VERSION "5.0.7"

NS_ :

BS_:

BU_: BMS EAC EVCC FMCU CVC_P PDU PTC CCU DUMMY_ECU

BO_ 128 ACU_ChimeTelltaleReq: 8 CVC_P
 SG_ ACU_CheckSum : 7|8@0+ (1,0) [0|255] ""  FMCU,PDU,PTC,EAC,CCU,BMS
 SG_ ACU_AliveCounter : 11|4@0+ (1,0) [0|15] ""  FMCU,PDU,PTC,EAC,CCU,BMS
 SG_ ACU_In_Disposal_Mode : 13|2@0+ (1,0) [0|3] ""  FMCU,PDU,PTC,EAC,CCU
 SG_ ACU_Malfunction : 15|2@0+ (1,0) [0|3] ""  FMCU,PDU,PTC,EAC,CCU
 SG_ ACU_DAirbagStatus : 17|2@0+ (1,0) [0|3] ""  FMCU,PDU,PTC,EAC,CCU
 SG_ ACU_CoDAirbagStatus : 19|2@0+ (1,0) [0|3] ""  FMCU,PDU,PTC,EAC,CCU
 SG_ ACU_LCABsts : 21|2@0+ (1,0) [0|3] ""  FMCU,PDU,PTC,EAC,CCU
 SG_ ACU_RCABsts : 23|2@0+ (1,0) [0|3] ""  FMCU,PDU,PTC,EAC,CCU
 SG_ ACU_LSABsts : 25|2@0+ (1,0) [0|3] ""  FMCU,PDU,PTC,EAC,CCU
 SG_ ACU_RSABsts : 27|2@0+ (1,0) [0|3] ""  FMCU,PDU,PTC,EAC,CCU
 SG_ ACU_CrashSts : 29|2@0+ (1,0) [0|3] ""  FMCU,PDU,PTC,EAC,CCU,BMS
 SG_ ACU_Development_Calibration : 31|2@0+ (1,0) [0|3] ""  FMCU,PDU,PTC,EAC,CCU
 SG_ ACU_AirbagWarningStatus : 33|2@0+ (1,0) [0|3] ""  FMCU,PDU,PTC,EAC,CCU
 SG_ ACU_pyro_fuse_Stat : 35|2@0+ (1,0) [0|3] ""  FMCU,PDU,PTC,EAC,CCU
 SG_ ACU_Airbag_Disabled : 37|2@0+ (1,0) [0|3] ""  FMCU,PDU,PTC,EAC,CCU
 SG_ ACU_In_Plant_Mode : 39|2@0+ (1,0) [0|3] ""  FMCU,PDU,PTC,EAC,CCU
 SG_ ACU_PBA_InhibitSts : 41|2@0+ (1,0) [0|3] ""  FMCU,PDU,PTC,EAC,CCU
 SG_ ACU_Pre_Drive_Check : 43|2@0+ (1,0) [0|3] ""  FMCU,PDU,PTC,EAC,CCU
 SG_ ACU_CrashRearOutputSts : 49|2@0+ (1,0) [0|3] ""  FMCU,PDU,PTC,EAC,CCU
 SG_ ACU_CrashRightOutputSts : 51|2@0+ (1,0) [0|3] ""  FMCU,PDU,PTC,EAC,CCU
 SG_ ACU_CrashLeftOutputSts : 53|2@0+ (1,0) [0|3] ""  FMCU,PDU,PTC,EAC,CCU
 SG_ ACU_CrashFrontOutputSts : 55|2@0+ (1,0) [0|3] ""  FMCU,PDU,PTC,EAC,CCU

BO_ 170 CVC_Sts1: 8 CVC_P
 SG_ CHSKM_CVC_Sts1 : 7|8@0+ (1,0) [0|255] ""  BMS
 SG_ ALV_CVC_Sts1 : 11|4@0+ (1,0) [0|15] ""  BMS
 SG_ CVC_BMS_HVOnOff_REQ : 19|2@0+ (1,0) [0|1] ""  BMS

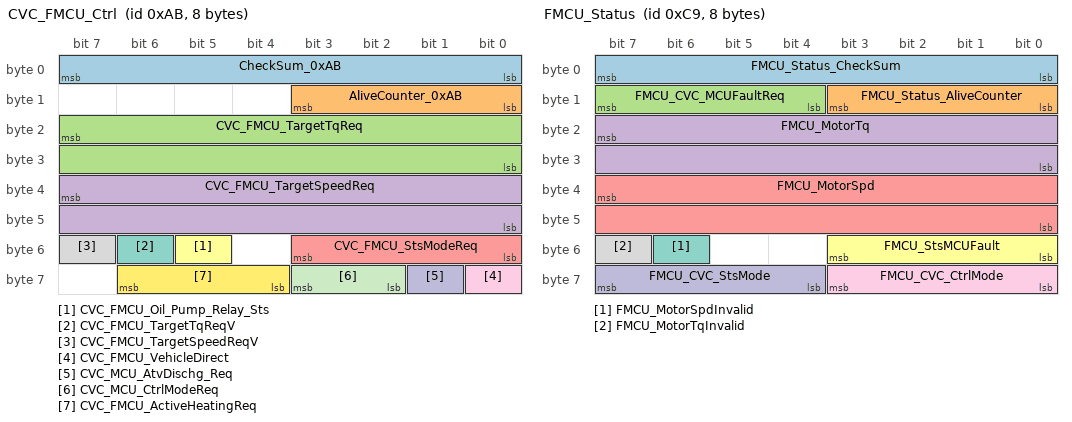
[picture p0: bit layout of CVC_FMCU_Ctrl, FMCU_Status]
BO_ 171 CVC_FMCU_Ctrl: 8 CVC_P
 SG_ CheckSum_0xAB : 7|8@0+ (1,0) [0|255] ""  FMCU
 SG_ AliveCounter_0xAB : 11|4@0+ (1,0) [0|15] ""  FMCU
 SG_ CVC_FMCU_TargetTqReq : 23|16@0+ (0.1,-400) [-400|400] "Nm"  FMCU
 SG_ CVC_FMCU_TargetSpeedReq : 39|16@0+ (1,-20000) [-20000|45535] "rpm"  FMCU
 SG_ CVC_FMCU_StsModeReq : 51|4@0+ (1,0) [0|15] ""  FMCU
 SG_ CVC_FMCU_Oil_Pump_Relay_Sts : 53|1@0+ (1,0) [0|1] ""  FMCU
 SG_ CVC_FMCU_TargetTqReqV : 54|1@0+ (1,0) [0|1] ""  FMCU
 SG_ CVC_FMCU_TargetSpeedReqV : 55|1@0+ (1,0) [0|1] ""  FMCU
 SG_ CVC_FMCU_VehicleDirect : 56|1@0+ (1,0) [0|1] ""  FMCU
 SG_ CVC_MCU_AtvDischg_Req : 57|1@0+ (1,0) [0|1] ""  FMCU
 SG_ CVC_MCU_CtrlModeReq : 59|2@0+ (1,0) [0|3] ""  FMCU
 SG_ CVC_FMCU_ActiveHeatingReq : 62|3@0+ (1,0) [0|8] "kW"  FMCU

BO_ 201 FMCU_Status: 8 FMCU
 SG_ FMCU_Status_CheckSum : 7|8@0+ (1,0) [0|255] ""  CVC_P,PDU,PTC,EAC
 SG_ FMCU_Status_AliveCounter : 11|4@0+ (1,0) [0|15] ""  CVC_P,PDU,PTC,EAC
 SG_ FMCU_CVC_MCUFaultReq : 15|4@0+ (1,0) [0|15] ""  CVC_P,PDU,PTC,EAC
 SG_ FMCU_MotorTq : 23|16@0+ (0.1,-400) [-400|400] "Nm"  CVC_P,PDU,PTC,EAC
 SG_ FMCU_MotorSpd : 39|16@0+ (1,-20000) [-20000|45531] "rpm"  CVC_P,PDU,PTC,EAC,EVCC,BMS,CCU
 SG_ FMCU_StsMCUFault : 51|4@0+ (1,0) [0|15] ""  CVC_P,PDU,PTC,EAC
 SG_ FMCU_MotorSpdInvalid : 54|1@0+ (1,0) [0|1] ""  CVC_P,PDU,PTC,EAC
 SG_ FMCU_MotorTqInvalid : 55|1@0+ (1,0) [0|1] ""  CVC_P,PDU,PTC,EAC
 SG_ FMCU_CVC_CtrlMode : 59|4@0+ (1,0) [0|15] ""  CVC_P,PDU,PTC,EAC
 SG_ FMCU_CVC_StsMode : 63|4@0+ (1,0) [0|15] ""  CVC_P,PDU,PTC,EAC

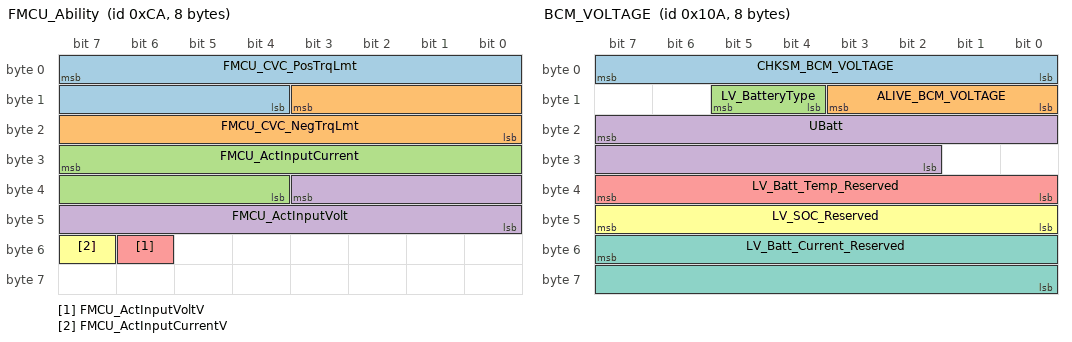
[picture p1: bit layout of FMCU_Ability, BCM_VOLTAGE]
BO_ 202 FMCU_Ability: 8 FMCU
 SG_ FMCU_CVC_PosTrqLmt : 7|12@0+ (0.1,0) [0|400] "Nm"  CVC_P,BMS
 SG_ FMCU_CVC_NegTrqLmt : 11|12@0+ (0.1,-400) [-400|0] "Nm"  CVC_P,BMS
 SG_ FMCU_ActInputCurrent : 31|12@0+ (0.5,-1000) [-1000|1000] "A"  CVC_P,BMS
 SG_ FMCU_ActInputVolt : 35|12@0+ (0.5,0) [0|1000] "V"  CVC_P,BMS
 SG_ FMCU_ActInputVoltV : 54|1@0+ (1,0) [0|1] ""  CVC_P,BMS
 SG_ FMCU_ActInputCurrentV : 55|1@0+ (1,0) [0|1] ""  CVC_P,BMS

BO_ 266 BCM_VOLTAGE: 8 CVC_P
 SG_ CHKSM_BCM_VOLTAGE : 7|8@0+ (1,0) [0|255] ""  EVCC,BMS,FMCU,PDU,CCU,PTC,EAC
 SG_ ALIVE_BCM_VOLTAGE : 11|4@0+ (1,0) [0|15] ""  EVCC,BMS,FMCU,PDU,CCU,PTC,EAC
 SG_ LV_BatteryType : 13|2@0+ (1,0) [0|3] "Number"  BMS,FMCU,PDU,CCU,PTC,EAC
 SG_ UBatt : 23|14@0+ (0.0009777,3) [3|18] "V"  EVCC,BMS,FMCU,PDU,CCU,PTC,EAC
 SG_ LV_Batt_Temp_Reserved : 39|8@0+ (1,-40) [-40|105] "Degree C"  BMS,FMCU,PDU,CCU,PTC,EAC
 SG_ LV_SOC_Reserved : 47|8@0+ (1,0) [0|100] "%"  BMS,FMCU,PDU,CCU,PTC,EAC
 SG_ LV_Batt_Current_Reserved : 55|16@0+ (0.03125,-1536) [-1536|511.90625] "A"  BMS,FMCU,PDU,CCU,PTC,EAC

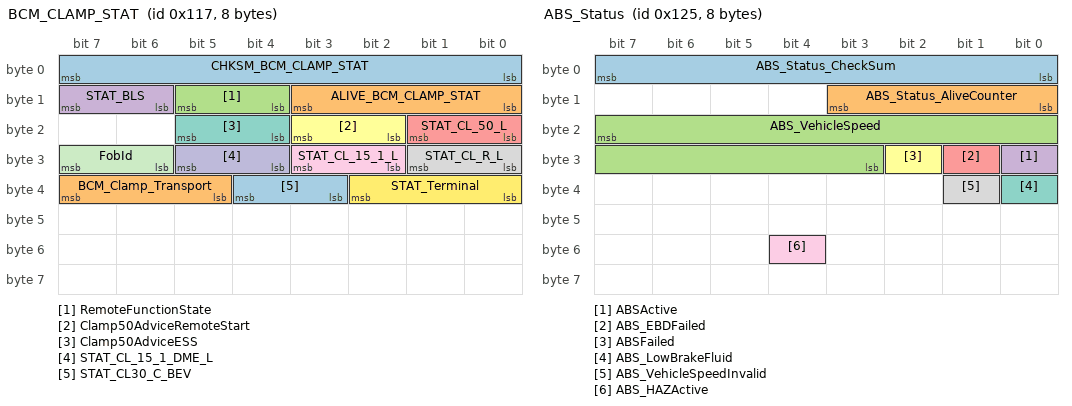
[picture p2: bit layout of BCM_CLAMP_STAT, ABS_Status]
BO_ 279 BCM_CLAMP_STAT: 8 CVC_P
 SG_ CHKSM_BCM_CLAMP_STAT : 7|8@0+ (1,0) [0|255] ""  EVCC,BMS
 SG_ ALIVE_BCM_CLAMP_STAT : 11|4@0+ (1,0) [0|15] ""  EVCC,BMS
 SG_ RemoteFunctionState : 13|2@0+ (1,0) [0|3] ""  EVCC,BMS
 SG_ STAT_BLS : 15|2@0+ (1,0) [0|3] "-"  EVCC,BMS
 SG_ STAT_CL_50_L : 17|2@0+ (1,0) [0|3] ""  EVCC,BMS
 SG_ Clamp50AdviceRemoteStart : 19|2@0+ (1,0) [0|3] "-"  EVCC,BMS
 SG_ Clamp50AdviceESS : 21|2@0+ (1,0) [0|3] "-"  EVCC,BMS
 SG_ STAT_CL_R_L : 25|2@0+ (1,0) [0|3] ""  EVCC,BMS
 SG_ STAT_CL_15_1_L : 27|2@0+ (1,0) [0|3] "-"  EVCC,BMS
 SG_ STAT_CL_15_1_DME_L : 29|2@0+ (1,0) [0|3] ""  EVCC,BMS
 SG_ FobId : 31|2@0+ (1,0) [0|3] "Bit"  EVCC,BMS
 SG_ STAT_Terminal : 34|3@0+ (1,0) [0|7] "Bit"  EVCC,BMS
 SG_ STAT_CL30_C_BEV : 36|2@0+ (1,0) [0|3] "Bit"  EVCC,BMS
 SG_ BCM_Clamp_Transport : 39|3@0+ (1,0) [0|7] ""  EVCC,BMS

BO_ 280 CVC_vehicle_118: 8 CVC_P
 SG_ CVC_VehicleSpeed : 7|13@0+ (0.05625,0) [0|270] "km/h"  PTC,BMS
 SG_ CVC_VehicleSpeedValid : 8|1@0+ (1,0) [0|1] ""  PTC,BMS
 SG_ CVC_HV_State : 10|2@0+ (1,0) [0|3] ""  PTC,BMS

BO_ 293 ABS_Status: 8 CVC_P
 SG_ ABS_Status_CheckSum : 7|8@0+ (1,0) [0|255] ""  FMCU,PDU,PTC,EAC,CCU,EVCC,BMS
 SG_ ABS_Status_AliveCounter : 11|4@0+ (1,0) [0|15] ""  FMCU,PDU,PTC,EAC,CCU,EVCC,BMS
 SG_ ABS_VehicleSpeed : 23|13@0+ (0.05625,0) [0|460.63125] "Km/h"  FMCU,PDU,PTC,EAC,CCU,EVCC,BMS
 SG_ ABSActive : 24|1@0+ (1,0) [0|1] ""  FMCU,PDU,PTC,EAC,CCU,EVCC,BMS
 SG_ ABS_EBDFailed : 25|1@0+ (1,0) [0|1] ""  FMCU,PDU,PTC,EAC,CCU,EVCC,BMS
 SG_ ABSFailed : 26|1@0+ (1,0) [0|1] ""  FMCU,PDU,PTC,EAC,CCU,EVCC,BMS
 SG_ ABS_LowBrakeFluid : 32|1@0+ (1,0) [0|1] ""  FMCU,PDU,PTC,EAC,CCU,EVCC,BMS
 SG_ ABS_VehicleSpeedInvalid : 33|1@0+ (1,0) [0|1] ""  FMCU,PDU,PTC,EAC,CCU,EVCC,BMS
 SG_ ABS_HAZActive : 52|1@0+ (1,0) [0|1] ""  FMCU,PDU,PTC,EAC,CCU,EVCC,BMS

BO_ 294 BMS_AllowChargeCurr: 8 BMS
 SG_ Checksum_0x126 : 7|8@0+ (1,0) [0|255] ""  CVC_P,EVCC
 SG_ Rolling_Counter_0x126 : 11|4@0+ (1,0) [0|15] ""  CVC_P,EVCC
 SG_ BMS_AllowChgCurr : 23|16@0+ (0.1,0) [0|1500] "A"  CVC_P,EVCC
 SG_ BMS_AllowChgCurrPeak : 39|16@0+ (0.1,0) [0|1500] "A"  CVC_P,EVCC

BO_ 296 BMS_AllowDischargeCurr: 8 BMS
 SG_ Checksum_0x128 : 7|8@0+ (1,0) [0|255] ""  CVC_P
 SG_ Rolling_Counter_0x128 : 11|4@0+ (1,0) [0|15] ""  CVC_P
 SG_ BMS_AllowDischgCurr : 23|16@0+ (0.1,0) [0|1500] "A"  CVC_P
 SG_ BMS_AllowDischgCurrPeak : 39|16@0+ (0.1,0) [0|1500] "A"  CVC_P

BO_ 306 ESC_Status_0x132: 8 CVC_P
 SG_ Checksum_0x132 : 7|8@0+ (1,0) [0|255] ""  FMCU
 SG_ RollingCounter_0x132 : 11|4@0+ (1,0) [0|15] ""  FMCU
 SG_ ESC_SlopeGradeAngle : 23|8@0+ (0.35433,-45) [-45|45] "%"  FMCU
 SG_ ESC_MasterCylinderPressure : 27|12@0+ (0.1,-100) [-100|309.4] "bar"  FMCU
 SG_ ESC_MasterCylinderPressureV : 28|1@0+ (1,0) [0|1] ""  FMCU
 SG_ ESC_HSA_Control_Status : 40|1@0+ (1,0) [0|1] ""  FMCU
 SG_ ESC_HSA_Status_Fault : 41|1@0+ (1,0) [0|1] ""  FMCU
 SG_ ESC_TcsDisableSts : 42|1@0+ (1,0) [0|1] ""  FMCU
 SG_ ESC_EscCtrlActv : 43|1@0+ (1,0) [0|1] ""  FMCU
 SG_ ESC_TcsCtrlActv : 44|1@0+ (1,0) [0|1] ""  FMCU
 SG_ ESC_EscFlgFlt : 45|1@0+ (1,0) [0|1] ""  FMCU
 SG_ ESC_TcsFlgFlt : 46|1@0+ (1,0) [0|1] ""  FMCU
 SG_ ESC_EscDisableSts : 47|1@0+ (1,0) [0|1] ""  FMCU
 SG_ ESC_HBAFlgFlt : 48|1@0+ (1,0) [0|1] ""  FMCU
 SG_ ESC_HbaCtrlActv : 49|1@0+ (1,0) [0|1] ""  FMCU
 SG_ BAS_FlgFlt : 50|1@0+ (1,0) [0|1] ""  FMCU
 SG_ BAS_CtrlActv : 51|1@0+ (1,0) [0|1] ""  FMCU
 SG_ IBS_ESCOFF_StsFB : 52|1@0+ (1,0) [0|1] ""  FMCU
 SG_ ESC_DTC_Active : 55|1@0+ (1,0) [0|1] ""  FMCU
 SG_ ESC_VehicleStandstill : 54|2@0+ (1,0) [0|3] ""  DUMMY_ECU

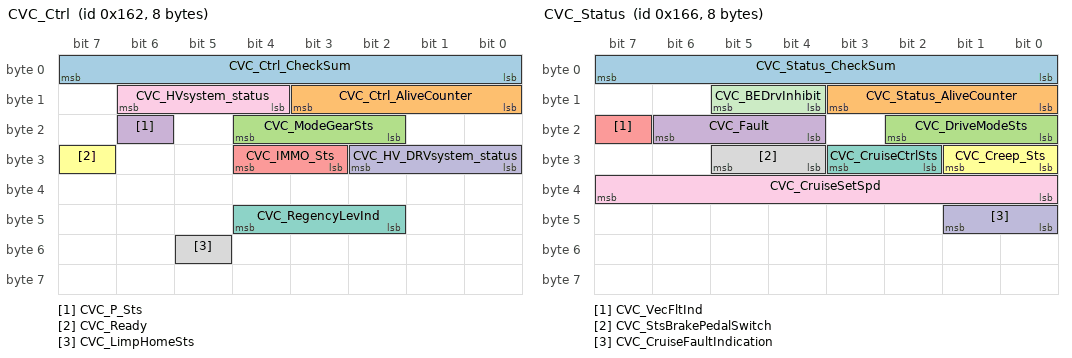
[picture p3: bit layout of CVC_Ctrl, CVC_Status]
BO_ 354 CVC_Ctrl: 8 CVC_P
 SG_ CVC_Ctrl_CheckSum : 7|8@0+ (1,0) [0|255] ""  FMCU,PDU,PTC,EAC,CCU,EVCC
 SG_ CVC_Ctrl_AliveCounter : 11|4@0+ (1,0) [0|15] ""  FMCU,PDU,PTC,EAC,CCU,EVCC
 SG_ CVC_ModeGearSts : 20|3@0+ (1,0) [0|7] ""  FMCU,PDU,PTC,EAC,CCU,EVCC
 SG_ CVC_P_Sts : 22|1@0+ (1,0) [0|1] ""  FMCU,PDU,PTC,EAC,CCU,EVCC
 SG_ CVC_IMMO_Sts : 28|2@0+ (1,0) [0|3] ""  FMCU,PDU,PTC,EAC,CCU,EVCC
 SG_ CVC_Ready : 31|1@0+ (1,0) [0|1] ""  FMCU,PDU,PTC,EAC,CCU,EVCC
 SG_ CVC_RegencyLevInd : 44|3@0+ (1,0) [0|7] ""  FMCU,PDU,PTC,EAC,CCU,EVCC
 SG_ CVC_LimpHomeSts : 53|1@0+ (1,0) [0|1] ""  FMCU,PDU,PTC,EAC,CCU,EVCC
 SG_ CVC_HVsystem_status : 14|3@0+ (1,0) [0|7] ""  FMCU,PDU,PTC,EAC,CCU,EVCC
 SG_ CVC_HV_DRVsystem_status : 26|3@0+ (1,0) [0|7] ""  FMCU,PDU,PTC,EAC,CCU,EVCC

BO_ 358 CVC_Status: 8 CVC_P
 SG_ CVC_Status_CheckSum : 7|8@0+ (1,0) [0|255] ""  FMCU
 SG_ CVC_Status_AliveCounter : 11|4@0+ (1,0) [0|15] ""  FMCU
 SG_ CVC_DriveModeSts : 18|3@0+ (1,0) [0|7] ""  FMCU
 SG_ CVC_Fault : 22|3@0+ (1,0) [0|7] ""  FMCU
 SG_ CVC_VecFltInd : 23|1@0+ (1,0) [0|1] ""  FMCU
 SG_ CVC_Creep_Sts : 25|2@0+ (1,0) [0|3] ""  FMCU
 SG_ CVC_CruiseCtrlSts : 27|2@0+ (1,0) [0|3] ""  FMCU
 SG_ CVC_StsBrakePedalSwitch : 29|2@0+ (1,0) [0|3] ""  FMCU
 SG_ CVC_CruiseSetSpd : 39|8@0+ (1,0) [30|120] ""  FMCU
 SG_ CVC_CruiseFaultIndication : 41|2@0+ (1,0) [0|3] ""  FMCU
 SG_ CVC_BEDrvInhibit : 13|2@0+ (1,0) [0|3] "" DUMMY_ECU

BO_ 1235 CVC_Debug: 8 CVC_P
 SG_ CHSKM_CVC_Debug : 7|8@0+ (1,0) [0|255] ""  DUMMY_ECU
 SG_ ALV_CVC_Debug : 11|4@0+ (1,0) [0|15] ""  DUMMY_ECU
 SG_ CVC_GearPOnlyAtStationaryAlert : 12|1@0+ (1,0) [0|1] ""  DUMMY_ECU
 SG_ CVC_GearP_NotPossibleAlert : 13|1@0+ (1,0) [0|1] ""  DUMMY_ECU
 SG_ CVC_PressBrakeToEngageGear : 14|1@0+ (1,0) [0|1] ""  DUMMY_ECU
 SG_ CVC_CantChangeGear : 15|1@0+ (1,0) [0|1] ""  DUMMY_ECU
 SG_ CVC_GearMalfunction : 16|1@0+ (1,0) [0|1] ""  DUMMY_ECU
 SG_ CVC_RangeAlert : 17|1@0+ (1,0) [0|1] ""  DUMMY_ECU
 SG_ CVC_HVSystemReduced : 18|1@0+ (1,0) [0|1] ""  DUMMY_ECU
 SG_ CVC_FrontEDSReduced : 19|1@0+ (1,0) [0|1] ""  DUMMY_ECU
 SG_ CVC_FrontEDS_Malfunc : 20|1@0+ (1,0) [0|1] ""  DUMMY_ECU
 SG_ CVC_RearEDSReduced : 21|1@0+ (1,0) [0|1] ""  DUMMY_ECU
 SG_ CVC_RearEDS_Malfunc : 22|1@0+ (1,0) [0|1] ""  DUMMY_ECU
 SG_ CVC_CoolingSystem_Malfunc : 45|3@0+ (1,0) [0|7] ""  DUMMY_ECU
 SG_ CVC_NeutralRequest : 24|1@0+ (1,0) [0|1] ""  DUMMY_ECU
 SG_ CVC_SoftShutdown : 25|1@0+ (1,0) [0|1] ""  DUMMY_ECU
 SG_ CVC_EmergencyShutdown : 26|1@0+ (1,0) [0|1] ""  DUMMY_ECU
 SG_ CVC_ChgPortDoorSys_Malfunc : 27|1@0+ (1,0) [0|1] ""  DUMMY_ECU
 SG_ CVC_Gearchange_NotPossible : 28|1@0+ (1,0) [0|1] ""  DUMMY_ECU
 SG_ CVC_12v_Warning : 29|1@0+ (1,0) [0|1] ""  DUMMY_ECU
 SG_ CVC_WflagRes19 : 30|1@0+ (1,0) [0|1] ""  DUMMY_ECU
 SG_ CVC_WflagRes20 : 31|1@0+ (1,0) [0|1] ""  DUMMY_ECU
 SG_ CVC_WflagRes21 : 32|1@0+ (1,0) [0|1] ""  DUMMY_ECU
 SG_ CVC_WflagRes22 : 33|1@0+ (1,0) [0|1] ""  DUMMY_ECU
 SG_ CVC_WflagRes23 : 34|1@0+ (1,0) [0|1] ""  DUMMY_ECU
 SG_ CVC_WflagRes24 : 35|1@0+ (1,0) [0|1] ""  DUMMY_ECU
 SG_ CVC_WflagRes25 : 36|1@0+ (1,0) [0|1] ""  DUMMY_ECU
 SG_ CVC_WflagRes26 : 37|1@0+ (1,0) [0|1] ""  DUMMY_ECU
 SG_ CVC_WflagRes27 : 38|1@0+ (1,0) [0|1] ""  DUMMY_ECU
 SG_ CVC_SuperFastCharge_longer : 39|1@0+ (1,0) [0|1] ""  DUMMY_ECU
 SG_ CVC_InvalidLimitSpeed : 46|1@0+ (1,0) [0|1] ""  DUMMY_ECU
 SG_ CVC_InvalidCruiseSpeed : 47|1@0+ (1,0) [0|1] ""  DUMMY_ECU
 SG_ CVC_Reserved_signal2 : 55|8@0+ (1,0) [0|255] ""  DUMMY_ECU
 SG_ CVC_Reserved_signal3 : 63|8@0+ (1,0) [0|255] ""  DUMMY_ECU

BO_ 1237 CVC_Debug_1: 8 CVC_P
 SG_ CVC_DebugAsw1 : 7|8@0+ (1,0) [0|255] ""  DUMMY_ECU
 SG_ CVC_DebugAsw2 : 10|3@0+ (1,0) [0|4] ""  DUMMY_ECU
 SG_ CVC_DebugAsw3 : 13|3@0+ (1,0) [0|4] ""  DUMMY_ECU
 SG_ CVC_DebugAsw4 : 18|3@0+ (1,0) [0|4] ""  DUMMY_ECU
 SG_ CVC_DebugAsw5 : 21|3@0+ (1,0) [0|4] ""  DUMMY_ECU
 SG_ CVC_DebugAsw6 : 28|3@0+ (1,0) [0|4] ""  DUMMY_ECU
 SG_ CVC_DebugAsw7 : 31|3@0+ (1,0) [0|4] ""  DUMMY_ECU
 SG_ CVC_DebugAsw8 : 55|3@0+ (1,0) [0|4] ""  DUMMY_ECU
 SG_ CVC_DebugAsw9 : 52|4@0+ (1,0) [0|15] ""  DUMMY_ECU
 SG_ CVC_DebugAsw10 : 63|4@0+ (1,0) [0|15] ""  DUMMY_ECU
 SG_ CVC_DebugAsw11 : 59|4@0+ (1,0) [0|15] ""  DUMMY_ECU
 SG_ CVC_DebugAsw12 : 39|8@0+ (1,0) [0|255] ""  DUMMY_ECU
 SG_ CVC_DebugAsw13 : 23|1@0+ (1,0) [0|1] ""  DUMMY_ECU
 SG_ CVC_DebugAsw14 : 22|1@0+ (1,0) [0|1] ""  DUMMY_ECU
 SG_ CVC_DebugAsw15 : 25|1@0+ (1,0) [0|1] ""  DUMMY_ECU
 SG_ CVC_DebugAsw16 : 24|1@0+ (1,0) [0|1] ""  DUMMY_ECU
 SG_ CVC_DebugAsw17 : 15|1@0+ (1,0) [0|1] ""  DUMMY_ECU
 SG_ CVC_DebugAsw18 : 14|1@0+ (1,0) [0|1] ""  DUMMY_ECU
 SG_ CVC_DebugAsw19 : 48|1@0+ (1,0) [0|1] ""  DUMMY_ECU

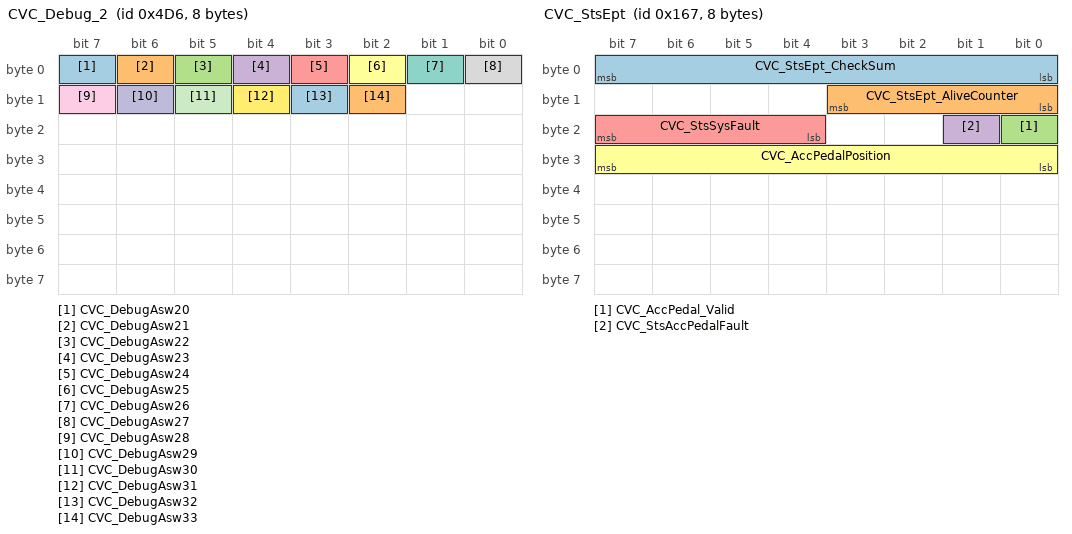
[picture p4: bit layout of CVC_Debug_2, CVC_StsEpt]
BO_ 1238 CVC_Debug_2: 8 CVC_P
 SG_ CVC_DebugAsw20 : 7|1@0+ (1,0) [0|1] ""  DUMMY_ECU
 SG_ CVC_DebugAsw21 : 6|1@0+ (1,0) [0|1] ""  DUMMY_ECU
 SG_ CVC_DebugAsw22 : 5|1@0+ (1,0) [0|1] ""  DUMMY_ECU
 SG_ CVC_DebugAsw23 : 4|1@0+ (1,0) [0|1] ""  DUMMY_ECU
 SG_ CVC_DebugAsw24 : 3|1@0+ (1,0) [0|1] ""  DUMMY_ECU
 SG_ CVC_DebugAsw25 : 2|1@0+ (1,0) [0|1] ""  DUMMY_ECU
 SG_ CVC_DebugAsw26 : 1|1@0+ (1,0) [0|1] ""  DUMMY_ECU
 SG_ CVC_DebugAsw27 : 0|1@0+ (1,0) [0|1] ""  DUMMY_ECU
 SG_ CVC_DebugAsw28 : 15|1@0+ (1,0) [0|1] ""  DUMMY_ECU
 SG_ CVC_DebugAsw29 : 14|1@0+ (1,0) [0|1] ""  DUMMY_ECU
 SG_ CVC_DebugAsw30 : 13|1@0+ (1,0) [0|1] ""  DUMMY_ECU
 SG_ CVC_DebugAsw31 : 12|1@0+ (1,0) [0|1] ""  DUMMY_ECU
 SG_ CVC_DebugAsw32 : 11|1@0+ (1,0) [0|1] ""  DUMMY_ECU
 SG_ CVC_DebugAsw33 : 10|1@0+ (1,0) [0|1] ""  DUMMY_ECU

BO_ 1873 CVC_DebugDiag: 8 CVC_P
 SG_ CVC_DebugDiag2 : 4|3@0+ (1,0) [0|4] ""  DUMMY_ECU
 SG_ CVC_DebugDiag1 : 7|3@0+ (1,0) [0|4] ""  DUMMY_ECU
 SG_ CVC_DebugDiag5 : 9|3@0+ (1,0) [0|4] ""  DUMMY_ECU
 SG_ CVC_DebugDiag4 : 12|3@0+ (1,0) [0|4] ""  DUMMY_ECU
 SG_ CVC_DebugDiag3 : 15|3@0+ (1,0) [0|4] ""  DUMMY_ECU
 SG_ CVC_DebugDiag8 : 16|3@0+ (1,0) [0|4] ""  DUMMY_ECU
 SG_ CVC_DebugDiag7 : 19|3@0+ (1,0) [0|4] ""  DUMMY_ECU
 SG_ CVC_DebugDiag6 : 22|3@0+ (1,0) [0|4] ""  DUMMY_ECU
 SG_ CVC_DebugDiag10 : 26|3@0+ (1,0) [0|4] ""  DUMMY_ECU
 SG_ CVC_DebugDiag9 : 29|3@0+ (1,0) [0|4] ""  DUMMY_ECU
 SG_ CVC_DebugDiag13 : 33|3@0+ (1,0) [0|4] ""  DUMMY_ECU
 SG_ CVC_DebugDiag12 : 36|3@0+ (1,0) [0|4] ""  DUMMY_ECU
 SG_ CVC_DebugDiag11 : 39|3@0+ (1,0) [0|4] ""  DUMMY_ECU
 SG_ CVC_DebugDiag16 : 40|3@0+ (1,0) [0|4] ""  DUMMY_ECU
 SG_ CVC_DebugDiag15 : 43|3@0+ (1,0) [0|4] ""  DUMMY_ECU
 SG_ CVC_DebugDiag14 : 46|3@0+ (1,0) [0|4] ""  DUMMY_ECU
 SG_ CVC_DebugDiag18 : 50|3@0+ (1,0) [0|4] ""  DUMMY_ECU
 SG_ CVC_DebugDiag17 : 53|3@0+ (1,0) [0|4] ""  DUMMY_ECU
 SG_ CVC_DebugDiag20 : 60|3@0+ (1,0) [0|4] ""  DUMMY_ECU
 SG_ CVC_DebugDiag19 : 63|3@0+ (1,0) [0|4] ""  DUMMY_ECU

BO_ 359 CVC_StsEpt: 8 CVC_P
 SG_ CVC_StsEpt_CheckSum : 7|8@0+ (1,0) [0|255] ""  FMCU
 SG_ CVC_StsEpt_AliveCounter : 11|4@0+ (1,0) [0|15] ""  FMCU
 SG_ CVC_AccPedal_Valid : 16|1@0+ (1,0) [0|1] ""  FMCU
 SG_ CVC_StsAccPedalFault : 17|1@0+ (1,0) [0|1] ""  FMCU
 SG_ CVC_StsSysFault : 23|4@0+ (1,0) [0|15] ""  FMCU
 SG_ CVC_AccPedalPosition : 31|8@0+ (0.4,0) [0|100] "%"  FMCU

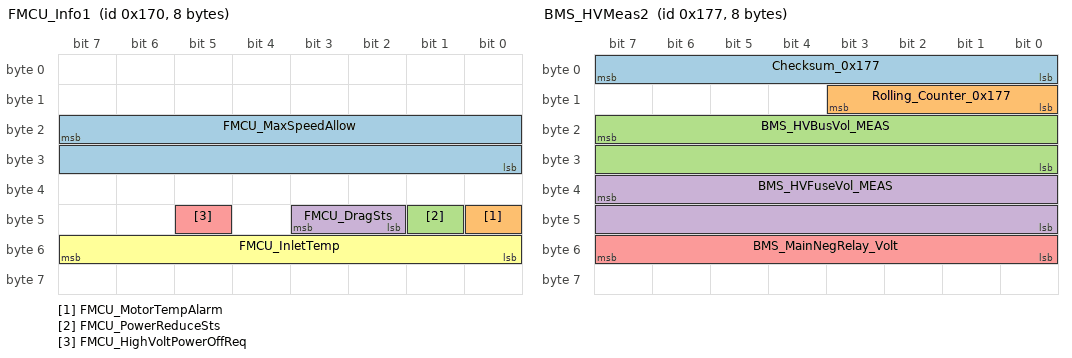
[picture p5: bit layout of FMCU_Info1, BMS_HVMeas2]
BO_ 368 FMCU_Info1: 8 FMCU
 SG_ FMCU_MaxSpeedAllow : 23|16@0+ (1,-17000) [-17000|17000] "rpm"  CVC_P
 SG_ FMCU_MotorTempAlarm : 40|1@0+ (1,0) [0|1] ""  CVC_P
 SG_ FMCU_PowerReduceSts : 41|1@0+ (1,0) [0|1] ""  CVC_P
 SG_ FMCU_DragSts : 43|2@0+ (1,0) [0|3] ""  CVC_P
 SG_ FMCU_HighVoltPowerOffReq : 45|1@0+ (1,0) [0|1] ""  CVC_P
 SG_ FMCU_InletTemp : 55|8@0+ (1,-50) [-50|200] "Degree C"  CVC_P

BO_ 372 BMS_CurMeas: 8 BMS
 SG_ CHSKM_BMS_CurMeas : 7|8@0+ (1,0) [0|255] ""  PDU,CVC_P,EVCC
 SG_ ALV_BMS_CurMeas : 11|4@0+ (1,0) [0|15] ""  PDU,CVC_P,EVCC
 SG_ BMS_StartOfMeasument_STS : 15|1@0+ (1,0) [0|1] ""  PDU,CVC_P
 SG_ BMS_PackCur_MEAS : 23|16@0+ (0.1,-3276.8) [-3276.8|3276.7] "A"  PDU,CVC_P,EVCC,FMCU

BO_ 374 BMS_HVMeas1: 8 BMS
 SG_ Checksum_0x176 : 7|8@0+ (1,0) [0|255] ""  FMCU,CVC_P,EVCC
 SG_ Rolling_Counter_0x176 : 11|4@0+ (1,0) [0|15] ""  FMCU,CVC_P,EVCC
 SG_ BMS_HVPackVol_MEAS : 23|16@0+ (0.1,0) [0|800] "V"  FMCU,CVC_P,EVCC
 SG_ BMS_HVLinkVol_MEAS : 39|16@0+ (0.1,0) [0|800] "V"  FMCU,CVC_P

BO_ 375 BMS_HVMeas2: 8 BMS
 SG_ Checksum_0x177 : 7|8@0+ (1,0) [0|255] ""  CVC_P,EVCC
 SG_ Rolling_Counter_0x177 : 11|4@0+ (1,0) [0|15] ""  CVC_P,EVCC
 SG_ BMS_HVBusVol_MEAS : 23|16@0+ (0.1,0) [0|800] "V"  CVC_P,EVCC
 SG_ BMS_HVFuseVol_MEAS : 39|16@0+ (0.1,0) [0|800] "V"  CVC_P,EVCC
 SG_ BMS_MainNegRelay_Volt : 55|8@0+ (0.1,0) [0|5] ""  CVC_P,EVCC

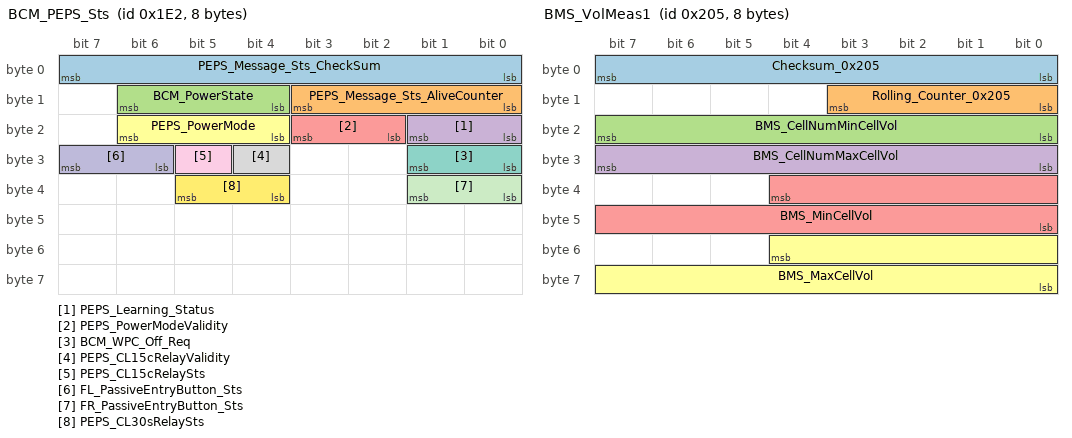
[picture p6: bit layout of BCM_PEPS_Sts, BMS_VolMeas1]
BO_ 482 BCM_PEPS_Sts: 8 CVC_P
 SG_ PEPS_Message_Sts_CheckSum : 7|8@0+ (1,0) [0|255] ""  PTC,BMS,FMCU,CCU
 SG_ PEPS_Message_Sts_AliveCounter : 11|4@0+ (1,0) [0|15] ""  PTC,BMS,FMCU,CCU
 SG_ BCM_PowerState : 14|3@0+ (1,0) [0|7] ""  PTC
 SG_ PEPS_Learning_Status : 17|2@0+ (1,0) [0|3] ""  PTC,BMS,FMCU,CCU
 SG_ PEPS_PowerModeValidity : 19|2@0+ (1,0) [0|3] ""  PTC,BMS,FMCU,CCU
 SG_ PEPS_PowerMode : 22|3@0+ (1,0) [0|7] ""  PTC,BMS,FMCU,CCU
 SG_ BCM_WPC_Off_Req : 25|2@0+ (1,0) [0|3] ""  PTC,BMS,FMCU,CCU
 SG_ PEPS_CL15cRelayValidity : 28|1@0+ (1,0) [0|1] ""  PTC,BMS,FMCU,CCU
 SG_ PEPS_CL15cRelaySts : 29|1@0+ (1,0) [0|1] ""  PTC,BMS,FMCU,CCU
 SG_ FL_PassiveEntryButton_Sts : 31|2@0+ (1,0) [0|3] "" DUMMY_ECU
 SG_ FR_PassiveEntryButton_Sts : 33|2@0+ (1,0) [0|3] "" DUMMY_ECU
 SG_ PEPS_CL30sRelaySts : 37|2@0+ (1,0) [0|3] "" DUMMY_ECU

BO_ 517 BMS_VolMeas1: 8 BMS
 SG_ Checksum_0x205 : 7|8@0+ (1,0) [0|255] ""  CVC_P
 SG_ Rolling_Counter_0x205 : 11|4@0+ (1,0) [0|15] ""  CVC_P
 SG_ BMS_CellNumMinCellVol : 23|8@0+ (1,0) [0|255] ""  CVC_P
 SG_ BMS_CellNumMaxCellVol : 31|8@0+ (1,0) [0|255] ""  CVC_P
 SG_ BMS_MinCellVol : 36|13@0+ (0.001,0) [0|6] "V"  CVC_P
 SG_ BMS_MaxCellVol : 52|13@0+ (0.001,0) [0|6] "V"  CVC_P

BO_ 518 BMS_VolMeas2: 8 BMS
 SG_ Checksum_0x206 : 7|8@0+ (1,0) [0|255] ""  CVC_P
 SG_ Rolling_Counter_0x206 : 11|4@0+ (1,0) [0|15] ""  CVC_P
 SG_ BMS_MaxMinDiffCellVol : 20|13@0+ (0.001,0) [0|2] "V"  CVC_P

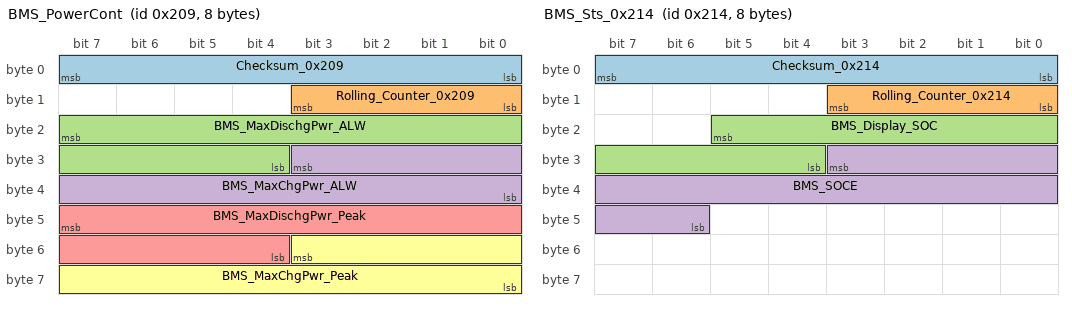
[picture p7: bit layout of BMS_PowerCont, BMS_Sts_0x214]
BO_ 521 BMS_PowerCont: 8 BMS
 SG_ Checksum_0x209 : 7|8@0+ (1,0) [0|255] ""  CVC_P,FMCU
 SG_ Rolling_Counter_0x209 : 11|4@0+ (1,0) [0|15] ""  CVC_P,FMCU
 SG_ BMS_MaxDischgPwr_ALW : 23|12@0+ (0.1,0) [0|400] "kW"  CVC_P,FMCU
 SG_ BMS_MaxChgPwr_ALW : 27|12@0+ (0.1,0) [0|400] "kW"  CVC_P,FMCU
 SG_ BMS_MaxDischgPwr_Peak : 47|12@0+ (0.2,0) [0|800] "kW"  CVC_P,FMCU
 SG_ BMS_MaxChgPwr_Peak : 51|12@0+ (0.2,0) [0|800] "kW"  CVC_P,FMCU

BO_ 532 BMS_Sts_0x214: 8 BMS
 SG_ Checksum_0x214 : 7|8@0+ (1,0) [0|255] ""  CVC_P,EVCC
 SG_ Rolling_Counter_0x214 : 11|4@0+ (1,0) [0|15] ""  CVC_P,EVCC
 SG_ BMS_Display_SOC : 21|10@0+ (0.1,0) [0|100] "%"  CVC_P,EVCC,FMCU
 SG_ BMS_SOCE : 27|14@0+ (0.01,0) [0|100] "%"  CVC_P

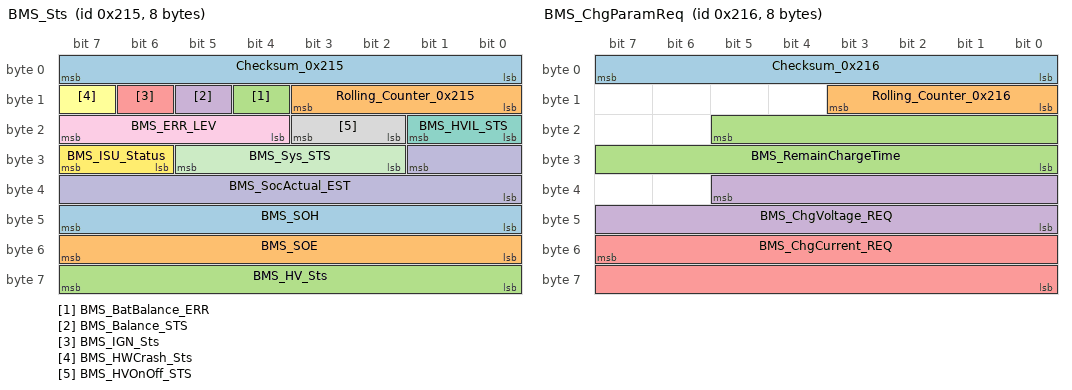
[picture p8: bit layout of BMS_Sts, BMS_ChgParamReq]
BO_ 533 BMS_Sts: 8 BMS
 SG_ Checksum_0x215 : 7|8@0+ (1,0) [0|255] ""  FMCU,PDU,CVC_P,EVCC,CCU
 SG_ Rolling_Counter_0x215 : 11|4@0+ (1,0) [0|15] ""  FMCU,PDU,CVC_P,EVCC,CCU
 SG_ BMS_BatBalance_ERR : 12|1@0+ (1,0) [0|1] ""  PDU,CVC_P,EVCC,CCU
 SG_ BMS_Balance_STS : 13|1@0+ (1,0) [0|1] ""  PDU,CVC_P,EVCC,FMCU,CCU
 SG_ BMS_IGN_Sts : 14|1@0+ (1,0) [0|1] ""  PDU,CVC_P,EVCC,CCU
 SG_ BMS_HWCrash_Sts : 15|1@0+ (1,0) [0|1] ""  PDU,CVC_P,EVCC,FMCU,CCU
 SG_ BMS_HVIL_STS : 17|2@0+ (1,0) [0|3] ""  PDU,CVC_P,EVCC,FMCU,CCU
 SG_ BMS_HVOnOff_STS : 19|2@0+ (1,0) [0|3] ""  PDU,CVC_P,EVCC,FMCU,CCU
 SG_ BMS_ERR_LEV : 23|4@0+ (1,0) [0|7] "-"  PDU,CVC_P,EVCC,FMCU,CCU
 SG_ BMS_SocActual_EST : 25|10@0+ (0.1,0) [0|100] "%"  PDU,CVC_P,EVCC,FMCU,CCU
 SG_ BMS_Sys_STS : 29|4@0+ (1,0) [0|15] ""  FMCU,PDU,CVC_P,EVCC,CCU
 SG_ BMS_ISU_Status : 31|2@0+ (1,0) [0|3] ""  PDU,CVC_P,EVCC,FMCU,CCU
 SG_ BMS_SOH : 47|8@0+ (0.5,0) [0|100] "%"  PDU,CVC_P,EVCC,FMCU,CCU
 SG_ BMS_SOE : 55|8@0+ (0.5,0) [0|100] "%"  PDU,CVC_P,EVCC,FMCU,CCU
 SG_ BMS_HV_Sts : 63|8@0+ (1,0) [0|255] ""  PDU,EVCC,CCU

BO_ 534 BMS_ChgParamReq: 8 BMS
 SG_ Checksum_0x216 : 7|8@0+ (1,0) [0|255] ""  CVC_P,EVCC
 SG_ Rolling_Counter_0x216 : 11|4@0+ (1,0) [0|15] ""  CVC_P,EVCC
 SG_ BMS_RemainChargeTime : 21|14@0+ (1,0) [0|16383] "min"  CVC_P,EVCC
 SG_ BMS_ChgVoltage_REQ : 37|14@0+ (0.1,0) [0|800] "V"  CVC_P,EVCC
 SG_ BMS_ChgCurrent_REQ : 55|16@0+ (0.1,0) [0|1500] "A"  CVC_P,EVCC

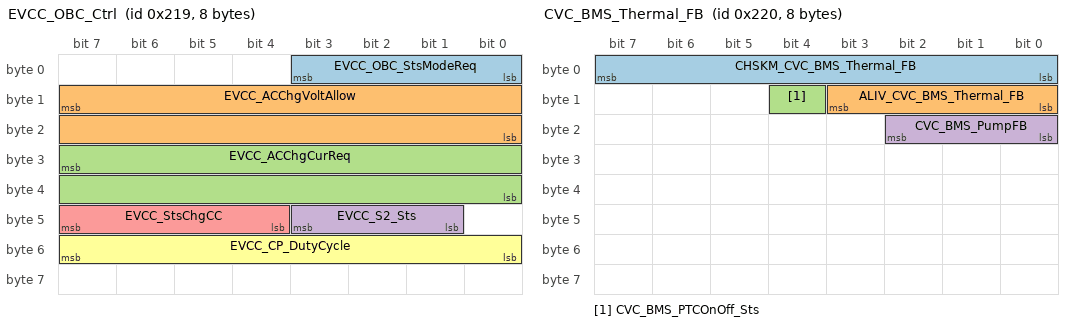
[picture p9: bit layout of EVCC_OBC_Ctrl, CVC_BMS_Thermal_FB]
BO_ 537 EVCC_OBC_Ctrl: 8 EVCC
 SG_ EVCC_OBC_StsModeReq : 3|4@0+ (1,0) [0|15] "-"  CVC_P,PDU
 SG_ EVCC_ACChgVoltAllow : 15|16@0+ (0.1,0) [0|1000] "V"  CVC_P,PDU
 SG_ EVCC_ACChgCurReq : 31|16@0+ (0.1,-1000) [-1000|1000] "A"  CVC_P,PDU
 SG_ EVCC_S2_Sts : 43|3@0+ (1,0) [0|7] "-"  CVC_P,PDU
 SG_ EVCC_StsChgCC : 47|4@0+ (1,0) [0|15] "-"  CVC_P,PDU
 SG_ EVCC_CP_DutyCycle : 55|8@0+ (0.4,0) [0|100] "%"  CVC_P,PDU

BO_ 544 CVC_BMS_Thermal_FB: 8 CVC_P
 SG_ CHSKM_CVC_BMS_Thermal_FB : 7|8@0+ (1,0) [0|255] ""  BMS
 SG_ ALIV_CVC_BMS_Thermal_FB : 11|4@0+ (1,0) [0|15] ""  BMS
 SG_ CVC_BMS_PTCOnOff_Sts : 12|1@0+ (1,0) [0|1] ""  BMS
 SG_ CVC_BMS_PumpFB : 18|3@0+ (1,0) [0|3] ""  BMS

BO_ 549 BMS_FaultMgr_0x225: 8 BMS
 SG_ Checksum_0x225 : 7|8@0+ (1,0) [0|255] ""  CVC_P
 SG_ Rolling_Counter_0x225 : 11|4@0+ (1,0) [0|15] ""  CVC_P
 SG_ CDM_bAcvCanComStblMon : 12|1@0+ (1,0) [0|1] ""  CVC_P
 SG_ FRMo_bErrHvbatStReqExtMon : 13|1@0+ (1,0) [0|1] ""  CVC_P
 SG_ FRMo_bErrChrgnAllwdExtMon : 14|1@0+ (1,0) [0|1] ""  CVC_P
 SG_ FRMo_bErrVehCrashStExtMon : 15|1@0+ (1,0) [0|1] ""  CVC_P
 SG_ CDM_bErrComctnLossCanMon : 16|1@0+ (1,0) [0|1] ""  CVC_P
 SG_ CTCMon_bErrCtctrSopcMon : 17|1@0+ (1,0) [0|1] ""  CVC_P
 SG_ CTCMon_bInvldCtctrHisdIFbMon : 18|1@0+ (1,0) [0|1] ""  CVC_P
 SG_ CTCMon_bInvldCtctrLosdUFbMon : 19|1@0+ (1,0) [0|1] ""  CVC_P
 SG_ CTM_bErrCellTDifMaxMon : 20|1@0+ (1,0) [0|1] ""  CVC_P
 SG_ CTM_bErrCellTMaxMon : 21|1@0+ (1,0) [0|1] ""  CVC_P
 SG_ CTM_bErrCellTMinMon : 22|1@0+ (1,0) [0|1] ""  CVC_P
 SG_ CTM_bErrThrwyPredMon : 23|1@0+ (1,0) [0|1] ""  CVC_P
 SG_ CUM_bErrCellUDifMaxMon : 24|1@0+ (1,0) [0|1] ""  CVC_P
 SG_ CUM_bErrCellUMaxMon : 25|1@0+ (1,0) [0|1] ""  CVC_P
 SG_ CUM_bErrCellUMinMon : 26|1@0+ (1,0) [0|1] ""  CVC_P
 SG_ CUM_bErrCellUProtnMaxNvMon : 27|1@0+ (1,0) [0|1] ""  CVC_P
 SG_ CUM_bErrCellUProtnMinNvMon : 28|1@0+ (1,0) [0|1] ""  CVC_P
 SG_ CUM_bErrPackUImplyMon : 29|1@0+ (1,0) [0|1] ""  CVC_P
 SG_ EHPMon_bRdyHvilMon : 30|1@0+ (1,0) [0|1] ""  CVC_P
 SG_ EHPMon_bErrWlddNegNvMon : 31|1@0+ (1,0) [0|1] ""  CVC_P
 SG_ EHPMon_bErrWlddPosNvMon : 32|1@0+ (1,0) [0|1] ""  CVC_P
 SG_ EHPMon_bErrWlddPrechNvMon : 33|1@0+ (1,0) [0|1] ""  CVC_P
 SG_ EHPMon_bErrHvilMon : 34|1@0+ (1,0) [0|1] ""  CVC_P
 SG_ EHPMon_bErrHvilShoMon : 35|1@0+ (1,0) [0|1] ""  CVC_P
 SG_ EHPMon_bErrPackIslnRNvMon : 36|1@0+ (1,0) [0|1] ""  CVC_P
 SG_ EHPMon_bErrVehCrashNvMon : 37|1@0+ (1,0) [0|1] ""  CVC_P
 SG_ EHPMon_bErrVehIslnRNvMon : 38|1@0+ (1,0) [0|1] ""  CVC_P
 SG_ FRMo_bErrMemStorgNvMon : 39|1@0+ (1,0) [0|1] ""  CVC_P
 SG_ L1IM_bErrClmp30MaxMonInp : 40|1@0+ (1,0) [0|1] ""  CVC_P
 SG_ L1IM_bErrClmp30MinMonInp : 41|1@0+ (1,0) [0|1] ""  CVC_P
 SG_ L1IM_bErrCtctrDtrtMonInp : 42|1@0+ (1,0) [0|1] ""  CVC_P
 SG_ L1IM_bErrUActImplyMonInp : 43|1@0+ (1,0) [0|1] ""  CVC_P
 SG_ MCCM_bAcvMdulCtlrStsMon : 44|1@0+ (1,0) [0|1] ""  CVC_P
 SG_ MCCM_bErrLntecSngFltMon : 45|1@0+ (1,0) [0|1] ""  CVC_P
 SG_ MCCM_bErrLntecLtntFltMon : 46|1@0+ (1,0) [0|1] ""  CVC_P
 SG_ MCCM_bErrMdulCellSnsrCfgMon : 47|1@0+ (1,0) [0|1] ""  CVC_P
 SG_ MCCM_bErrMdulCtlrComMon : 48|1@0+ (1,0) [0|1] ""  CVC_P
 SG_ MCCM_bErrSnsrTEltlMon : 49|1@0+ (1,0) [0|1] ""  CVC_P
 SG_ MCCM_bWarnSnsrTEltlMon : 50|1@0+ (1,0) [0|1] ""  CVC_P
 SG_ PCM_bRdySnsrIMon : 51|1@0+ (1,0) [0|1] ""  CVC_P
 SG_ PCM_bErrPackEFlowMaxLimMon : 52|1@0+ (1,0) [0|1] ""  CVC_P
 SG_ PCM_bErrPackIChDchaMaxLimMon : 53|1@0+ (1,0) [0|1] ""  CVC_P
 SG_ PCM_bErrSnsrIImplyMon : 54|1@0+ (1,0) [0|1] ""  CVC_P
 SG_ FRMo_bErrSnsrI1ExtMon : 55|1@0+ (1,0) [0|1] ""  CVC_P
 SG_ PCM_bInvldSnsrI1Mon : 56|1@0+ (1,0) [0|1] ""  CVC_P
 SG_ PCM_bInvldSnsrI2Mon : 57|1@0+ (1,0) [0|1] ""  CVC_P
 SG_ FRMo_bErrSopcLvl3Mon : 58|1@0+ (1,0) [0|1] ""  CVC_P
 SG_ BMS_FRMo_Reserved_1 : 59|1@0+ (1,0) [0|1] ""  CVC_P
 SG_ BMS_FRMo_Reserved_2 : 60|1@0+ (1,0) [0|1] ""  CVC_P
 SG_ BMS_FRMo_Reserved_3 : 61|1@0+ (1,0) [0|1] ""  CVC_P
 SG_ BMS_FRMo_Reserved_4 : 62|1@0+ (1,0) [0|1] ""  CVC_P
 SG_ BMS_FRMo_Reserved_5 : 63|1@0+ (1,0) [0|1] ""  CVC_P

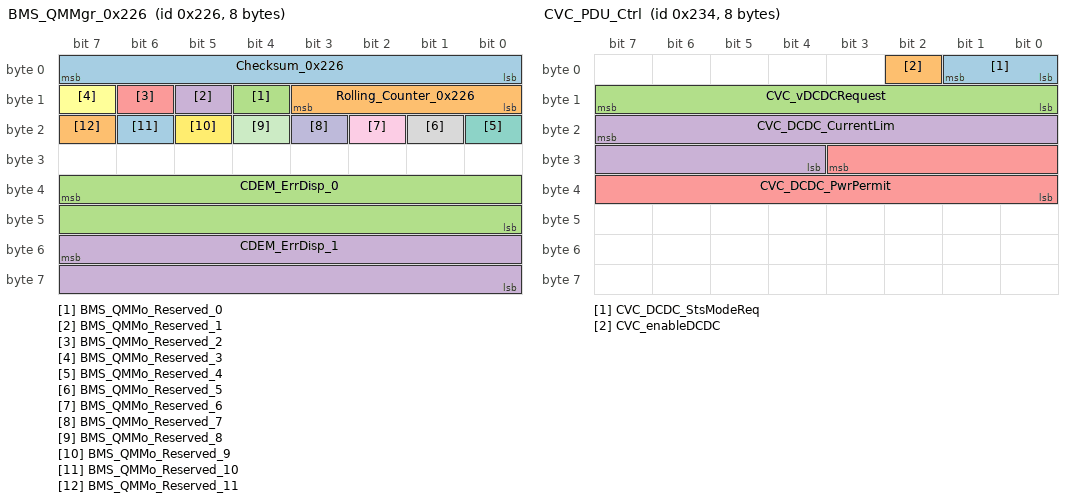
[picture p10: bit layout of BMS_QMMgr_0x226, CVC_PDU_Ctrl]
BO_ 550 BMS_QMMgr_0x226: 8 BMS
 SG_ Checksum_0x226 : 7|8@0+ (1,0) [0|255] "" Vector__XXX
 SG_ Rolling_Counter_0x226 : 11|4@0+ (1,0) [0|15] "" Vector__XXX
 SG_ BMS_QMMo_Reserved_0 : 12|1@0+ (1,0) [0|1] "" Vector__XXX
 SG_ BMS_QMMo_Reserved_1 : 13|1@0+ (1,0) [0|1] "" Vector__XXX
 SG_ BMS_QMMo_Reserved_2 : 14|1@0+ (1,0) [0|1] "" Vector__XXX
 SG_ BMS_QMMo_Reserved_3 : 15|1@0+ (1,0) [0|1] "" Vector__XXX
 SG_ BMS_QMMo_Reserved_4 : 16|1@0+ (1,0) [0|1] "" Vector__XXX
 SG_ BMS_QMMo_Reserved_5 : 17|1@0+ (1,0) [0|1] "" Vector__XXX
 SG_ BMS_QMMo_Reserved_6 : 18|1@0+ (1,0) [0|1] "" Vector__XXX
 SG_ BMS_QMMo_Reserved_7 : 19|1@0+ (1,0) [0|1] "" Vector__XXX
 SG_ BMS_QMMo_Reserved_8 : 20|1@0+ (1,0) [0|1] "" Vector__XXX
 SG_ BMS_QMMo_Reserved_9 : 21|1@0+ (1,0) [0|1] "" Vector__XXX
 SG_ BMS_QMMo_Reserved_10 : 22|1@0+ (1,0) [0|1] "" Vector__XXX
 SG_ BMS_QMMo_Reserved_11 : 23|1@0+ (1,0) [0|1] "" Vector__XXX
 SG_ CDEM_ErrDisp_0 : 39|16@0+ (1,0) [0|65535] "" Vector__XXX
 SG_ CDEM_ErrDisp_1 : 55|16@0+ (1,0) [0|65535] "" Vector__XXX

BO_ 563 CVC_FMCU_Limit: 8 CVC_P
 SG_ CVC_FMCU_Limit_CheckSum : 7|8@0+ (1,0) [0|255] ""  FMCU
 SG_ CVC_FMCU_Limit_AliveCounter : 11|4@0+ (1,0) [0|15] ""  FMCU
 SG_ CVC_FMCU_DischgPwrLim : 23|8@0+ (1,0) [0|250] "kw"  FMCU
 SG_ CVC_FMCU_RegenPwrLim : 31|8@0+ (1,0) [0|250] "kw"  FMCU

BO_ 564 CVC_PDU_Ctrl: 8 CVC_P
 SG_ CVC_DCDC_StsModeReq : 1|2@0+ (1,0) [0|3] ""  PDU
 SG_ CVC_enableDCDC : 2|1@0+ (1,0) [0|1] ""  PDU
 SG_ CVC_vDCDCRequest : 15|8@0+ (0.0625,0) [9|15.9375] "V"  PDU
 SG_ CVC_DCDC_CurrentLim : 23|12@0+ (0.1,0) [0|250] "A"  PDU
 SG_ CVC_DCDC_PwrPermit : 27|12@0+ (1,0) [0|3000] "W"  PDU

BO_ 568 FMCU_curSts: 8 FMCU
 SG_ FMCU_DampingState : 37|1@0+ (1,0) [0|1] ""  CVC_P
 SG_ FMCU_IGBTState : 39|2@0+ (1,0) [0|3] ""  CVC_P
 SG_ FMCU_ActualActiveHeatingPwr : 36|3@0+ (1,0) [0|8] "kW"  CVC_P

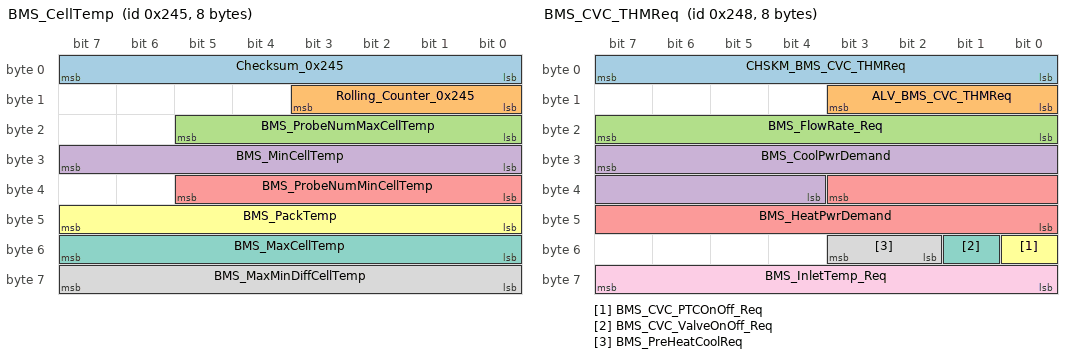
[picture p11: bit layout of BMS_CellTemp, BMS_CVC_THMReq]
BO_ 581 BMS_CellTemp: 8 BMS
 SG_ Checksum_0x245 : 7|8@0+ (1,0) [0|255] ""  PDU,CVC_P,EVCC
 SG_ Rolling_Counter_0x245 : 11|4@0+ (1,0) [0|15] ""  PDU,CVC_P,EVCC
 SG_ BMS_ProbeNumMaxCellTemp : 21|6@0+ (1,0) [0|63] ""  PDU,CVC_P
 SG_ BMS_MinCellTemp : 31|8@0+ (1,-40) [-40|215] "°C"  PDU,CVC_P
 SG_ BMS_ProbeNumMinCellTemp : 37|6@0+ (1,0) [0|63] ""  PDU,CVC_P
 SG_ BMS_PackTemp : 47|8@0+ (1,-40) [-40|215] "°C"  PDU,CVC_P,EVCC
 SG_ BMS_MaxCellTemp : 55|8@0+ (1,-40) [-40|215] "°C"  PDU,CVC_P
 SG_ BMS_MaxMinDiffCellTemp : 63|8@0+ (1,-40) [-40|215] "°C"  PDU,CVC_P

BO_ 584 BMS_CVC_THMReq: 8 BMS
 SG_ CHSKM_BMS_CVC_THMReq : 7|8@0+ (1,0) [0|255] ""  CVC_P
 SG_ ALV_BMS_CVC_THMReq : 11|4@0+ (1,0) [0|15] ""  CVC_P
 SG_ BMS_FlowRate_Req : 23|8@0+ (1,0) [0|50] "l/min"  CVC_P
 SG_ BMS_CoolPwrDemand : 31|12@0+ (0.1,0) [0|10] "kW"  CVC_P
 SG_ BMS_HeatPwrDemand : 35|12@0+ (0.1,0) [0|10] "kW"  CVC_P
 SG_ BMS_CVC_PTCOnOff_Req : 48|1@0+ (1,0) [0|1] ""  CVC_P
 SG_ BMS_CVC_ValveOnOff_Req : 49|1@0+ (1,0) [0|1] ""  CVC_P
 SG_ BMS_PreHeatCoolReq : 51|2@0+ (1,0) [0|3] ""  CVC_P
 SG_ BMS_InletTemp_Req : 63|8@0+ (0.5,0) [0|50] "℃"  CVC_P

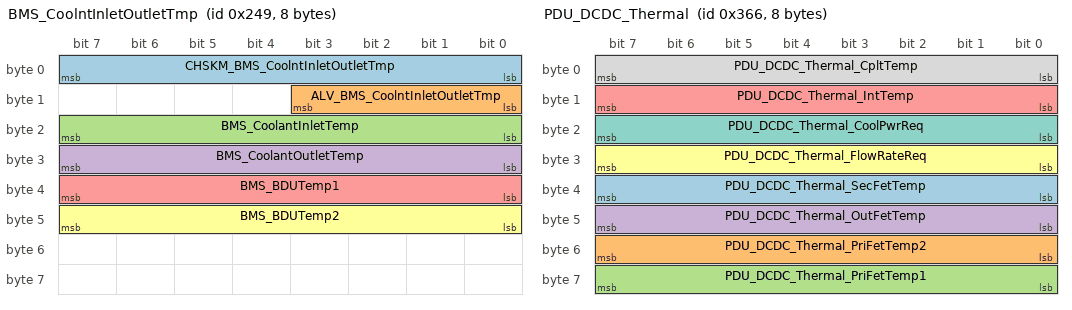
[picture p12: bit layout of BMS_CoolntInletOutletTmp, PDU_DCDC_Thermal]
BO_ 585 BMS_CoolntInletOutletTmp: 8 BMS
 SG_ CHSKM_BMS_CoolntInletOutletTmp : 7|8@0+ (1,0) [0|255] ""  PDU,CVC_P
 SG_ ALV_BMS_CoolntInletOutletTmp : 11|4@0+ (1,0) [0|15] ""  PDU,CVC_P
 SG_ BMS_CoolantInletTemp : 23|8@0+ (1,-40) [-40|215] "°C"  PDU,CVC_P
 SG_ BMS_CoolantOutletTemp : 31|8@0+ (1,-40) [-40|215] "°C"  PDU,CVC_P
 SG_ BMS_BDUTemp1 : 39|8@0+ (1,-40) [-40|215] "Degree C"  PDU,CVC_P
 SG_ BMS_BDUTemp2 : 47|8@0+ (1,-40) [-40|215] "°C"  PDU,CVC_P

BO_ 870 PDU_DCDC_Thermal: 8 PDU
 SG_ PDU_DCDC_Thermal_SecFetTemp : 39|8@0+ (1,-40) [-40|215] "oC" Vector__XXX
 SG_ PDU_DCDC_Thermal_PriFetTemp2 : 55|8@0+ (1,-40) [-40|215] "oC" Vector__XXX
 SG_ PDU_DCDC_Thermal_PriFetTemp1 : 63|8@0+ (1,-40) [-40|215] "oC" Vector__XXX
 SG_ PDU_DCDC_Thermal_OutFetTemp : 47|8@0+ (1,-40) [-40|215] "oC" Vector__XXX
 SG_ PDU_DCDC_Thermal_IntTemp : 15|8@0+ (1,-40) [-40|215] "oC" Vector__XXX
 SG_ PDU_DCDC_Thermal_FlowRateReq : 31|8@0+ (1,0) [0|50] "l/min" Vector__XXX
 SG_ PDU_DCDC_Thermal_CoolPwrReq : 23|8@0+ (0.1,0) [0|10] "KW" Vector__XXX
 SG_ PDU_DCDC_Thermal_CpltTemp : 7|8@0+ (1,-40) [-40|215] "oC" Vector__XXX

BO_ 526 BMS_FaultInfo: 8 BMS
 SG_ BMS_faultnumber : 7|64@0+ (1,0) [0|1.84467E+019] ""  CVC_P

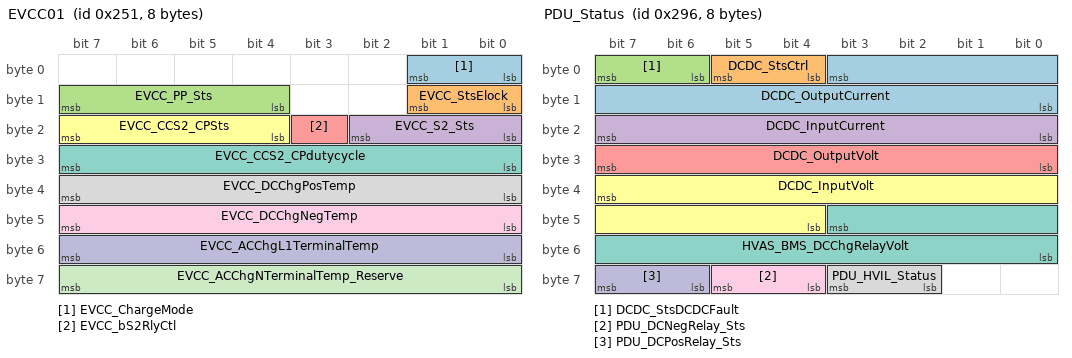
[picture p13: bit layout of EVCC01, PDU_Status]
BO_ 593 EVCC01: 8 EVCC
 SG_ EVCC_ChargeMode : 1|2@0+ (1,0) [0|3] "-"  CVC_P,BMS,PDU
 SG_ EVCC_StsElock : 9|2@0+ (1,0) [0|3] "-"  CVC_P,BMS,PDU
 SG_ EVCC_PP_Sts : 15|4@0+ (1,0) [0|15] ""  CVC_P,BMS,PDU
 SG_ EVCC_S2_Sts : 18|3@0+ (1,0) [0|7] "-"  CVC_P,BMS,PDU
 SG_ EVCC_bS2RlyCtl : 19|1@0+ (1,0) [0|1] "-"  CVC_P,BMS,PDU
 SG_ EVCC_CCS2_CPSts : 23|4@0+ (1,0) [0|15] ""  CVC_P,BMS,PDU
 SG_ EVCC_CCS2_CPdutycycle : 31|8@0+ (0.4,0) [0|100] "%"  CVC_P,BMS,PDU
 SG_ EVCC_DCChgPosTemp : 39|8@0+ (1,-40) [-40|210] "Degree C"  CVC_P,BMS,PDU
 SG_ EVCC_DCChgNegTemp : 47|8@0+ (1,-40) [-40|210] "Degree C"  CVC_P,BMS,PDU
 SG_ EVCC_ACChgL1TerminalTemp : 55|8@0+ (1,-40) [-40|210] "Degree C"  CVC_P,BMS,PDU
 SG_ EVCC_ACChgNTerminalTemp_Reserve : 63|8@0+ (1,-40) [-40|210] "Degree C"  CVC_P,BMS,PDU

BO_ 594 EVCC02: 8 EVCC
 SG_ EVCC_stPLCReqDc : 15|4@0+ (1,0) [0|15] ""  CVC_P,BMS,PDU
 SG_ EVCC_stPLCReqAc : 19|4@0+ (1,0) [0|15] ""  CVC_P,BMS,PDU

BO_ 662 PDU_Status: 8 PDU
 SG_ DCDC_OutputCurrent : 3|12@0+ (0.1,0) [0|250] "A"  CVC_P,EVCC
 SG_ DCDC_StsCtrl : 5|2@0+ (1,0) [0|3] "-"  CVC_P,EVCC
 SG_ DCDC_StsDCDCFault : 7|2@0+ (1,0) [0|3] "-"  CVC_P,EVCC
 SG_ DCDC_InputCurrent : 23|8@0+ (0.1,0) [0|25] "A"  CVC_P,EVCC
 SG_ DCDC_OutputVolt : 31|8@0+ (0.1,0) [0|25] "V"  CVC_P,EVCC
 SG_ DCDC_InputVolt : 39|12@0+ (0.5,0) [0|1000] "V"  CVC_P,EVCC
 SG_ HVAS_BMS_DCChgRelayVolt : 43|12@0+ (0.5,0) [0|1000] "V"  CVC_P,EVCC
 SG_ PDU_HVIL_Status : 59|2@0+ (1,0) [0|3] ""  CVC_P,EVCC
 SG_ PDU_DCNegRelay_Sts : 61|2@0+ (1,0) [0|3] ""  CVC_P,EVCC
 SG_ PDU_DCPosRelay_Sts : 63|2@0+ (1,0) [0|3] ""  CVC_P,EVCC

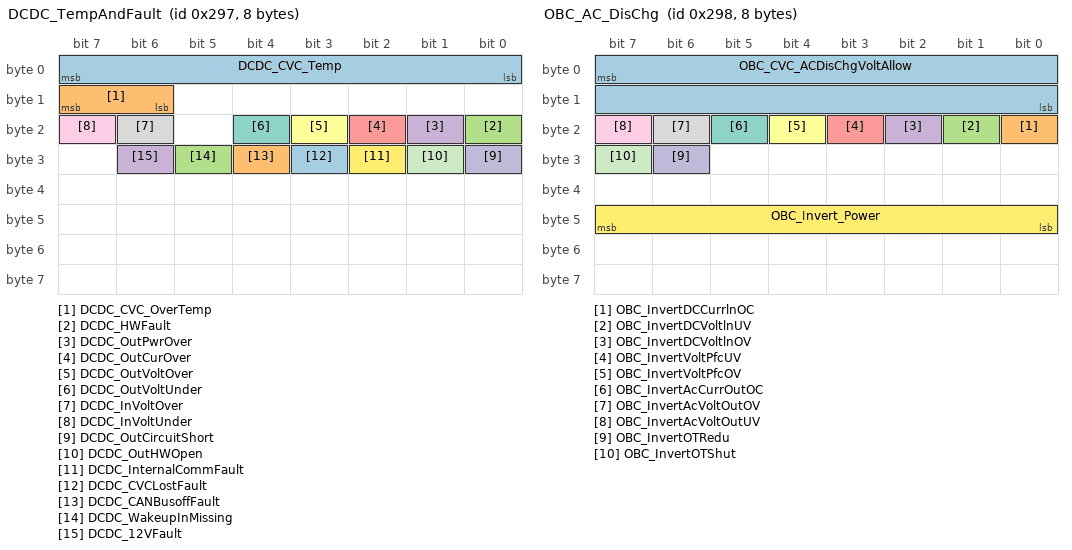
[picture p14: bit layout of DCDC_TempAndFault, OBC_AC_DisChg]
BO_ 663 DCDC_TempAndFault: 8 PDU
 SG_ DCDC_CVC_Temp : 7|8@0+ (1,-40) [-40|210] "Degree C"  CVC_P
 SG_ DCDC_CVC_OverTemp : 15|2@0+ (1,0) [0|3] ""  CVC_P
 SG_ DCDC_HWFault : 16|1@0+ (1,0) [0|1] ""  CVC_P
 SG_ DCDC_OutPwrOver : 17|1@0+ (1,0) [0|1] ""  CVC_P
 SG_ DCDC_OutCurOver : 18|1@0+ (1,0) [0|1] ""  CVC_P
 SG_ DCDC_OutVoltOver : 19|1@0+ (1,0) [0|1] ""  CVC_P
 SG_ DCDC_OutVoltUnder : 20|1@0+ (1,0) [0|1] ""  CVC_P
 SG_ DCDC_InVoltOver : 22|1@0+ (1,0) [0|1] ""  CVC_P
 SG_ DCDC_InVoltUnder : 23|1@0+ (1,0) [0|1] ""  CVC_P
 SG_ DCDC_OutCircuitShort : 24|1@0+ (1,0) [0|1] ""  CVC_P
 SG_ DCDC_OutHWOpen : 25|1@0+ (1,0) [0|1] ""  CVC_P
 SG_ DCDC_InternalCommFault : 26|1@0+ (1,0) [0|1] ""  CVC_P
 SG_ DCDC_CVCLostFault : 27|1@0+ (1,0) [0|1] ""  CVC_P
 SG_ DCDC_CANBusoffFault : 28|1@0+ (1,0) [0|1] ""  CVC_P
 SG_ DCDC_WakeupInMissing : 29|1@0+ (1,0) [0|1] ""  CVC_P
 SG_ DCDC_12VFault : 30|1@0+ (1,0) [0|1] ""  CVC_P

BO_ 664 OBC_AC_DisChg: 8 PDU
 SG_ OBC_CVC_ACDisChgVoltAllow : 7|16@0+ (0.1,0) [0|1000] "V"  CVC_P
 SG_ OBC_InvertDCCurrlnOC : 16|1@0+ (1,0) [0|1] ""  CVC_P
 SG_ OBC_InvertDCVoltlnUV : 17|1@0+ (1,0) [0|1] ""  CVC_P
 SG_ OBC_InvertDCVoltlnOV : 18|1@0+ (1,0) [0|1] ""  CVC_P
 SG_ OBC_InvertVoltPfcUV : 19|1@0+ (1,0) [0|1] ""  CVC_P
 SG_ OBC_InvertVoltPfcOV : 20|1@0+ (1,0) [0|1] ""  CVC_P
 SG_ OBC_InvertAcCurrOutOC : 21|1@0+ (1,0) [0|1] ""  CVC_P
 SG_ OBC_InvertAcVoltOutOV : 22|1@0+ (1,0) [0|1] ""  CVC_P
 SG_ OBC_InvertAcVoltOutUV : 23|1@0+ (1,0) [0|1] ""  CVC_P
 SG_ OBC_InvertOTRedu : 30|1@0+ (1,0) [0|1] ""  CVC_P
 SG_ OBC_InvertOTShut : 31|1@0+ (1,0) [0|1] ""  CVC_P
 SG_ OBC_Invert_Power : 47|8@0+ (0.1,0) [0|25] "Kw"  CVC_P

BO_ 666 PDU_DCDC_EventMatrix: 8 PDU
 SG_ PDU_DCDC_evt_reserved5 : 61|1@0+ (1,0) [0|1] "" Vector__XXX
 SG_ PDU_DCDC_evt_reserved6 : 62|1@0+ (1,0) [0|1] "" Vector__XXX
 SG_ PDU_DCDC_evt_reserved7 : 63|1@0+ (1,0) [0|1] "" Vector__XXX
 SG_ PDU_DCDC_evt_HVBat_UnderVolt_CMP : 41|1@0+ (1,0) [0|1] "" Vector__XXX
 SG_ PDU_DCDC_evt_LVOut_OverCurr_HW : 42|1@0+ (1,0) [0|1] "" Vector__XXX
 SG_ PDU_DCDC_evt_LVOut_OverVolt_HW : 43|1@0+ (1,0) [0|1] "" Vector__XXX
 SG_ PDU_DCDC_evt_LVOut_UnderVolt_SW : 44|1@0+ (1,0) [0|1] "" Vector__XXX
 SG_ PDU_DCDC_evt_LVOut_OverVolt_SW : 45|1@0+ (1,0) [0|1] "" Vector__XXX
 SG_ PDU_DCDC_evt_AuxPwrFlt_HW : 46|1@0+ (1,0) [0|1] "" Vector__XXX
 SG_ PDU_DCDC_evt_LVOut_UnderVolt_HW : 47|1@0+ (1,0) [0|1] "" Vector__XXX
 SG_ PDU_DCDC_evt_PFMFlt : 31|1@0+ (1,0) [0|1] "" Vector__XXX
 SG_ PDU_DCDC_evt_WdgFlt : 32|1@0+ (1,0) [0|1] "" Vector__XXX
 SG_ PDU_DCDC_evt_I2CComFlt : 33|1@0+ (1,0) [0|1] "" Vector__XXX
 SG_ PDU_DCDC_evt_SelfTestFlt : 35|1@0+ (1,0) [0|1] "" Vector__XXX
 SG_ PDU_DCDC_evt_LVOut_RevrsCurr_CMP : 36|1@0+ (1,0) [0|1] "" Vector__XXX
 SG_ PDU_DCDC_evt_LVBat_OverVolt_CMP : 37|1@0+ (1,0) [0|1] "" Vector__XXX
 SG_ PDU_DCDC_evt_LVBat_UnderVolt_CMP : 38|1@0+ (1,0) [0|1] "" Vector__XXX
 SG_ PDU_DCDC_evt_HVBat_OverVolt_CMP : 39|1@0+ (1,0) [0|1] "" Vector__XXX
 SG_ PDU_DCFC_evt_I2CDataWrong : 34|1@0+ (1,0) [0|1] "" Vector__XXX
 SG_ PDU_DCDC_evt_LVOut_RevrsCurr_SW : 16|1@0+ (1,0) [0|1] "" Vector__XXX
 SG_ PDU_DCDC_evt_TCANFlt : 30|1@0+ (1,0) [0|1] "" Vector__XXX
 SG_ PDU_DCDC_evt_LVOut_OverCurr_CMP : 29|1@0+ (1,0) [0|1] "" Vector__XXX
 SG_ PDU_DCDC_evt_Unchargeable : 28|1@0+ (1,0) [0|1] "" Vector__XXX
 SG_ PDU_DCDC_evt_ColdPlate_HighTemp : 27|1@0+ (1,0) [0|1] "" Vector__XXX
 SG_ PDU_DCDC_evt_Mosfet_HighTemp : 26|1@0+ (1,0) [0|1] "" Vector__XXX
 SG_ PDU_DCDC_evt_McuPwrFail : 25|1@0+ (1,0) [0|1] "" Vector__XXX
 SG_ PDU_DCDC_evt_LV_ShortOutputFlt : 24|1@0+ (1,0) [0|1] "" Vector__XXX
 SG_ PDU_DCDC_evt_Heater_SensorFlt : 17|1@0+ (1,0) [0|1] "" Vector__XXX
 SG_ PDU_DCDC_evt_Mosfet_TSensFail : 18|1@0+ (1,0) [0|1] "" Vector__XXX
 SG_ PDU_DCDC_evt_Mosfet_OverTemp : 19|1@0+ (1,0) [0|1] "" Vector__XXX
 SG_ PDU_DCDC_evt_Coldplate_TSensFail : 20|1@0+ (1,0) [0|1] "" Vector__XXX
 SG_ PDU_DCDC_evt_ColdPlate_OverTemp : 21|1@0+ (1,0) [0|1] "" Vector__XXX
 SG_ PDU_DCDC_evt_HeaterOverTemp : 22|1@0+ (1,0) [0|1] "" Vector__XXX
 SG_ PDU_DCDC_evt_HeaterShortIGBTFlt : 23|1@0+ (1,0) [0|1] "" Vector__XXX
 SG_ PDU_DCDC_evt_HVBat_UnderVolt_SW : 8|1@0+ (1,0) [0|1] "" Vector__XXX
 SG_ PDU_DCDC_evt_LVOut_VSensFail : 9|1@0+ (1,0) [0|1] "" Vector__XXX
 SG_ PDU_DCDC_evt_LVBat_OverVolt_SW : 10|1@0+ (1,0) [0|1] "" Vector__XXX
 SG_ PDU_DCDC_evt_LVBat_UnderVolt_SW : 11|1@0+ (1,0) [0|1] "" Vector__XXX
 SG_ PDU_DCDC_evt_LVBat_VSensFail : 12|1@0+ (1,0) [0|1] "" Vector__XXX
 SG_ PDU_DCDC_evt_LV_RedundancyFlt : 13|1@0+ (1,0) [0|1] "" Vector__XXX
 SG_ PDU_DCDC_evt_LVOut_ISensFail : 14|1@0+ (1,0) [0|1] "" Vector__XXX
 SG_ PDU_DCDC_evt_LVOut_OverCurr_SW : 15|1@0+ (1,0) [0|1] "" Vector__XXX
 SG_ PDU_DCDC_evt_BUS_OFF : 0|1@0+ (1,0) [0|1] "" Vector__XXX
 SG_ PDU_DCDC_evt_MIA : 1|1@0+ (1,0) [0|1] "" Vector__XXX
 SG_ PDU_DCDC_evt_E2E : 2|1@0+ (1,0) [0|1] "" Vector__XXX
 SG_ PDU_DCDC_evt_CalibFlt : 3|1@0+ (1,0) [0|1] "" Vector__XXX
 SG_ PDU_DCDC_evt_ExtMemFlt : 4|1@0+ (1,0) [0|1] "" Vector__XXX
 SG_ PDU_DCDC_evt_FaultLatchCircuit : 5|1@0+ (1,0) [0|1] "" Vector__XXX
 SG_ PDU_DCDC_evt_HVBat_VSensFail : 6|1@0+ (1,0) [0|1] "" Vector__XXX
 SG_ PDU_DCDC_evt_HVBat_OverVolt_SW : 7|1@0+ (1,0) [0|1] "" Vector__XXX
 SG_ PDU_DCDC_evt_reserved4 : 60|1@0+ (1,0) [0|255] "" Vector__XXX
 SG_ PDU_DCDC_evt_reserved3 : 59|1@0+ (1,0) [0|255] "" Vector__XXX
 SG_ PDU_DCDC_evt_reserved2 : 58|1@0+ (1,0) [0|255] "" Vector__XXX
 SG_ PDU_DCDC_evt_reserved1 : 57|1@0+ (1,0) [0|255] "" Vector__XXX
 SG_ PDU_DCDC_evt_reserved0 : 56|1@0+ (1,0) [0|255] "" Vector__XXX

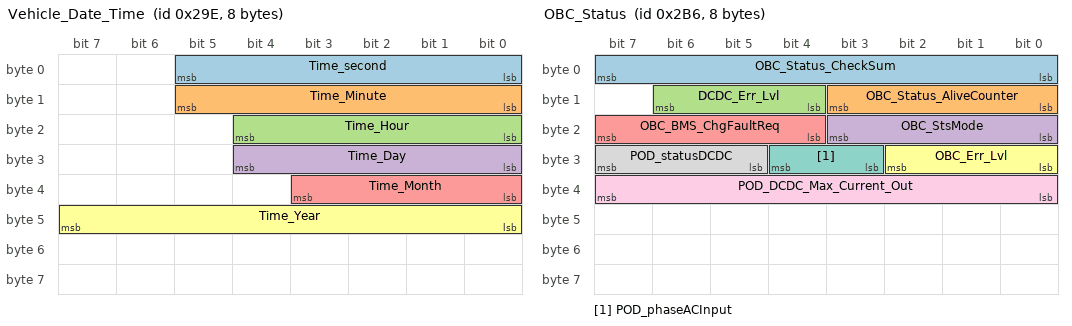
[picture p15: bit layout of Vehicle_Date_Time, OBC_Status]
BO_ 670 Vehicle_Date_Time: 8 CVC_P
 SG_ Time_second : 5|6@0+ (1,0) [0|59] "second"  BMS,FMCU,PDU,PTC,EAC,CCU,EVCC
 SG_ Time_Minute : 13|6@0+ (1,0) [0|59] "min"  BMS,FMCU,PDU,PTC,EAC,CCU,EVCC
 SG_ Time_Hour : 20|5@0+ (1,0) [0|23] "hour"  BMS,FMCU,PDU,PTC,EAC,CCU,EVCC
 SG_ Time_Day : 28|5@0+ (1,0) [1|31] "day"  BMS,FMCU,PDU,PTC,EAC,CCU,EVCC
 SG_ Time_Month : 35|4@0+ (1,0) [1|12] "month"  BMS,FMCU,PDU,PTC,EAC,CCU,EVCC
 SG_ Time_Year : 47|8@0+ (1,2000) [2000|2200] "year"  BMS,FMCU,PDU,PTC,EAC,CCU,EVCC

BO_ 694 OBC_Status: 8 PDU
 SG_ OBC_Status_CheckSum : 7|8@0+ (1,0) [0|255] "-"  CVC_P
 SG_ OBC_Status_AliveCounter : 11|4@0+ (1,0) [0|15] "-"  CVC_P
 SG_ DCDC_Err_Lvl : 14|3@0+ (1,0) [0|7] "-"  CVC_P
 SG_ OBC_StsMode : 19|4@0+ (1,0) [0|15] "-"  CVC_P,EVCC
 SG_ OBC_BMS_ChgFaultReq : 23|4@0+ (1,0) [0|15] "-"  CVC_P
 SG_ OBC_Err_Lvl : 26|3@0+ (1,0) [0|7] "-"  CVC_P,EVCC
 SG_ POD_phaseACInput : 28|2@0+ (1,0) [0|3] "-"  CVC_P,EVCC
 SG_ POD_statusDCDC : 31|3@0+ (1,0) [0|7] "-"  CVC_P
 SG_ POD_DCDC_Max_Current_Out : 39|8@0+ (1,0) [0|250] "A"  CVC_P

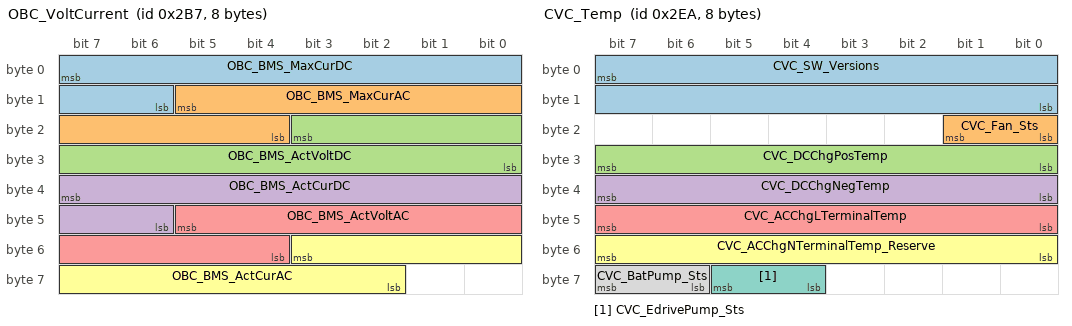
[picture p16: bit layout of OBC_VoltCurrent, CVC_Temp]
BO_ 695 OBC_VoltCurrent: 8 PDU
 SG_ OBC_BMS_MaxCurDC : 7|10@0+ (0.1,0) [0|100] "A"  CVC_P,EVCC
 SG_ OBC_BMS_MaxCurAC : 13|10@0+ (0.1,0) [0|100] "A"  CVC_P,EVCC
 SG_ OBC_BMS_ActVoltDC : 19|12@0+ (0.5,0) [0|1000] "V"  CVC_P,EVCC
 SG_ OBC_BMS_ActCurDC : 39|10@0+ (0.1,0) [0|100] "A"  CVC_P,EVCC
 SG_ OBC_BMS_ActVoltAC : 45|10@0+ (0.5,0) [0|500] "V"  CVC_P,EVCC
 SG_ OBC_BMS_ActCurAC : 51|10@0+ (0.1,0) [0|100] "A"  CVC_P,EVCC

BO_ 746 CVC_Temp: 8 CVC_P
 SG_ CVC_SW_Versions : 7|16@0+ (1,0) [0|255] "" Vector__XXX
 SG_ CVC_Fan_Sts : 17|2@0+ (1,0) [0|3] "" Vector__XXX
 SG_ CVC_DCChgPosTemp : 31|8@0+ (1,-40) [-40|210] "Degree C" Vector__XXX
 SG_ CVC_DCChgNegTemp : 39|8@0+ (1,-40) [-40|210] "Degree C" Vector__XXX
 SG_ CVC_ACChgLTerminalTemp : 47|8@0+ (1,-40) [-40|210] "Degree C" Vector__XXX
 SG_ CVC_ACChgNTerminalTemp_Reserve : 55|8@0+ (1,-40) [-40|210] "Degree C" Vector__XXX
 SG_ CVC_EdrivePump_Sts : 61|2@0+ (1,0) [0|3] "" Vector__XXX
 SG_ CVC_BatPump_Sts : 63|2@0+ (1,0) [0|3] "" Vector__XXX

BO_ 773 BMS_Insulation: 8 BMS
 SG_ CHSKM_BMS_Insulation : 7|8@0+ (1,0) [0|255] ""  CVC_P,EVCC
 SG_ ALV_BMS_Insulation : 11|4@0+ (1,0) [0|15] ""  CVC_P,EVCC
 SG_ BMS_CVC_Insulation_Mon_Sts : 15|1@0+ (1,0) [0|1] ""  CVC_P,EVCC
 SG_ BMS_PackInsuRes : 23|16@0+ (1,0) [0|60000] "kOhm"  CVC_P,EVCC

BO_ 775 BMS_Sensor_Start_Stop_0x307: 8 BMS
 SG_ Checksum_0x307 : 7|8@0+ (1,0) [0|255] ""  CVC_P
 SG_ Rolling_Counter_0x307 : 11|4@0+ (1,0) [0|15] ""  CVC_P
 SG_ BMS_Start_Stop_DM13 : 17|2@0+ (1,0) [0|3] ""  CVC_P

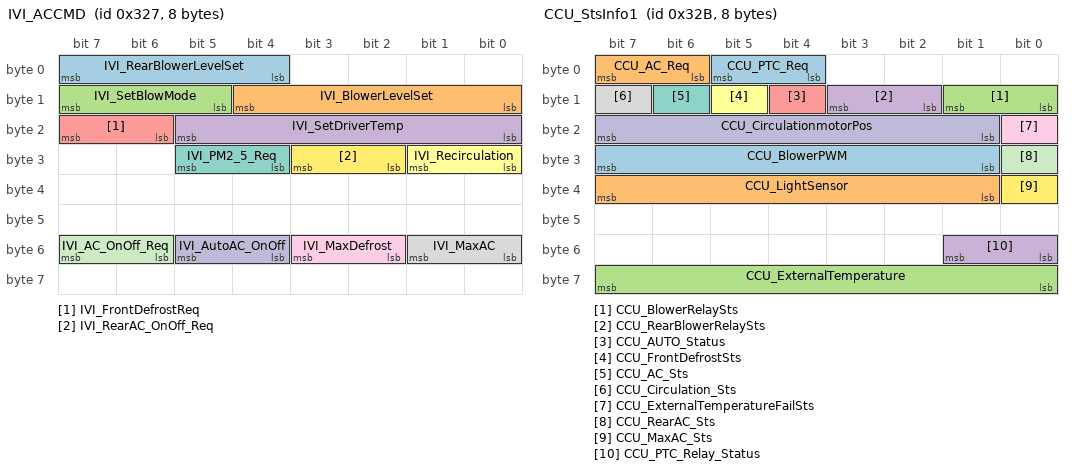
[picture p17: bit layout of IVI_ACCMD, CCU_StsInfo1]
BO_ 807 IVI_ACCMD: 8 CVC_P
 SG_ IVI_RearBlowerLevelSet : 7|4@0+ (1,0) [0|7] ""  CCU
 SG_ IVI_BlowerLevelSet : 12|5@0+ (1,0) [0|9] ""  CCU
 SG_ IVI_SetBlowMode : 15|3@0+ (1,0) [0|7] ""  CCU
 SG_ IVI_SetDriverTemp : 21|6@0+ (0.5,10) [16|32] ""  CCU
 SG_ IVI_FrontDefrostReq : 23|2@0+ (1,0) [0|3] ""  CCU
 SG_ IVI_Recirculation : 25|2@0+ (1,0) [0|3] ""  CCU
 SG_ IVI_PM2_5_Req : 29|2@0+ (1,0) [0|3] ""  CCU
 SG_ IVI_MaxAC : 49|2@0+ (1,0) [0|3] ""  CCU
 SG_ IVI_MaxDefrost : 51|2@0+ (1,0) [0|3] ""  CCU
 SG_ IVI_AutoAC_OnOff : 53|2@0+ (1,0) [0|3] ""  CCU
 SG_ IVI_AC_OnOff_Req : 55|2@0+ (1,0) [0|3] ""  CCU
 SG_ IVI_RearAC_OnOff_Req : 27|2@0+ (1,0) [0|3] ""  CCU

BO_ 811 CCU_StsInfo1: 8 CCU
 SG_ CCU_PTC_Req : 5|2@0+ (1,0) [0|3] ""  CVC_P,FMCU,BMS,PDU,EVCC
 SG_ CCU_AC_Req : 7|2@0+ (1,0) [0|3] ""  CVC_P,FMCU,BMS,PDU,EVCC
 SG_ CCU_BlowerRelaySts : 9|2@0+ (1,0) [0|3] ""  CVC_P,FMCU,BMS,PDU,EVCC
 SG_ CCU_RearBlowerRelaySts : 11|2@0+ (1,0) [0|3] ""  CVC_P,FMCU,BMS,PDU,EVCC
 SG_ CCU_AUTO_Status : 12|1@0+ (1,0) [0|1] ""  CVC_P,FMCU,BMS,PDU,EVCC
 SG_ CCU_FrontDefrostSts : 13|1@0+ (1,0) [0|1] ""  CVC_P,FMCU,BMS,PDU,EVCC
 SG_ CCU_AC_Sts : 14|1@0+ (1,0) [0|1] ""  CVC_P,FMCU,BMS,PDU,EVCC
 SG_ CCU_Circulation_Sts : 15|1@0+ (1,0) [0|1] ""  CVC_P,FMCU,BMS,PDU,EVCC
 SG_ CCU_ExternalTemperatureFailSts : 16|1@0+ (1,0) [0|1] ""  CVC_P,FMCU,BMS,PDU,EVCC
 SG_ CCU_CirculationmotorPos : 23|7@0+ (0.1,0) [0|10] "V"  CVC_P,FMCU,BMS,PDU,EVCC
 SG_ CCU_RearAC_Sts : 24|1@0+ (1,0) [0|1] ""  CVC_P,FMCU,BMS,PDU,EVCC
 SG_ CCU_MaxAC_Sts : 32|1@0+ (1,0) [0|1] ""  CVC_P,FMCU,BMS,PDU,EVCC
 SG_ CCU_BlowerPWM : 31|7@0+ (1,0) [0|100] "%"  CVC_P,FMCU,BMS,PDU,EVCC
 SG_ CCU_LightSensor : 39|7@0+ (1,0) [0|100] "%"  CVC_P,FMCU,BMS,PDU,EVCC
 SG_ CCU_ExternalTemperature : 63|8@0+ (0.5,-40) [-40|87] "Degree C"  CVC_P,FMCU,PDU,PTC,EAC,EVCC,BMS
 SG_ CCU_PTC_Relay_Status : 49|2@0+ (1,0) [0|3] ""  CVC_P

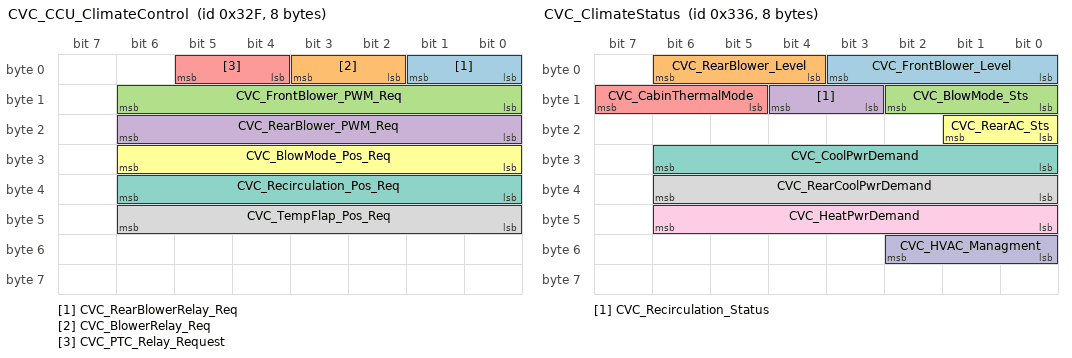
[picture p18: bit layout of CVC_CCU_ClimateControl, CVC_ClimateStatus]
BO_ 815 CVC_CCU_ClimateControl: 8 CVC_P
 SG_ CVC_RearBlowerRelay_Req : 1|2@0+ (1,0) [0|3] ""  CCU
 SG_ CVC_BlowerRelay_Req : 3|2@0+ (1,0) [0|3] ""  CCU
 SG_ CVC_FrontBlower_PWM_Req : 14|7@0+ (1,0) [0|100] "%"  CCU
 SG_ CVC_RearBlower_PWM_Req : 22|7@0+ (1,0) [0|100] "%"  CCU
 SG_ CVC_PTC_Relay_Request : 5|2@0+ (1,0) [0|3] ""  CCU
 SG_ CVC_BlowMode_Pos_Req : 30|7@0+ (1,0) [0|100] "%"  CCU
 SG_ CVC_Recirculation_Pos_Req : 38|7@0+ (1,0) [0|100] "%"  CCU
 SG_ CVC_TempFlap_Pos_Req : 46|7@0+ (1,0) [0|100] "%"  CCU

BO_ 822 CVC_ClimateStatus: 8 CVC_P
 SG_ CVC_FrontBlower_Level : 3|4@0+ (1,0) [0|8] ""  DUMMY_ECU
 SG_ CVC_RearBlower_Level : 6|3@0+ (1,0) [0|6] ""  DUMMY_ECU
 SG_ CVC_BlowMode_Sts : 10|3@0+ (1,0) [0|6] ""  CCU
 SG_ CVC_Recirculation_Status : 12|2@0+ (1,0) [0|2] ""  CCU
 SG_ CVC_CabinThermalMode : 15|3@0+ (1,0) [0|6] ""  DUMMY_ECU
 SG_ CVC_RearAC_Sts : 17|2@0+ (1,0) [0|3] ""  DUMMY_ECU
 SG_ CVC_CoolPwrDemand : 30|7@0+ (0.1,0) [0|10] "kW"  DUMMY_ECU
 SG_ CVC_RearCoolPwrDemand : 38|7@0+ (0.1,0) [0|10] "kW"  DUMMY_ECU
 SG_ CVC_HeatPwrDemand : 46|7@0+ (0.1,0) [0|10] "kW"  DUMMY_ECU
 SG_ CVC_HVAC_Managment : 50|3@0+ (1,0) [0|3] ""  DUMMY_ECU

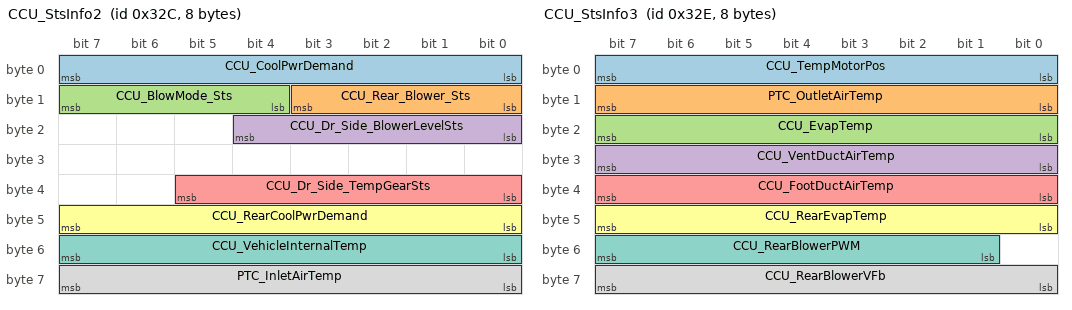
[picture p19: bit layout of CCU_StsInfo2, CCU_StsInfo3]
BO_ 812 CCU_StsInfo2: 8 CCU
 SG_ CCU_CoolPwrDemand : 7|8@0+ (0.1,0) [0|10] "kW"  CVC_P
 SG_ CCU_Rear_Blower_Sts : 11|4@0+ (1,0) [0|15] ""  CVC_P
 SG_ CCU_BlowMode_Sts : 15|4@0+ (1,0) [0|15] ""  CVC_P,FMCU,PDU,PTC,EAC
 SG_ CCU_Dr_Side_BlowerLevelSts : 20|5@0+ (1,0) [0|31] ""  CVC_P,FMCU,PDU,PTC,EAC
 SG_ CCU_Dr_Side_TempGearSts : 37|6@0+ (0.5,10) [16|32] "Degree C"  CVC_P,FMCU,PDU,PTC,EAC
 SG_ CCU_RearCoolPwrDemand : 47|8@0+ (0.1,0) [0|10] "kW"  CVC_P
 SG_ CCU_VehicleInternalTemp : 55|8@0+ (1,-40) [-40|100] "Degree C"  CVC_P,FMCU,PDU,PTC,EAC,EVCC,BMS
 SG_ PTC_InletAirTemp : 63|8@0+ (1,-48) [-48|207] "°C"  CVC_P,EVCC

BO_ 814 CCU_StsInfo3: 8 CCU
 SG_ CCU_TempMotorPos : 7|8@0+ (0.1,0) [0|10] "V"  CVC_P,EVCC
 SG_ PTC_OutletAirTemp : 15|8@0+ (1,-48) [-48|207] "°C"  CVC_P,EVCC
 SG_ CCU_EvapTemp : 23|8@0+ (1,-48) [-48|207] "°C"  CVC_P,EVCC
 SG_ CCU_VentDuctAirTemp : 31|8@0+ (1,-48) [-48|207] "°C"  CVC_P,EVCC
 SG_ CCU_FootDuctAirTemp : 39|8@0+ (1,-48) [-48|207] "°C"  CVC_P,EVCC
 SG_ CCU_RearEvapTemp : 47|8@0+ (1,-48) [-48|207] "°C"  CVC_P,EVCC
 SG_ CCU_RearBlowerPWM : 55|7@0+ (1,0) [0|100] "%"  CVC_P,EVCC
 SG_ CCU_RearBlowerVFb : 63|8@0+ (0.1,0) [0|15] "V"  CVC_P,EVCC

BO_ 816 BMS_HistData: 8 BMS
 SG_ Checksum_0x330 : 7|8@0+ (1,0) [0|255] ""  CVC_P
 SG_ Rolling_Counter_0x330 : 11|4@0+ (1,0) [0|15] ""  CVC_P
 SG_ BMS_ContactorAging : 23|8@0+ (1,0) [0|100] "%"  CVC_P

BO_ 817 CCH_RHVAC_Ctrl: 8 CVC_P
 SG_ CCH_Rear_Blower_Increase : 0|1@0+ (1,0) [0|1] ""  CCU
 SG_ CCH_Rear_Blower_Decrease : 1|1@0+ (1,0) [0|1] ""  CCU
 SG_ CCH_RearAC_OnOff_Req : 2|1@0+ (1,0) [0|1] ""  CCU

BO_ 818 BMS_PackInfo: 8 BMS
 SG_ Checksum_0x332 : 7|8@0+ (1,0) [0|255] ""  CVC_P
 SG_ Rolling_Counter_0x332 : 11|4@0+ (1,0) [0|15] ""  CVC_P
 SG_ BMS_PackCNom : 23|16@0+ (0.1,0) [0|6553.5] "kWh"  CVC_P
 SG_ BMS_PackTemp_0x332 : 39|8@0+ (1,-40) [-40|215] "Degree C"  CVC_P

BO_ 819 BMS_ECU_Info_1: 8 BMS
 SG_ BMS_SwVers_Type : 7|8@0+ (1,0) [0|255] "" Vector__XXX
 SG_ BMS_SwVersS_phase : 15|8@0+ (1,0) [0|255] "" Vector__XXX
 SG_ BMS_swVers_version : 47|8@0+ (1,0) [0|255] "" Vector__XXX

CM_ "25/03/11 14:14:27 generated by DPCA/ELE";
CM_ SG_ 128 ACU_DAirbagStatus "Signal from ACU for Driver seat on/off indicator";
CM_ SG_ 128 ACU_CoDAirbagStatus "Signal from ACU for CoDriver seat on/off indicator";
CM_ SG_ 128 ACU_LCABsts "Left curtain airbag status";
CM_ SG_ 128 ACU_RCABsts "Right curtain airbag status";
CM_ SG_ 128 ACU_LSABsts "Left side airbag status";
CM_ SG_ 128 ACU_RSABsts "Right side airbag status";
CM_ SG_ 128 ACU_CrashSts "Car Crash status";
CM_ SG_ 128 ACU_AirbagWarningStatus "Signal from ACU for Airbag Controll Unit Warning LED status";
CM_ SG_ 128 ACU_pyro_fuse_Stat "Cut off the high-voltage fuse status";
CM_ SG_ 128 ACU_PBA_InhibitSts "PAB inhibit status";
CM_ SG_ 128 ACU_CrashRearOutputSts "Rear collision status";
CM_ SG_ 128 ACU_CrashRightOutputSts "Right side collision status";
CM_ SG_ 128 ACU_CrashLeftOutputSts "Left collision status";
CM_ SG_ 128 ACU_CrashFrontOutputSts "Forward collision status";
CM_ SG_ 170 CHSKM_CVC_Sts1 "CHSKM_CVC_Sts1";
CM_ SG_ 170 CVC_BMS_HVOnOff_REQ "BMS decides whether to close or disconnect the primary and negative relays by judging this command";
CM_ SG_ 171 CheckSum_0xAB "Checksum of this message";
CM_ SG_ 171 AliveCounter_0xAB "Signal counting the times of this message";
CM_ SG_ 171 CVC_FMCU_TargetTqReq "Front Motor Target torque Request";
CM_ SG_ 171 CVC_FMCU_TargetSpeedReq "Front Motor Target speed Request";
CM_ SG_ 171 CVC_FMCU_StsModeReq "FMCU Status Request";
CM_ SG_ 171 CVC_FMCU_TargetTqReqV "Front Motor Target torque Request Validity";
CM_ SG_ 171 CVC_FMCU_TargetSpeedReqV "Front Motor Target speed Request Validity";
CM_ SG_ 171 CVC_FMCU_VehicleDirect "Vehicle direct";
CM_ SG_ 171 CVC_MCU_AtvDischg_Req "MCU Active Discharge Request";
CM_ SG_ 171 CVC_MCU_CtrlModeReq "Control Mode Request";
CM_ SG_ 201 FMCU_Status_CheckSum "Checksum of this message";
CM_ SG_ 201 FMCU_Status_AliveCounter "Signal counting the times of this message";
CM_ SG_ 201 FMCU_CVC_MCUFaultReq "FMCU  Fault Status Request";
CM_ SG_ 201 FMCU_MotorTq "Front Motor torque";
CM_ SG_ 201 FMCU_MotorSpd "Front Motor rotating speed";
CM_ SG_ 201 FMCU_StsMCUFault "FMCU Fault Status";
CM_ SG_ 201 FMCU_MotorSpdInvalid "Front Motor rotating speed Invalid";
CM_ SG_ 201 FMCU_MotorTqInvalid "Front Motor torque Invalid";
CM_ SG_ 201 FMCU_CVC_CtrlMode "FMCU control mode";
CM_ SG_ 201 FMCU_CVC_StsMode "FMCU Operating Mode";
CM_ SG_ 202 FMCU_CVC_PosTrqLmt "Maximum positive Torque available (motor) for Front Motor Torque requests";
CM_ SG_ 202 FMCU_CVC_NegTrqLmt "Maximum negative torque available (generator) for Front Motor Torque requests";
CM_ SG_ 202 FMCU_ActInputCurrent "Front Motor Actual input DC current";
CM_ SG_ 202 FMCU_ActInputVolt "Front Motor Actual input DC voltage";
CM_ SG_ 202 FMCU_ActInputVoltV "Front Motor Actual input DC voltage validity";
CM_ SG_ 202 FMCU_ActInputCurrentV "Front Motor Actual input DC current validity";
CM_ SG_ 266 CHKSM_BCM_VOLTAGE "Checksum";
CM_ SG_ 266 ALIVE_BCM_VOLTAGE "Alive counter";
CM_ SG_ 266 LV_BatteryType "LV Battery Type (Lead Acid or Lithium)";
CM_ SG_ 266 UBatt "Battery Voltage";
CM_ SG_ 266 LV_Batt_Temp_Reserved "Low voltage Battery Temperature";
CM_ SG_ 266 LV_SOC_Reserved "State Of charge for Low Voltage Battery";
CM_ SG_ 266 LV_Batt_Current_Reserved "Current of Low Voltage Battery";
CM_ SG_ 279 CHKSM_BCM_CLAMP_STAT "Checksum";
CM_ SG_ 279 ALIVE_BCM_CLAMP_STAT "Alive counter";
CM_ SG_ 279 RemoteFunctionState "0x1(remote function) will be sent after PreRemoteStart=0x1 first time in ignition OFF state, and this signal will be kept 0x1 until SESAM exit remote state.";
CM_ SG_ 279 STAT_BLS "Signal represent plausibility of both HW Inputs for brake light switch.";
CM_ SG_ 279 STAT_CL_50_L "Logical clamp status";
CM_ SG_ 279 Clamp50AdviceRemoteStart "Engine Start announcement (Clamp 50) for remote start";
CM_ SG_ 279 Clamp50AdviceESS "Engine Start announcement (Clamp 50) for ESS";
CM_ SG_ 279 STAT_CL_R_L "Logical clamp status";
CM_ SG_ 279 STAT_CL_15_1_L "Logical clamp status";
CM_ SG_ 279 STAT_CL_15_1_DME_L "Logical clamp status";
CM_ SG_ 279 FobId "Information of FOB ID.";
CM_ SG_ 279 STAT_Terminal "Represent the status of physical terminal";
CM_ SG_ 279 STAT_CL30_C_BEV "Logical clamp status";
CM_ SG_ 279 BCM_Clamp_Transport "BCM_Clamp_Transport";
CM_ SG_ 280 CVC_VehicleSpeed "Vehicle reference speed";
CM_ SG_ 280 CVC_VehicleSpeedValid "Indicate vehicle reference speed valid";
CM_ SG_ 280 CVC_HV_State "High voltage power-on status";
CM_ SG_ 293 ABS_Status_CheckSum "CRC code to check the data integrity";
CM_ SG_ 293 ABS_Status_AliveCounter "signal couting the times of this message";
CM_ SG_ 293 ABS_VehicleSpeed "Vehicle Speed";
CM_ SG_ 293 ABSActive "Signal from ABS/ABS to indicate if ABS is activate or not";
CM_ SG_ 293 ABS_EBDFailed "Signal from ABS/ABS to indicate EBD failure for driver";
CM_ SG_ 293 ABSFailed "Signal from ABS/ABS to indicate Failure/Normal state of current running";
CM_ SG_ 293 ABS_LowBrakeFluid "Detect the brake fluid level";
CM_ SG_ 293 ABS_VehicleSpeedInvalid "Signal from ABS to indicate if VehicleSpeed is valid";
CM_ SG_ 293 ABS_HAZActive "Emergency Stop Active";
CM_ SG_ 294 Checksum_0x126 "Checksum";
CM_ SG_ 294 Rolling_Counter_0x126 "Rolling Counter";
CM_ SG_ 294 BMS_AllowChgCurr "Continuous maximum allowable charge current of battery";
CM_ SG_ 294 BMS_AllowChgCurrPeak "Instantaneous maximum allowable charge current of battery for 30 seconds";
CM_ SG_ 296 Checksum_0x128 "Checksum";
CM_ SG_ 296 Rolling_Counter_0x128 "Rolling Counter";
CM_ SG_ 296 BMS_AllowDischgCurr "Instantaneous maximum allowable discharge current of battery";
CM_ SG_ 296 BMS_AllowDischgCurrPeak "Instantaneous maximum allowable discharge current of battery for 30 seconds";
CM_ SG_ 306 ESC_SlopeGradeAngle "Vehicle slope,Uphill is negative (head is higher than tail), downhill is positive (tail is higher than head)";
CM_ SG_ 306 ESC_MasterCylinderPressure "Master cylinder pressure";
CM_ SG_ 306 ESC_MasterCylinderPressureV "Master cylinder pressure Validity";
CM_ SG_ 306 ESC_HSA_Control_Status "Indicate HSA function is active or not";
CM_ SG_ 306 ESC_HSA_Status_Fault "Detect the HAS Fault status";
CM_ SG_ 306 ESC_TcsDisableSts "Indicate the TCS function can use or not";
CM_ SG_ 306 ESC_EscCtrlActv "Indicate ESC  function is active or not";
CM_ SG_ 306 ESC_TcsCtrlActv "Indicate TCS  function is active or not";
CM_ SG_ 306 ESC_EscFlgFlt "Detect the ESC function fault status";
CM_ SG_ 306 ESC_TcsFlgFlt "Detect the TCS function fault status";
CM_ SG_ 306 ESC_EscDisableSts "Indicate the ESC function can use or not";
CM_ SG_ 306 ESC_HBAFlgFlt "Detect the HBA(Hydraulic Brake Assist) function status";
CM_ SG_ 306 ESC_HbaCtrlActv "Indicate HBA(Hydraulic Brake Assist)   function is active or not";
CM_ SG_ 306 BAS_FlgFlt "Detect the BAS(Brake Assist Systems) function fault status";
CM_ SG_ 306 BAS_CtrlActv "Indicate the BAS function can use or not";
CM_ SG_ 306 IBS_ESCOFF_StsFB "Feedback of the ESC OFF  is active or not";
CM_ SG_ 306 ESC_DTC_Active "DTC active or not";
CM_ SG_ 306 ESC_VehicleStandstill "Vehicle stationary detected";
CM_ SG_ 354 CVC_ModeGearSts "gear information";
CM_ SG_ 354 CVC_P_Sts "P gear status";
CM_ SG_ 354 CVC_IMMO_Sts "Indicates the IMMO Fail";
CM_ SG_ 354 CVC_Ready "Indicates Ready State";
CM_ SG_ 354 CVC_RegencyLevInd "Indicates Regency Level";
CM_ SG_ 354 CVC_HVsystem_status "High Voltage system status";
CM_ SG_ 354 CVC_HV_DRVsystem_status "Status of driving system ( Highvoltage )";
CM_ SG_ 358 CVC_Status_CheckSum "CRC code to check the data integrity";
CM_ SG_ 358 CVC_Status_AliveCounter "signal couting the times of this message";
CM_ SG_ 358 CVC_DriveModeSts "CVC_Drive Mode Status";
CM_ SG_ 358 CVC_Fault "Vehicle Fault Level";
CM_ SG_ 358 CVC_VecFltInd "Vehicle Fault Indication";
CM_ SG_ 358 CVC_Creep_Sts "Creep Status";
CM_ SG_ 358 CVC_CruiseCtrlSts "cruise control Status";
CM_ SG_ 358 CVC_StsBrakePedalSwitch "Brake pedal Switch status";
CM_ SG_ 358 CVC_CruiseSetSpd "Cruise set speed";
CM_ SG_ 358 CVC_CruiseFaultIndication "CVC_Cruise Fault";
CM_ SG_ 1235 CHSKM_CVC_Debug "Checksum";
CM_ SG_ 1235 ALV_CVC_Debug "Alive Counter";
CM_ SG_ 1235 CVC_GearPOnlyAtStationaryAlert "Gear position P only when stationary";
CM_ SG_ 1235 CVC_GearP_NotPossibleAlert "Gear P not possible,  Due to EPP lock is not possible, gear position P may not be possible.";
CM_ SG_ 1235 CVC_PressBrakeToEngageGear "Press Brake to engage gear hint";
CM_ SG_ 1235 CVC_CantChangeGear "Unable to change gear position";
CM_ SG_ 1235 CVC_GearMalfunction "Gear change might be not possible, Possibly faulty selector lever";
CM_ SG_ 1235 CVC_RangeAlert "The range warning, charging soon";
CM_ SG_ 1235 CVC_HVSystemReduced "Reduced HV System Power";
CM_ SG_ 1235 CVC_FrontEDSReduced "Reduced Front EDS Power";
CM_ SG_ 1235 CVC_FrontEDS_Malfunc "Front EDS malfunction";
CM_ SG_ 1235 CVC_RearEDSReduced "Reduced Rear EDS Power";
CM_ SG_ 1235 CVC_RearEDS_Malfunc "Rear EDS malfunction";
CM_ SG_ 1235 CVC_CoolingSystem_Malfunc "EV Cooling system malfunction";
CM_ SG_ 1235 CVC_NeutralRequest "Neutral request warning";
CM_ SG_ 1235 CVC_SoftShutdown "Soft shutdown warning";
CM_ SG_ 1235 CVC_EmergencyShutdown "Emergency Shutdown warning";
CM_ SG_ 1235 CVC_ChgPortDoorSys_Malfunc "Charging Port Door Defective";
CM_ SG_ 1235 CVC_Gearchange_NotPossible "During Game Mode, or charging gun attached, gear change not possible";
CM_ SG_ 1235 CVC_12v_Warning "CVC warning for 12v battery based on data received from BCM ";
CM_ SG_ 1235 CVC_WflagRes19 "Reserved CVC Warning message";
CM_ SG_ 1235 CVC_WflagRes20 "Reserved CVC Warning message";
CM_ SG_ 1235 CVC_WflagRes21 "Reserved CVC Warning message";
CM_ SG_ 1235 CVC_WflagRes22 "Reserved CVC Warning message";
CM_ SG_ 1235 CVC_WflagRes23 "Reserved CVC Warning message";
CM_ SG_ 1235 CVC_WflagRes24 "Reserved CVC Warning message";
CM_ SG_ 1235 CVC_WflagRes25 "Reserved CVC Warning message";
CM_ SG_ 1235 CVC_WflagRes26 "Reserved CVC Warning message";
CM_ SG_ 1235 CVC_WflagRes27 "Reserved CVC Warning message";
CM_ SG_ 1235 CVC_SuperFastCharge_longer "CVC SuperFastCharge longer";
CM_ SG_ 1235 CVC_InvalidLimitSpeed "Warning for Invalid Speed limit";
CM_ SG_ 1235 CVC_InvalidCruiseSpeed "Warning for Invalid Cruise Speed";
CM_ SG_ 1235 CVC_Reserved_signal2 "Warning Message Flag, Component owner, Supplier align and define for this signal";
CM_ SG_ 1235 CVC_Reserved_signal3 "Warning Message Flag, Component owner, Supplier align and define for this signal";
CM_ BO_ 1873 "CVC_DebugDiag";
CM_ SG_ 1873 CVC_DebugDiag2 "CVC Acm component error level";
CM_ SG_ 1873 CVC_DebugDiag1 "CVC xGW component error level";
CM_ SG_ 1873 CVC_DebugDiag5 "CVC Regen brake component error level";
CM_ SG_ 1873 CVC_DebugDiag4 "CVC Idb component error level";
CM_ SG_ 1873 CVC_DebugDiag3 "CVC Brake component error level";
CM_ SG_ 1873 CVC_DebugDiag8 "CVC Ags component error level";
CM_ SG_ 1873 CVC_DebugDiag7 "CVC Lvd component error level";
CM_ SG_ 1873 CVC_DebugDiag6 "CVC Eds component error level";
CM_ SG_ 1873 CVC_DebugDiag10 "CVC Fan component error level";
CM_ SG_ 1873 CVC_DebugDiag9 "CVC Ptc component error level";
CM_ SG_ 1873 CVC_DebugDiag13 "CVC Valve component error level";
CM_ SG_ 1873 CVC_DebugDiag12 "CVC Tsen component error level";
CM_ SG_ 1873 CVC_DebugDiag11 "CVC Hvac component error level";
CM_ SG_ 1873 CVC_DebugDiag16 "CVC Bms component error level";
CM_ SG_ 1873 CVC_DebugDiag15 "CVC Vehicle speed component error level";
CM_ SG_ 1873 CVC_DebugDiag14 "CVC Water pump component error level";
CM_ SG_ 1873 CVC_DebugDiag18 "CVC Accelerator pedal component error level";
CM_ SG_ 1873 CVC_DebugDiag17 "CVC Obc component error level";
CM_ SG_ 1873 CVC_DebugDiag20 "CVC Dcdc component error level";
CM_ SG_ 1873 CVC_DebugDiag19 "CVC charging component errror level";
CM_ SG_ 359 CVC_AccPedal_Valid "Accelerate pedal position signal Valid";
CM_ SG_ 359 CVC_StsAccPedalFault "Accelerate pedal fault status";
CM_ SG_ 359 CVC_StsSysFault "Drive system fault level";
CM_ SG_ 359 CVC_AccPedalPosition "Accelerate pedal position";
CM_ SG_ 368 FMCU_MaxSpeedAllow "Front motor max speed allowed";
CM_ SG_ 368 FMCU_MotorTempAlarm "Front motor temp alarm";
CM_ SG_ 368 FMCU_PowerReduceSts "FMCU reduce power status";
CM_ SG_ 368 FMCU_DragSts "Front motor Drag status";
CM_ SG_ 368 FMCU_HighVoltPowerOffReq "FMCU HV Power off request";
CM_ SG_ 368 FMCU_InletTemp "Front inlet temp";
CM_ SG_ 372 CHSKM_BMS_CurMeas "Checksum";
CM_ SG_ 372 ALV_BMS_CurMeas "Alive Counter";
CM_ SG_ 372 BMS_StartOfMeasument_STS "Synchronize signals indicate start of cell/pack voltage measument";
CM_ SG_ 372 BMS_PackCur_MEAS "Battery Pack Total Current";
CM_ SG_ 374 Checksum_0x176 "Checksum";
CM_ SG_ 374 Rolling_Counter_0x176 "Rolling Counter";
CM_ SG_ 374 BMS_HVPackVol_MEAS "Pack Voltage";
CM_ SG_ 374 BMS_HVLinkVol_MEAS "Link Voltage";
CM_ SG_ 375 Checksum_0x177 "Checksum";
CM_ SG_ 375 Rolling_Counter_0x177 "Rolling Counter";
CM_ SG_ 375 BMS_HVBusVol_MEAS "BUS Voltage, it is informative";
CM_ SG_ 375 BMS_HVFuseVol_MEAS "Measure voltage after fuse to identify the fuse is blown or not";
CM_ SG_ 375 BMS_MainNegRelay_Volt "main negative relay diagnosis voltage";
CM_ SG_ 482 BCM_PowerState "BCM_PowerState";
CM_ SG_ 482 PEPS_Learning_Status "PEPS System learning status";
CM_ SG_ 482 PEPS_PowerModeValidity "PEPS Power Distribution StatusValidity bit";
CM_ SG_ 482 PEPS_PowerMode "PEPS Power Distribution Status";
CM_ SG_ 482 BCM_WPC_Off_Req "BCM request WPC Off";
CM_ SG_ 482 PEPS_CL15cRelayValidity "IGN1 output validity";
CM_ SG_ 482 PEPS_CL15cRelaySts "IGN1 output status";
CM_ SG_ 482 FL_PassiveEntryButton_Sts  "FL PE door button";
CM_ SG_ 482 FR_PassiveEntryButton_Sts  "FR PE door button";
CM_ SG_ 482 PEPS_CL30sRelaySts  "CL30s status";
CM_ SG_ 517 Checksum_0x205 "Checksum";
CM_ SG_ 517 Rolling_Counter_0x205 "Rolling Counter";
CM_ SG_ 517 BMS_CellNumMinCellVol "Cell Number of Min Cell Voltage";
CM_ SG_ 517 BMS_CellNumMaxCellVol "Cell Number of Max Cell Voltage";
CM_ SG_ 517 BMS_MinCellVol "Min Cell Voltage";
CM_ SG_ 517 BMS_MaxCellVol "Max Cell Voltage";
CM_ SG_ 518 Checksum_0x206 "Checksum";
CM_ SG_ 518 Rolling_Counter_0x206 "Rolling Counter";
CM_ SG_ 518 BMS_MaxMinDiffCellVol "max and min cell voltage differences";
CM_ SG_ 521 Checksum_0x209 "Checksum";
CM_ SG_ 521 Rolling_Counter_0x209 "Rolling Counter";
CM_ SG_ 521 BMS_MaxDischgPwr_ALW "Allow Max Discharge Power accepted";
CM_ SG_ 521 BMS_MaxChgPwr_ALW "Allow Max Regenerative Power accepted.";
CM_ SG_ 521 BMS_MaxDischgPwr_Peak "Allow Max Discharge Power accepted in 30s";
CM_ SG_ 521 BMS_MaxChgPwr_Peak "Allow Max Regenerative Power accepted in 30s.";
CM_ SG_ 532 Checksum_0x214 "Checksum";
CM_ SG_ 532 Rolling_Counter_0x214 "Rolling Counter";
CM_ SG_ 532 BMS_Display_SOC "Display SOC";
CM_ SG_ 532 BMS_SOCE "State of certified energy";
CM_ SG_ 533 Checksum_0x215 "Checksum";
CM_ SG_ 533 Rolling_Counter_0x215 "Rolling Counter";
CM_ SG_ 533 BMS_BatBalance_ERR "Battery Balance Error indicates Balancing switch is short or open";
CM_ SG_ 533 BMS_Balance_STS "BMS Balance Status";
CM_ SG_ 533 BMS_IGN_Sts "the ignition signal status (on/off)";
CM_ SG_ 533 BMS_HWCrash_Sts "Battery Pack Hardware Crash signal Status";
CM_ SG_ 533 BMS_HVIL_STS "The HVIL state of BMS";
CM_ SG_ 533 BMS_HVOnOff_STS "Status of the High Voltage";
CM_ SG_ 533 BMS_ERR_LEV "BMS requesting CVC to operate at the limited operating strategy (LOS)";
CM_ SG_ 533 BMS_SocActual_EST "Actual SOC";
CM_ SG_ 533 BMS_Sys_STS "BMS_Status(Self-test after BMS wake-up) BMS CVC";
CM_ SG_ 533 BMS_ISU_Status "Pack Insulation Status";
CM_ SG_ 533 BMS_SOH "BMS State Of Health";
CM_ SG_ 533 BMS_SOE "BMS State Of Enegy";
CM_ SG_ 533 BMS_HV_Sts "HV Status";
CM_ SG_ 534 Checksum_0x216 "Checksum";
CM_ SG_ 534 Rolling_Counter_0x216 "Rolling Counter";
CM_ SG_ 534 BMS_RemainChargeTime "Remain Charge Time send to other ECU (XGW - IPC)";
CM_ SG_ 534 BMS_ChgVoltage_REQ "Charge Voltage Request";
CM_ SG_ 534 BMS_ChgCurrent_REQ "Charge Current Request";
CM_ SG_ 537 EVCC_OBC_StsModeReq "BMS Mode Request of OBC";
CM_ SG_ 537 EVCC_ACChgVoltAllow "BMS AC Charge Voltage Allow";
CM_ SG_ 537 EVCC_ACChgCurReq "BMS AC Charge Current Request";
CM_ SG_ 537 EVCC_S2_Sts "S2 State";
CM_ SG_ 537 EVCC_StsChgCC "Charge CC State";
CM_ SG_ 537 EVCC_CP_DutyCycle "CP duty cycle";
CM_ SG_ 544 CHSKM_CVC_BMS_Thermal_FB "Checksum";
CM_ SG_ 544 ALIV_CVC_BMS_Thermal_FB "Rolling Counter";
CM_ SG_ 544 CVC_BMS_PTCOnOff_Sts "CVC sends the status of the PTC Heater";
CM_ SG_ 544 CVC_BMS_PumpFB "CVC sends the PUMP feedback";
CM_ SG_ 549 Checksum_0x225 "Checksum";
CM_ SG_ 549 Rolling_Counter_0x225 "Rolling Counter";
CM_ SG_ 549 CDM_bAcvCanComStblMon "Monitored flag indicating active stable CAN communication.";
CM_ SG_ 549 FRMo_bErrHvbatStReqExtMon "Collective error flag indicating HV battery state request E2E fault.";
CM_ SG_ 549 FRMo_bErrChrgnAllwdExtMon "Collective error flag indicating charging allowed E2E fault.";
CM_ SG_ 549 FRMo_bErrVehCrashStExtMon "Collective error flag indicating vehicle crash state E2E fault.";
CM_ SG_ 549 CDM_bErrComctnLossCanMon "Error flag indicating total loss of CAN communication fault";
CM_ SG_ 549 CTCMon_bErrCtctrSopcMon "Error flag indicating contactor switch-off path test fault.";
CM_ SG_ 549 CTCMon_bInvldCtctrHisdIFbMon "Error flag indicating high-side feedback current invalidity.";
CM_ SG_ 549 CTCMon_bInvldCtctrLosdUFbMon "Error flag indicating low-side feedback voltage invalidity.";
CM_ SG_ 549 CTM_bErrCellTDifMaxMon "Error flag indicating maximum cell temperature difference fault.";
CM_ SG_ 549 CTM_bErrCellTMaxMon "Error flag indicating maximum cell temperature limit fault.";
CM_ SG_ 549 CTM_bErrCellTMinMon "Error flag indicating minimum cell temperature limit fault.";
CM_ SG_ 549 CTM_bErrThrwyPredMon "Error flag indicating thermal runaway fault.";
CM_ SG_ 549 CUM_bErrCellUDifMaxMon "Error flag indicating maximum cell voltage difference fault.";
CM_ SG_ 549 CUM_bErrCellUMaxMon "Error flag indicating cell overvoltage fault.";
CM_ SG_ 549 CUM_bErrCellUMinMon "Error flag indicating cell undervoltage fault.";
CM_ SG_ 549 CUM_bErrCellUProtnMaxNvMon "Non-volatile error flag indicating cell overvoltage protection limit fault.";
CM_ SG_ 549 CUM_bErrCellUProtnMinNvMon "Non-volatile error flag indicating cell undervoltage protection limit fault.";
CM_ SG_ 549 CUM_bErrPackUImplyMon "Error flag indicating pack voltage implausibility.";
CM_ SG_ 549 EHPMon_bRdyHvilMon "Ready flag indicating operational HVIL circuit.";
CM_ SG_ 549 EHPMon_bErrWlddNegNvMon "Non-volatile error flag indicating welded negative contactor fault.";
CM_ SG_ 549 EHPMon_bErrWlddPosNvMon "Non-volatile error flag indicating welded positive contactor fault.";
CM_ SG_ 549 EHPMon_bErrWlddPrechNvMon "Non-volatile error flag indicating welded precharge contactor fault.";
CM_ SG_ 549 EHPMon_bErrHvilMon "Error flag indicating HVIL open line fault.";
CM_ SG_ 549 EHPMon_bErrHvilShoMon "Error flag indicating HVIL invalidity (ScG/ScB) fault.";
CM_ SG_ 549 EHPMon_bErrPackIslnRNvMon "Non-volatile error flag indicating pack level isolation resistance fault.";
CM_ SG_ 549 EHPMon_bErrVehCrashNvMon "Non-volatile error flag indicating vehicle crash fault.";
CM_ SG_ 549 EHPMon_bErrVehIslnRNvMon "Non-volatile error flag indicating vehicle level isolation resistance fault.";
CM_ SG_ 549 FRMo_bErrMemStorgNvMon "Error flag indicating storage fault in the non-volatile memory.";
CM_ SG_ 549 L1IM_bErrClmp30MaxMonInp "Error flag indicating Level 1 KL30 overvoltage fault.";
CM_ SG_ 549 L1IM_bErrClmp30MinMonInp "Error flag indicating Level 1 KL30 undervoltage fault.";
CM_ SG_ 549 L1IM_bErrCtctrDtrtMonInp "Error flag indicating Level 1 contactor deterioration";
CM_ SG_ 549 L1IM_bErrUActImplyMonInp "Error flag indicating Level 1 high voltage implausibility.";
CM_ SG_ 549 MCCM_bAcvMdulCtlrStsMon "Active flag indicating operational module controller status.";
CM_ SG_ 549 MCCM_bErrLntecSngFltMon "Error flag indicating single-point safety mechanism fault of the Multi-Stack Battery Monitor.";
CM_ SG_ 549 MCCM_bErrLntecLtntFltMon "Error flag indicating latent safety mechanism fault of the Multi-Stack Battery Monitor.";
CM_ SG_ 549 MCCM_bErrMdulCellSnsrCfgMon "Error flag indicating module/cell/temperature sensor configuration fault.";
CM_ SG_ 549 MCCM_bErrMdulCtlrComMon "Error flag indicating module controller communication status fault.";
CM_ SG_ 549 MCCM_bErrSnsrTEltlMon "Error flag indicating multiple temperature sensor in a module fault.";
CM_ SG_ 549 MCCM_bWarnSnsrTEltlMon "Error flag indicating single temperature sensor in a module fault.";
CM_ SG_ 549 PCM_bRdySnsrIMon "Ready flag indicating operational current sensors.";
CM_ SG_ 549 PCM_bErrPackEFlowMaxLimMon "Error flag indicating energy flow limit fault.";
CM_ SG_ 549 PCM_bErrPackIChDchaMaxLimMon "Error flag indicating pack current charging/discharging limit fault.";
CM_ SG_ 549 PCM_bErrSnsrIImplyMon "Error flag indicating current sensor implausibility fault.";
CM_ SG_ 549 FRMo_bErrSnsrI1ExtMon "Collective error flag indicating current sensor 1 (CAN-based shunt sensor) E2E fault.";
CM_ SG_ 549 PCM_bInvldSnsrI1Mon "Error flag indicating current sensor 1 invalidity fault.";
CM_ SG_ 549 PCM_bInvldSnsrI2Mon "Error flag indicating current sensor 2 invalidity fault.";
CM_ SG_ 549 FRMo_bErrSopcLvl3Mon "Error flag indicating Level 3 switch-off path test fault.";
CM_ SG_ 549 BMS_FRMo_Reserved_1 "Fault monitor signal";
CM_ SG_ 549 BMS_FRMo_Reserved_2 "Fault monitor signal";
CM_ SG_ 549 BMS_FRMo_Reserved_3 "Fault monitor signal";
CM_ SG_ 549 BMS_FRMo_Reserved_4 "Fault monitor signal";
CM_ SG_ 549 BMS_FRMo_Reserved_5 "Fault monitor signal";
CM_ SG_ 550 Checksum_0x226 "Checksum";
CM_ SG_ 550 Rolling_Counter_0x226 "Rolling Counter";
CM_ SG_ 550 BMS_QMMo_Reserved_0 "QM fault monitoring signals";
CM_ SG_ 550 BMS_QMMo_Reserved_1 "QM fault monitoring signals";
CM_ SG_ 550 BMS_QMMo_Reserved_2 "QM fault monitoring signals";
CM_ SG_ 550 BMS_QMMo_Reserved_3 "QM fault monitoring signals";
CM_ SG_ 550 BMS_QMMo_Reserved_4 "QM fault monitoring signals";
CM_ SG_ 550 BMS_QMMo_Reserved_5 "QM fault monitoring signals";
CM_ SG_ 550 BMS_QMMo_Reserved_6 "QM fault monitoring signals";
CM_ SG_ 550 BMS_QMMo_Reserved_7 "QM fault monitoring signals";
CM_ SG_ 550 BMS_QMMo_Reserved_8 "QM fault monitoring signals";
CM_ SG_ 550 BMS_QMMo_Reserved_9 "QM fault monitoring signals";
CM_ SG_ 550 BMS_QMMo_Reserved_10 "QM fault monitoring signals";
CM_ SG_ 550 BMS_QMMo_Reserved_11 "QM fault monitoring signals";
CM_ SG_ 550 CDEM_ErrDisp_0 "The error display array stores the recently active errors IDs. If a new error occurs the oldest error ID will be removed.";
CM_ SG_ 550 CDEM_ErrDisp_1 "The error display array stores the recently active errors IDs. If a new error occurs the oldest error ID will be removed.";
CM_ SG_ 563 CVC_FMCU_Limit_CheckSum "Checksum of this message";
CM_ SG_ 563 CVC_FMCU_Limit_AliveCounter "Signal counting the times of this message";
CM_ SG_ 563 CVC_FMCU_DischgPwrLim "Limit Front Motor Discharge Power";
CM_ SG_ 563 CVC_FMCU_RegenPwrLim "Limit Front Motor Regen Power";
CM_ SG_ 564 CVC_DCDC_StsModeReq "CVC to DCDC control command";
CM_ SG_ 564 CVC_enableDCDC "Requests DCDC to turn on";
CM_ SG_ 564 CVC_vDCDCRequest "voltage output request for DCDC";
CM_ SG_ 564 CVC_DCDC_CurrentLim "Limit DCDC Output Current";
CM_ SG_ 564 CVC_DCDC_PwrPermit "Permit DCDC Output Power";
CM_ SG_ 568 FMCU_DampingState "FMCU Damping state";
CM_ SG_ 568 FMCU_IGBTState "FMCU IGBT State";
CM_ SG_ 581 Checksum_0x245 "Checksum";
CM_ SG_ 581 Rolling_Counter_0x245 "Rolling Counter";
CM_ SG_ 581 BMS_ProbeNumMaxCellTemp "Probe Number of Max Cell Temperature";
CM_ SG_ 581 BMS_MinCellTemp "Min Cell Temperature";
CM_ SG_ 581 BMS_ProbeNumMinCellTemp "Probe Number of Min Cell Temperature";
CM_ SG_ 581 BMS_PackTemp "Pack Temperature";
CM_ SG_ 581 BMS_MaxCellTemp "Max Cell Temperature";
CM_ SG_ 581 BMS_MaxMinDiffCellTemp "max and min cell temperature differences";
CM_ SG_ 584 CHSKM_BMS_CVC_THMReq "Check sum";
CM_ SG_ 584 ALV_BMS_CVC_THMReq "Alive counter";
CM_ SG_ 584 BMS_FlowRate_Req "Flow rate required";
CM_ SG_ 584 BMS_CoolPwrDemand "requesting the cooling power required fro the battery pack";
CM_ SG_ 584 BMS_HeatPwrDemand "requesting the heating power required fro the battery pack";
CM_ SG_ 584 BMS_CVC_PTCOnOff_Req "PTC Heater turn on and off request";
CM_ SG_ 584 BMS_CVC_ValveOnOff_Req "requesting CVC to turn on and off the valve";
CM_ SG_ 584 BMS_PreHeatCoolReq "Battery pack precondition information";
CM_ SG_ 584 BMS_InletTemp_Req "Target water inlet temperature request";
CM_ SG_ 585 CHSKM_BMS_CoolntInletOutletTmp "Check sum";
CM_ SG_ 585 ALV_BMS_CoolntInletOutletTmp "Alive counter";
CM_ SG_ 585 BMS_CoolantInletTemp "Temperature of Battery Coolant Inlet";
CM_ SG_ 585 BMS_CoolantOutletTemp "Temperature of Battery Coolant Outlet";
CM_ SG_ 585 BMS_BDUTemp1 "BDU Temperature";
CM_ SG_ 585 BMS_BDUTemp2 "BDU Temperature";
CM_ SG_ 593 EVCC_ChargeMode "Charge mode";
CM_ SG_ 593 EVCC_StsElock "Electronic Lock status";
CM_ SG_ 593 EVCC_PP_Sts "PP status";
CM_ SG_ 593 EVCC_S2_Sts "S2 State";
CM_ SG_ 593 EVCC_CCS2_CPSts "CCS2 CP Status CP";
CM_ SG_ 593 EVCC_CCS2_CPdutycycle "CCS2 CP duty cycle CP";
CM_ SG_ 593 EVCC_DCChgPosTemp "The Positive Temperature of DC Charging";
CM_ SG_ 593 EVCC_DCChgNegTemp "The Negative Temperature of DC Charging";
CM_ SG_ 593 EVCC_ACChgL1TerminalTemp "Temperature of AC Charging L terminal";
CM_ SG_ 593 EVCC_ACChgNTerminalTemp_Reserve "Temperature of AC Charging  N terminal_Reserve";
CM_ SG_ 662 DCDC_OutputCurrent "Output Current";
CM_ SG_ 662 DCDC_StsCtrl "DCDC Control Status to CVC";
CM_ SG_ 662 DCDC_StsDCDCFault "DCDC Fault Status";
CM_ SG_ 662 DCDC_InputCurrent "Input Current";
CM_ SG_ 662 DCDC_OutputVolt "Output Voltage";
CM_ SG_ 662 DCDC_InputVolt "Input Voltage";
CM_ SG_ 662 HVAS_BMS_DCChgRelayVolt "DC Charge Relay Volt";
CM_ SG_ 662 PDU_HVIL_Status "PDU HVIL Status";
CM_ SG_ 662 PDU_DCNegRelay_Sts "DC Neg Relay Ststus";
CM_ SG_ 662 PDU_DCPosRelay_Sts "DC Pos Relay Ststus";
CM_ SG_ 663 DCDC_CVC_Temp "Temperature";
CM_ SG_ 663 DCDC_CVC_OverTemp "Temperature too high alarm of DCDC";
CM_ SG_ 663 DCDC_HWFault "Hardware Fault of DCDC";
CM_ SG_ 663 DCDC_OutPwrOver "Output power over alarm of DCDC";
CM_ SG_ 663 DCDC_OutCurOver "Output current too high alarm of DCDC";
CM_ SG_ 663 DCDC_OutVoltOver "Output voltage too high alarm of DCDC";
CM_ SG_ 663 DCDC_OutVoltUnder "Output voltage too low alarm of DCDC";
CM_ SG_ 663 DCDC_InVoltOver "Input voltage too high alarm of DCDC";
CM_ SG_ 663 DCDC_InVoltUnder "Input voltage too low alarm of DCDC";
CM_ SG_ 663 DCDC_OutCircuitShort "Output Short circuit alarm of DCDC";
CM_ SG_ 663 DCDC_OutHWOpen "Hardware open circuit Fault of DCDCs output";
CM_ SG_ 663 DCDC_InternalCommFault "Internal Communication fault of DCDC";
CM_ SG_ 663 DCDC_CVCLostFault "CVC lost communication fault";
CM_ SG_ 663 DCDC_CANBusoffFault "CAN busoff fault";
CM_ SG_ 663 DCDC_WakeupInMissing "WakeupInput Missing Fault";
CM_ SG_ 663 DCDC_12VFault "12V supply Fault";
CM_ SG_ 664 OBC_CVC_ACDisChgVoltAllow "CVC allow OBC Invert AC discharge voltage";
CM_ SG_ 664 OBC_InvertDCCurrlnOC "OBC inverter DC current input over current";
CM_ SG_ 664 OBC_InvertDCVoltlnUV "OBC inverter DC  voltage input under voltage";
CM_ SG_ 664 OBC_InvertDCVoltlnOV "OBC inverter DC  voltage input over voltage";
CM_ SG_ 664 OBC_InvertVoltPfcUV "OBC inverter voltage Pfc under voltage";
CM_ SG_ 664 OBC_InvertVoltPfcOV "OBC inverter voltage Pfc over voltage";
CM_ SG_ 664 OBC_InvertAcCurrOutOC "OBC inverter AC current output over current";
CM_ SG_ 664 OBC_InvertAcVoltOutOV "OBC inverter AC voltage output over voltage";
CM_ SG_ 664 OBC_InvertAcVoltOutUV "OBC inverter AC voltage output under voltage";
CM_ SG_ 664 OBC_InvertOTRedu "OBC inverter over temperature reduce power";
CM_ SG_ 664 OBC_InvertOTShut "OBC inverter over temperature shutdown";
CM_ SG_ 664 OBC_Invert_Power "OBC Invert Power";
CM_ SG_ 670 Time_second "Time_second";
CM_ SG_ 670 Time_Minute "Time_Minute";
CM_ SG_ 670 Time_Hour "Time_Hour";
CM_ SG_ 670 Time_Day "Time_Day";
CM_ SG_ 670 Time_Month "Time_Month";
CM_ SG_ 670 Time_Year "Time_Year";
CM_ SG_ 694 OBC_Status_CheckSum "Checksum of this message";
CM_ SG_ 694 OBC_Status_AliveCounter "Signal counting the times of this message";
CM_ SG_ 694 DCDC_Err_Lvl "DCDC error level";
CM_ SG_ 694 OBC_StsMode "Mode Status";
CM_ SG_ 694 OBC_BMS_ChgFaultReq "System Charge Fault Status Request";
CM_ SG_ 694 OBC_Err_Lvl "OBC error status";
CM_ SG_ 694 POD_phaseACInput "OBC actual input phase";
CM_ SG_ 694 POD_statusDCDC "DCDC status";
CM_ SG_ 694 POD_DCDC_Max_Current_Out "Max LV current DCDC able to output";
CM_ SG_ 695 OBC_BMS_MaxCurDC "DC Max Output Current Available";
CM_ SG_ 695 OBC_BMS_MaxCurAC "AC Max Input Current Available";
CM_ SG_ 695 OBC_BMS_ActVoltDC "DC actual Voltage";
CM_ SG_ 695 OBC_BMS_ActCurDC "DC actual current";
CM_ SG_ 695 OBC_BMS_ActVoltAC "AC actual Voltage";
CM_ SG_ 695 OBC_BMS_ActCurAC "AC actual current";
CM_ SG_ 746 CVC_SW_Versions "CVC software version";
CM_ SG_ 746 CVC_Fan_Sts "CVC control fan status";
CM_ SG_ 746 CVC_DCChgPosTemp "The Positive Temperature of DC Charging";
CM_ SG_ 746 CVC_DCChgNegTemp "The Negative Temperature of DC Charging";
CM_ SG_ 746 CVC_ACChgLTerminalTemp "Temperature of AC Charging L terminal";
CM_ SG_ 746 CVC_ACChgNTerminalTemp_Reserve "Temperature of AC Charging  N terminal_Reserve";
CM_ SG_ 746 CVC_EdrivePump_Sts "Electric drive water pump working status";
CM_ SG_ 746 CVC_BatPump_Sts "Battery water pump working status";
CM_ SG_ 773 CHSKM_BMS_Insulation "Checksum";
CM_ SG_ 773 ALV_BMS_Insulation "Rolling Counter";
CM_ SG_ 773 BMS_CVC_Insulation_Mon_Sts "Feedback for the Insulation Monitoring signal";
CM_ SG_ 773 BMS_PackInsuRes "Minimum value of BCU_PosInsuRes and BCU_NegInsuRes";
CM_ SG_ 807 IVI_RearBlowerLevelSet "Rear Blower Level Setting";
CM_ SG_ 807 IVI_BlowerLevelSet "Blower Level Setting";
CM_ SG_ 807 IVI_SetBlowMode "Set blow mode";
CM_ SG_ 807 IVI_SetDriverTemp "Set Driver Temp level";
CM_ SG_ 807 IVI_FrontDefrostReq "Front Defrost Req";
CM_ SG_ 807 IVI_Recirculation "Loop mode Button";
CM_ SG_ 807 IVI_PM2_5_Req "PM2.5 Request";
CM_ SG_ 807 IVI_MaxAC "Max AC";
CM_ SG_ 807 IVI_MaxDefrost "Max Defrost";
CM_ SG_ 807 IVI_AutoAC_OnOff "Auto AC OnOff";
CM_ SG_ 807 IVI_AC_OnOff_Req "AC OnOff Request";
CM_ SG_ 807 IVI_RearAC_OnOff_Req "Rear AC OnOff Request from IVI";
CM_ SG_ 811 CCU_PTC_Req "CCU request CVC to enable or disable PTC";
CM_ SG_ 811 CCU_AC_Req "Compressor request switch signal";
CM_ SG_ 811 CCU_BlowerRelaySts "Blower power relay connection control output (12V+)";
CM_ SG_ 811 CCU_RearBlowerRelaySts "Rear Blower (On/Off) CCU-Blower";
CM_ SG_ 811 CCU_AUTO_Status "AC AUTO_Status";
CM_ SG_ 811 CCU_FrontDefrostSts "Front Defrost_Status";
CM_ SG_ 811 CCU_AC_Sts "CCU AC mode status";
CM_ SG_ 811 CCU_Circulation_Sts "CCU intake cycle state";
CM_ SG_ 811 CCU_ExternalTemperatureFailSts "External Temperature Fail Sts";
CM_ SG_ 811 CCU_CirculationmotorPos "Feedback signal of internal and external circulation air door position";
CM_ SG_ 811 CCU_RearAC_Sts "CCU Rear AC mode status";
CM_ SG_ 811 CCU_MaxAC_Sts "CCU MaxAC mode status";
CM_ SG_ 811 CCU_BlowerPWM "Blower control output";
CM_ SG_ 811 CCU_LightSensor "Sensor Signal（sunshine）";
CM_ SG_ 811 CCU_ExternalTemperature "External Temperature";
CM_ SG_ 811 CCU_PTC_Relay_Status "PTC relay actual status";
CM_ SG_ 815 CVC_RearBlowerRelay_Req "Rear Blower relay control request";
CM_ SG_ 815 CVC_BlowerRelay_Req "Front Blower relay control request";
CM_ SG_ 815 CVC_FrontBlower_PWM_Req "Blower control PWM request";
CM_ SG_ 815 CVC_RearBlower_PWM_Req "Rear blower control PWM request";
CM_ SG_ 815 CVC_PTC_Relay_Request "PTC relay control request";
CM_ SG_ 815 CVC_BlowMode_Pos_Req "Blow mode motor position request";
CM_ SG_ 815 CVC_Recirculation_Pos_Req "Recirculation position request";
CM_ SG_ 815 CVC_TempFlap_Pos_Req "Temperature motor position request";
CM_ SG_ 822 CVC_FrontBlower_Level "CVC blower level processing";
CM_ SG_ 822 CVC_RearBlower_Level "CVC rear blower level processing";
CM_ SG_ 822 CVC_BlowMode_Sts "CVC blow mode status processing";
CM_ SG_ 822 CVC_Recirculation_Status "CVC recirculation status processing";
CM_ SG_ 822 CVC_CabinThermalMode "Actual cabin climate active mode";
CM_ SG_ 822 CVC_RearAC_Sts "Rear AC status ";
CM_ SG_ 822 CVC_CoolPwrDemand "Front cooling power calculation";
CM_ SG_ 822 CVC_RearCoolPwrDemand "Rear cooling power calculation";
CM_ SG_ 822 CVC_HeatPwrDemand "Heat power demand calculation";
CM_ SG_ 822 CVC_HVAC_Managment "HVAC cooling and heating mode";
CM_ SG_ 812 CCU_CoolPwrDemand "Requesting the cooling power required for CCU";
CM_ SG_ 812 CCU_Rear_Blower_Sts "Rear Blower Status";
CM_ SG_ 812 CCU_BlowMode_Sts "Blow Mode_Status";
CM_ SG_ 812 CCU_Dr_Side_BlowerLevelSts "Blower_Level";
CM_ SG_ 812 CCU_Dr_Side_TempGearSts "Driver Side Temperature Gear Status";
CM_ SG_ 812 CCU_RearCoolPwrDemand "Requesting the Rear cooling power required for CCU";
CM_ SG_ 812 CCU_VehicleInternalTemp "Vehicle internal temperature";
CM_ SG_ 812 PTC_InletAirTemp "Inlet air temperature sensor";
CM_ SG_ 814 CCU_TempMotorPos "Temperature motor position signal";
CM_ SG_ 814 PTC_OutletAirTemp "Outlet air temperature sensor";
CM_ SG_ 814 CCU_EvapTemp "Sensor Signal（evaporator）Front HVAC";
CM_ SG_ 814 CCU_VentDuctAirTemp "Vent/Panel Duct Air Temp Sensor";
CM_ SG_ 814 CCU_FootDuctAirTemp "Foot Duct Air Temp Sensor";
CM_ SG_ 814 CCU_RearEvapTemp "Rear HVAC Evap Temp Sensor (Freezing Protection)";
CM_ SG_ 814 CCU_RearBlowerPWM "Rear Blower (Speed Control) CCU-Blower";
CM_ SG_ 814 CCU_RearBlowerVFb "Rear Blower (Feedback Rear Blower to CCU)";
CM_ SG_ 816 Checksum_0x330 "Checksum";
CM_ SG_ 816 Rolling_Counter_0x330 "Rolling Counter";
CM_ SG_ 816 BMS_ContactorAging "Aging condition of contactor - PreCharge Realy - Positive Contactor - Negative Contactor";
CM_ SG_ 817 CCH_Rear_Blower_Increase "Rear Blower Increase Button";
CM_ SG_ 817 CCH_Rear_Blower_Decrease "Rear Blower Decrease Button";
CM_ SG_ 817 CCH_RearAC_OnOff_Req "CCH RearAC OnOff Req from CCH";
CM_ SG_ 818 Checksum_0x332 "Checksum";
CM_ SG_ 818 Rolling_Counter_0x332 "Rolling Counter";
CM_ SG_ 818 BMS_PackCNom "Nominal capacity of the battery pack";
CM_ SG_ 818 BMS_PackTemp_0x332 "Pack Temperature";
CM_ SG_ 819 BMS_SwVers_Type "BMS software scheme number";
CM_ SG_ 819 BMS_SwVersS_phase "BMS software version number";
CM_ SG_ 819 BMS_swVers_version "BMS version number";
BA_DEF_  "NmAsrBaseAddress" HEX 0 2047;
BA_DEF_  "NmAsrCanMsgCycleTime" INT 0 65535;
BA_DEF_  "NmAsrMessageCount" INT 0 256;
BA_DEF_  "NmAsrTimeoutTime" INT 0 65535;
BA_DEF_  "NmAsrWaitBusSleepTime" INT 0 65535;
BA_DEF_  "NmType" STRING ;
BA_DEF_ BU_  "TpSTMin" INT 0 255;
BA_DEF_ BU_  "Address" HEX 0 255;
BA_DEF_ BU_  "NmAsrCanMsgCycleOffset" INT 0 65535;
BA_DEF_ BU_  "NmAsrCanMsgReducedTime" INT 320 640;
BA_DEF_ BU_  "NmAsrNode" ENUM  "No","Yes";
BA_DEF_ BU_  "NmAsrNodeIdentifier" HEX 0 255;
BA_DEF_ BU_  "NmStationAddress" HEX 0 0;
BA_DEF_ SG_  "GenSigSendType" ENUM  "Cyclic","OnWrite","OnWriteWithRepetition","OnChange","OnChangeWithRepetition","IfActive","IfActiveWithRepetition","NoSigSendType","NotUsed","NotUsed","NotUsed","NotUsed","NotUsed";
BA_DEF_ SG_  "GenSigTimeoutTime_ALL" INT 0 65535;
BA_DEF_ SG_  "InvalidValue" STRING ;
BA_DEF_ BO_  "GenMsgCycleTimeFast" INT 0 0;
BA_DEF_ BO_  "NmAsrMessage" ENUM  "No","Yes";
BA_DEF_ BO_  "GenMsgILSupport" ENUM  "No","Yes";
BA_DEF_ BO_  "GenMsgNrOfRepetition" INT 0 0;
BA_DEF_ BO_  "GenMsgDelayTime" INT 0 0;
BA_DEF_ BO_  "DiagUudtResponse" ENUM  "False","True";
BA_DEF_ BO_  "DiagState" ENUM  "No","Yes";
BA_DEF_ BO_  "DiagResponse" ENUM  "No","Yes";
BA_DEF_ BO_  "DiagRequest" ENUM  "No","Yes";
BA_DEF_  "BusType" STRING ;
BA_DEF_  "Manufacturer" STRING ;
BA_DEF_  "EcuName" STRING ;
BA_DEF_  "DBName" STRING ;
BA_DEF_ BO_  "GenMsgCycleTime" INT 0 65535;
BA_DEF_ BO_  "GenMsgSendType" ENUM  "Cyclic","Event","Mix";
BA_DEF_ BO_  "GenMsgStartDelayTime" INT 0 65535;
BA_DEF_ SG_  "GenSigStartValue" HEX 0 0;
BA_DEF_DEF_  "NmAsrBaseAddress" 1280;
BA_DEF_DEF_  "NmAsrCanMsgCycleTime" 640;
BA_DEF_DEF_  "NmAsrMessageCount" 128;
BA_DEF_DEF_  "NmAsrTimeoutTime" 2000;
BA_DEF_DEF_  "NmAsrWaitBusSleepTime" 1500;
BA_DEF_DEF_  "NmType" "NmAsr";
BA_DEF_DEF_  "TpSTMin" 20;
BA_DEF_DEF_  "Address" 0;
BA_DEF_DEF_  "NmAsrCanMsgCycleOffset" 0;
BA_DEF_DEF_  "NmAsrCanMsgReducedTime" 320;
BA_DEF_DEF_  "NmAsrNode" "No";
BA_DEF_DEF_  "NmAsrNodeIdentifier" 0;
BA_DEF_DEF_  "NmStationAddress" 0;
BA_DEF_DEF_  "GenSigSendType" "Cyclic";
BA_DEF_DEF_  "GenSigTimeoutTime_ALL" 0;
BA_DEF_DEF_  "InvalidValue" "";
BA_DEF_DEF_  "GenMsgCycleTimeFast" 0;
BA_DEF_DEF_  "NmAsrMessage" "No";
BA_DEF_DEF_  "GenMsgILSupport" "Yes";
BA_DEF_DEF_  "GenMsgNrOfRepetition" 0;
BA_DEF_DEF_  "GenMsgDelayTime" 0;
BA_DEF_DEF_  "DiagUudtResponse" "False";
BA_DEF_DEF_  "DiagState" "No";
BA_DEF_DEF_  "DiagResponse" "No";
BA_DEF_DEF_  "DiagRequest" "No";
BA_DEF_DEF_  "BusType" "";
BA_DEF_DEF_  "Manufacturer" "VinFast";
BA_DEF_DEF_  "EcuName" "";
BA_DEF_DEF_  "DBName" "";
BA_DEF_DEF_  "GenMsgCycleTime" 100;
BA_DEF_DEF_  "GenMsgSendType" "Cyclic";
BA_DEF_DEF_  "GenMsgStartDelayTime" 0;
BA_DEF_DEF_  "GenSigStartValue" 0;
BA_ "EcuName" "PCAN";
BA_ "BusType" "CAN";
BA_ "Manufacturer" "VF";
BA_ "DBName" "PCAN";
BA_ "NmAsrNode" BU_ BMS 1;
BA_ "NmAsrCanMsgCycleOffset" BU_ BMS 95;
BA_ "Address" BU_ BMS 19;
BA_ "NmStationAddress" BU_ EVCC 31;
BA_ "NmAsrNodeIdentifier" BU_ EVCC 31;
BA_ "NmAsrNode" BU_ EVCC 1;
BA_ "NmAsrCanMsgReducedTime" BU_ EVCC 395;
BA_ "NmAsrCanMsgCycleOffset" BU_ EVCC 155;
BA_ "Address" BU_ EVCC 31;
BA_ "Address" BU_ FMCU 27;
BA_ "Address" BU_ CVC_P 2;
BA_ "Address" BU_ PDU 61;
BA_ "Address" BU_ PTC 70;
BA_ "Address" BU_ CCU 9;
BA_ "GenMsgCycleTime" BO_ 128 20;
BA_ "GenMsgCycleTime" BO_ 170 10;
BA_ "GenMsgCycleTime" BO_ 171 10;
BA_ "GenMsgCycleTime" BO_ 201 10;
BA_ "GenMsgCycleTime" BO_ 202 10;
BA_ "GenMsgCycleTimeFast" BO_ 279 20;
BA_ "GenMsgNrOfRepetition" BO_ 279 3;
BA_ "GenMsgCycleTime" BO_ 280 20;
BA_ "GenMsgCycleTime" BO_ 293 20;
BA_ "GenMsgILSupport" BO_ 294 0;
BA_ "GenMsgCycleTime" BO_ 294 20;
BA_ "GenMsgILSupport" BO_ 296 0;
BA_ "GenMsgCycleTime" BO_ 296 20;
BA_ "GenMsgCycleTime" BO_ 306 20;
BA_ "GenMsgCycleTime" BO_ 354 20;
BA_ "GenMsgCycleTime" BO_ 358 20;
BA_ "GenMsgCycleTime" BO_ 1235 1000;
BA_ "GenMsgCycleTimeFast" BO_ 1235 100;
BA_ "GenMsgNrOfRepetition" BO_ 1235 2;
BA_ "GenMsgCycleTime" BO_ 1237 20;
BA_ "GenMsgCycleTime" BO_ 1238 20;
BA_ "GenMsgCycleTime" BO_ 359 20;
BA_ "GenMsgCycleTime" BO_ 368 10;
BA_ "GenMsgCycleTime" BO_ 372 20;
BA_ "GenMsgCycleTime" BO_ 374 50;
BA_ "GenMsgILSupport" BO_ 375 0;
BA_ "GenMsgCycleTime" BO_ 375 50;
BA_ "GenMsgCycleTime" BO_ 482 20;
BA_ "GenMsgCycleTime" BO_ 517 20;
BA_ "GenMsgILSupport" BO_ 518 0;
BA_ "GenMsgCycleTime" BO_ 518 20;
BA_ "GenMsgILSupport" BO_ 521 0;
BA_ "GenMsgCycleTime" BO_ 521 20;
BA_ "GenMsgCycleTime" BO_ 532 50;
BA_ "GenMsgCycleTime" BO_ 533 50;
BA_ "GenMsgILSupport" BO_ 534 0;
BA_ "GenMsgCycleTime" BO_ 534 50;
BA_ "GenMsgILSupport" BO_ 544 0;
BA_ "GenMsgILSupport" BO_ 550 0;
BA_ "GenMsgCycleTime" BO_ 568 20;
BA_ "GenMsgCycleTime" BO_ 581 20;
BA_ "GenMsgILSupport" BO_ 584 0;
BA_ "GenMsgCycleTime" BO_ 526 1000;
BA_ "GenMsgCycleTime" BO_ 670 1000;
BA_ "GenMsgCycleTime" BO_ 746 200;
BA_ "GenMsgILSupport" BO_ 773 0;
BA_ "GenMsgCycleTime" BO_ 775 200;
BA_ "GenMsgILSupport" BO_ 816 0;
BA_ "GenMsgCycleTime" BO_ 819 1000;
BA_ "InvalidValue" SG_ 128 ACU_AliveCounter "Fh";
BA_ "GenSigStartValue" SG_ 128 ACU_In_Disposal_Mode 1;
BA_ "GenSigStartValue" SG_ 128 ACU_Malfunction 1;
BA_ "GenSigStartValue" SG_ 128 ACU_Development_Calibration 1;
BA_ "GenSigStartValue" SG_ 128 ACU_Airbag_Disabled 1;
BA_ "GenSigStartValue" SG_ 128 ACU_In_Plant_Mode 1;
BA_ "GenSigStartValue" SG_ 128 ACU_Pre_Drive_Check 1;
BA_ "InvalidValue" SG_ 170 ALV_CVC_Sts1 "Fh";
BA_ "InvalidValue" SG_ 170 CVC_BMS_HVOnOff_REQ "null";
BA_ "GenSigTimeoutTime_ALL" SG_ 170 CVC_BMS_HVOnOff_REQ 500;
BA_ "InvalidValue" SG_ 171 AliveCounter_0xAB "Fh";
BA_ "GenSigStartValue" SG_ 171 CVC_FMCU_TargetTqReq 4000;
BA_ "GenSigStartValue" SG_ 171 CVC_FMCU_TargetSpeedReq 20000;
BA_ "InvalidValue" SG_ 201 FMCU_Status_AliveCounter "Fh";
BA_ "GenSigStartValue" SG_ 201 FMCU_MotorTq 4000;
BA_ "GenSigStartValue" SG_ 201 FMCU_MotorSpd 20000;
BA_ "GenSigStartValue" SG_ 202 FMCU_CVC_NegTrqLmt 4000;
BA_ "GenSigStartValue" SG_ 202 FMCU_ActInputCurrent 2000;
BA_ "InvalidValue" SG_ 266 CHKSM_BCM_VOLTAGE "null";
BA_ "GenSigTimeoutTime_ALL" SG_ 266 CHKSM_BCM_VOLTAGE 500;
BA_ "InvalidValue" SG_ 266 ALIVE_BCM_VOLTAGE "Fh";
BA_ "GenSigTimeoutTime_ALL" SG_ 266 ALIVE_BCM_VOLTAGE 500;
BA_ "InvalidValue" SG_ 266 LV_BatteryType "-";
BA_ "GenSigTimeoutTime_ALL" SG_ 266 LV_BatteryType 500;
BA_ "InvalidValue" SG_ 266 UBatt "3FFFh";
BA_ "GenSigTimeoutTime_ALL" SG_ 266 UBatt 500;
BA_ "GenSigStartValue" SG_ 266 UBatt 9205;
BA_ "InvalidValue" SG_ 266 LV_Batt_Temp_Reserved "FFh";
BA_ "GenSigTimeoutTime_ALL" SG_ 266 LV_Batt_Temp_Reserved 500;
BA_ "GenSigStartValue" SG_ 266 LV_Batt_Temp_Reserved 40;
BA_ "InvalidValue" SG_ 266 LV_SOC_Reserved "FFh";
BA_ "GenSigTimeoutTime_ALL" SG_ 266 LV_SOC_Reserved 500;
BA_ "InvalidValue" SG_ 266 LV_Batt_Current_Reserved "FFFFh";
BA_ "GenSigTimeoutTime_ALL" SG_ 266 LV_Batt_Current_Reserved 500;
BA_ "GenSigStartValue" SG_ 266 LV_Batt_Current_Reserved 49152;
BA_ "GenSigTimeoutTime_ALL" SG_ 279 CHKSM_BCM_CLAMP_STAT 500;
BA_ "GenSigTimeoutTime_ALL" SG_ 279 ALIVE_BCM_CLAMP_STAT 500;
BA_ "InvalidValue" SG_ 279 ALIVE_BCM_CLAMP_STAT "Fh";
BA_ "GenSigSendType" SG_ 279 RemoteFunctionState 4;
BA_ "GenSigTimeoutTime_ALL" SG_ 279 RemoteFunctionState 500;
BA_ "InvalidValue" SG_ 279 RemoteFunctionState "3h";
BA_ "GenSigTimeoutTime_ALL" SG_ 279 STAT_BLS 500;
BA_ "InvalidValue" SG_ 279 STAT_BLS "3h";
BA_ "GenSigTimeoutTime_ALL" SG_ 279 STAT_CL_50_L 500;
BA_ "InvalidValue" SG_ 279 STAT_CL_50_L "3h";
BA_ "GenSigSendType" SG_ 279 Clamp50AdviceRemoteStart 4;
BA_ "GenSigTimeoutTime_ALL" SG_ 279 Clamp50AdviceRemoteStart 500;
BA_ "InvalidValue" SG_ 279 Clamp50AdviceRemoteStart "3h";
BA_ "GenSigSendType" SG_ 279 Clamp50AdviceESS 4;
BA_ "GenSigTimeoutTime_ALL" SG_ 279 Clamp50AdviceESS 500;
BA_ "InvalidValue" SG_ 279 Clamp50AdviceESS "3h";
BA_ "GenSigTimeoutTime_ALL" SG_ 279 STAT_CL_R_L 500;
BA_ "InvalidValue" SG_ 279 STAT_CL_R_L "3h";
BA_ "GenSigTimeoutTime_ALL" SG_ 279 STAT_CL_15_1_L 500;
BA_ "InvalidValue" SG_ 279 STAT_CL_15_1_L "3h";
BA_ "GenSigTimeoutTime_ALL" SG_ 279 STAT_CL_15_1_DME_L 500;
BA_ "InvalidValue" SG_ 279 STAT_CL_15_1_DME_L "3h";
BA_ "GenSigTimeoutTime_ALL" SG_ 279 FobId 500;
BA_ "InvalidValue" SG_ 279 FobId "3h";
BA_ "GenSigTimeoutTime_ALL" SG_ 279 STAT_Terminal 500;
BA_ "InvalidValue" SG_ 279 STAT_Terminal "7h";
BA_ "GenSigTimeoutTime_ALL" SG_ 279 STAT_CL30_C_BEV 500;
BA_ "InvalidValue" SG_ 279 STAT_CL30_C_BEV "3h";
BA_ "GenSigTimeoutTime_ALL" SG_ 279 BCM_Clamp_Transport 500;
BA_ "InvalidValue" SG_ 279 BCM_Clamp_Transport "7h";
BA_ "InvalidValue" SG_ 280 CVC_VehicleSpeed "1FFFh";
BA_ "GenSigTimeoutTime_ALL" SG_ 280 CVC_VehicleSpeed 200;
BA_ "InvalidValue" SG_ 280 CVC_VehicleSpeedValid "null";
BA_ "GenSigTimeoutTime_ALL" SG_ 280 CVC_VehicleSpeedValid 200;
BA_ "InvalidValue" SG_ 280 CVC_HV_State "null";
BA_ "GenSigTimeoutTime_ALL" SG_ 280 CVC_HV_State 200;
BA_ "InvalidValue" SG_ 293 ABS_Status_AliveCounter "Fh";
BA_ "InvalidValue" SG_ 294 Checksum_0x126 "null";
BA_ "GenSigTimeoutTime_ALL" SG_ 294 Checksum_0x126 200;
BA_ "InvalidValue" SG_ 294 Rolling_Counter_0x126 "Fh";
BA_ "GenSigTimeoutTime_ALL" SG_ 294 Rolling_Counter_0x126 200;
BA_ "InvalidValue" SG_ 294 BMS_AllowChgCurr "FFFFh";
BA_ "GenSigTimeoutTime_ALL" SG_ 294 BMS_AllowChgCurr 200;
BA_ "InvalidValue" SG_ 294 BMS_AllowChgCurrPeak "FFFFh";
BA_ "GenSigTimeoutTime_ALL" SG_ 294 BMS_AllowChgCurrPeak 200;
BA_ "InvalidValue" SG_ 296 Checksum_0x128 "null";
BA_ "GenSigTimeoutTime_ALL" SG_ 296 Checksum_0x128 200;
BA_ "InvalidValue" SG_ 296 Rolling_Counter_0x128 "Fh";
BA_ "GenSigTimeoutTime_ALL" SG_ 296 Rolling_Counter_0x128 200;
BA_ "InvalidValue" SG_ 296 BMS_AllowDischgCurr "FFFFh";
BA_ "GenSigTimeoutTime_ALL" SG_ 296 BMS_AllowDischgCurr 200;
BA_ "InvalidValue" SG_ 296 BMS_AllowDischgCurrPeak "FFFFh";
BA_ "GenSigTimeoutTime_ALL" SG_ 296 BMS_AllowDischgCurrPeak 200;
BA_ "InvalidValue" SG_ 306 RollingCounter_0x132 "Fh";
BA_ "GenSigStartValue" SG_ 306 ESC_MasterCylinderPressure 1000;
BA_ "GenSigTimeoutTime_ALL" SG_ 306 ESC_VehicleStandstill 200;
BA_ "InvalidValue" SG_ 354 CVC_Ctrl_AliveCounter "Fh";
BA_ "InvalidValue" SG_ 358 CVC_Status_AliveCounter "Fh";
BA_ "GenSigStartValue" SG_ 358 CVC_CruiseSetSpd 30;
BA_ "GenSigSendType" SG_ 1235 CHSKM_CVC_Debug 3;
BA_ "GenSigTimeoutTime_ALL" SG_ 1235 CHSKM_CVC_Debug 5000;
BA_ "GenSigSendType" SG_ 1235 ALV_CVC_Debug 3;
BA_ "GenSigTimeoutTime_ALL" SG_ 1235 ALV_CVC_Debug 5000;
BA_ "InvalidValue" SG_ 1235 ALV_CVC_Debug "Fh";
BA_ "GenSigSendType" SG_ 1235 CVC_GearPOnlyAtStationaryAlert 4;
BA_ "GenSigTimeoutTime_ALL" SG_ 1235 CVC_GearPOnlyAtStationaryAlert 5000;
BA_ "GenSigSendType" SG_ 1235 CVC_GearP_NotPossibleAlert 4;
BA_ "GenSigTimeoutTime_ALL" SG_ 1235 CVC_GearP_NotPossibleAlert 5000;
BA_ "GenSigSendType" SG_ 1235 CVC_PressBrakeToEngageGear 4;
BA_ "GenSigTimeoutTime_ALL" SG_ 1235 CVC_PressBrakeToEngageGear 5000;
BA_ "GenSigSendType" SG_ 1235 CVC_CantChangeGear 4;
BA_ "GenSigTimeoutTime_ALL" SG_ 1235 CVC_CantChangeGear 5000;
BA_ "GenSigSendType" SG_ 1235 CVC_GearMalfunction 4;
BA_ "GenSigTimeoutTime_ALL" SG_ 1235 CVC_GearMalfunction 5000;
BA_ "GenSigSendType" SG_ 1235 CVC_RangeAlert 4;
BA_ "GenSigTimeoutTime_ALL" SG_ 1235 CVC_RangeAlert 5000;
BA_ "GenSigSendType" SG_ 1235 CVC_HVSystemReduced 4;
BA_ "GenSigTimeoutTime_ALL" SG_ 1235 CVC_HVSystemReduced 5000;
BA_ "GenSigSendType" SG_ 1235 CVC_FrontEDSReduced 4;
BA_ "GenSigTimeoutTime_ALL" SG_ 1235 CVC_FrontEDSReduced 5000;
BA_ "GenSigSendType" SG_ 1235 CVC_FrontEDS_Malfunc 4;
BA_ "GenSigTimeoutTime_ALL" SG_ 1235 CVC_FrontEDS_Malfunc 5000;
BA_ "GenSigSendType" SG_ 1235 CVC_RearEDSReduced 4;
BA_ "GenSigTimeoutTime_ALL" SG_ 1235 CVC_RearEDSReduced 5000;
BA_ "GenSigSendType" SG_ 1235 CVC_RearEDS_Malfunc 4;
BA_ "GenSigTimeoutTime_ALL" SG_ 1235 CVC_RearEDS_Malfunc 5000;
BA_ "GenSigSendType" SG_ 1235 CVC_CoolingSystem_Malfunc 4;
BA_ "GenSigTimeoutTime_ALL" SG_ 1235 CVC_CoolingSystem_Malfunc 5000;
BA_ "GenSigSendType" SG_ 1235 CVC_NeutralRequest 4;
BA_ "GenSigTimeoutTime_ALL" SG_ 1235 CVC_NeutralRequest 5000;
BA_ "GenSigSendType" SG_ 1235 CVC_SoftShutdown 4;
BA_ "GenSigTimeoutTime_ALL" SG_ 1235 CVC_SoftShutdown 5000;
BA_ "GenSigSendType" SG_ 1235 CVC_EmergencyShutdown 4;
BA_ "GenSigTimeoutTime_ALL" SG_ 1235 CVC_EmergencyShutdown 5000;
BA_ "GenSigSendType" SG_ 1235 CVC_ChgPortDoorSys_Malfunc 4;
BA_ "GenSigTimeoutTime_ALL" SG_ 1235 CVC_ChgPortDoorSys_Malfunc 5000;
BA_ "GenSigSendType" SG_ 1235 CVC_Gearchange_NotPossible 4;
BA_ "GenSigTimeoutTime_ALL" SG_ 1235 CVC_Gearchange_NotPossible 5000;
BA_ "GenSigSendType" SG_ 1235 CVC_12v_Warning 4;
BA_ "GenSigTimeoutTime_ALL" SG_ 1235 CVC_12v_Warning 5000;
BA_ "GenSigSendType" SG_ 1235 CVC_WflagRes19 4;
BA_ "GenSigTimeoutTime_ALL" SG_ 1235 CVC_WflagRes19 5000;
BA_ "GenSigSendType" SG_ 1235 CVC_WflagRes20 4;
BA_ "GenSigTimeoutTime_ALL" SG_ 1235 CVC_WflagRes20 5000;
BA_ "GenSigSendType" SG_ 1235 CVC_WflagRes21 4;
BA_ "GenSigTimeoutTime_ALL" SG_ 1235 CVC_WflagRes21 5000;
BA_ "GenSigSendType" SG_ 1235 CVC_WflagRes22 4;
BA_ "GenSigTimeoutTime_ALL" SG_ 1235 CVC_WflagRes22 5000;
BA_ "GenSigSendType" SG_ 1235 CVC_WflagRes23 4;
BA_ "GenSigTimeoutTime_ALL" SG_ 1235 CVC_WflagRes23 5000;
BA_ "GenSigSendType" SG_ 1235 CVC_WflagRes24 4;
BA_ "GenSigTimeoutTime_ALL" SG_ 1235 CVC_WflagRes24 5000;
BA_ "GenSigSendType" SG_ 1235 CVC_WflagRes25 4;
BA_ "GenSigTimeoutTime_ALL" SG_ 1235 CVC_WflagRes25 5000;
BA_ "GenSigSendType" SG_ 1235 CVC_WflagRes26 4;
BA_ "GenSigTimeoutTime_ALL" SG_ 1235 CVC_WflagRes26 5000;
BA_ "GenSigSendType" SG_ 1235 CVC_WflagRes27 4;
BA_ "GenSigTimeoutTime_ALL" SG_ 1235 CVC_WflagRes27 5000;
BA_ "GenSigSendType" SG_ 1235 CVC_SuperFastCharge_longer 4;
BA_ "GenSigTimeoutTime_ALL" SG_ 1235 CVC_SuperFastCharge_longer 5000;
BA_ "GenSigSendType" SG_ 1235 CVC_InvalidLimitSpeed 4;
BA_ "GenSigTimeoutTime_ALL" SG_ 1235 CVC_InvalidLimitSpeed 5000;
BA_ "GenSigSendType" SG_ 1235 CVC_InvalidCruiseSpeed 4;
BA_ "GenSigTimeoutTime_ALL" SG_ 1235 CVC_InvalidCruiseSpeed 5000;
BA_ "GenSigSendType" SG_ 1235 CVC_Reserved_signal2 4;
BA_ "GenSigTimeoutTime_ALL" SG_ 1235 CVC_Reserved_signal2 5000;
BA_ "GenSigSendType" SG_ 1235 CVC_Reserved_signal3 4;
BA_ "GenSigTimeoutTime_ALL" SG_ 1235 CVC_Reserved_signal3 5000;
BA_ "GenSigTimeoutTime_ALL" SG_ 1873 CVC_DebugDiag2 500;
BA_ "InvalidValue" SG_ 1873 CVC_DebugDiag2 "null";
BA_ "GenSigTimeoutTime_ALL" SG_ 1873 CVC_DebugDiag1 500;
BA_ "InvalidValue" SG_ 1873 CVC_DebugDiag1 "null";
BA_ "GenSigTimeoutTime_ALL" SG_ 1873 CVC_DebugDiag5 500;
BA_ "InvalidValue" SG_ 1873 CVC_DebugDiag5 "null";
BA_ "GenSigTimeoutTime_ALL" SG_ 1873 CVC_DebugDiag4 500;
BA_ "InvalidValue" SG_ 1873 CVC_DebugDiag4 "null";
BA_ "GenSigTimeoutTime_ALL" SG_ 1873 CVC_DebugDiag3 500;
BA_ "InvalidValue" SG_ 1873 CVC_DebugDiag3 "null";
BA_ "GenSigTimeoutTime_ALL" SG_ 1873 CVC_DebugDiag8 500;
BA_ "InvalidValue" SG_ 1873 CVC_DebugDiag8 "null";
BA_ "GenSigTimeoutTime_ALL" SG_ 1873 CVC_DebugDiag7 500;
BA_ "InvalidValue" SG_ 1873 CVC_DebugDiag7 "null";
BA_ "GenSigTimeoutTime_ALL" SG_ 1873 CVC_DebugDiag6 500;
BA_ "InvalidValue" SG_ 1873 CVC_DebugDiag6 "null";
BA_ "GenSigTimeoutTime_ALL" SG_ 1873 CVC_DebugDiag10 500;
BA_ "InvalidValue" SG_ 1873 CVC_DebugDiag10 "null";
BA_ "GenSigTimeoutTime_ALL" SG_ 1873 CVC_DebugDiag9 500;
BA_ "InvalidValue" SG_ 1873 CVC_DebugDiag9 "null";
BA_ "GenSigTimeoutTime_ALL" SG_ 1873 CVC_DebugDiag13 500;
BA_ "InvalidValue" SG_ 1873 CVC_DebugDiag13 "null";
BA_ "GenSigTimeoutTime_ALL" SG_ 1873 CVC_DebugDiag12 500;
BA_ "InvalidValue" SG_ 1873 CVC_DebugDiag12 "null";
BA_ "GenSigTimeoutTime_ALL" SG_ 1873 CVC_DebugDiag11 500;
BA_ "InvalidValue" SG_ 1873 CVC_DebugDiag11 "null";
BA_ "GenSigTimeoutTime_ALL" SG_ 1873 CVC_DebugDiag16 500;
BA_ "InvalidValue" SG_ 1873 CVC_DebugDiag16 "null";
BA_ "GenSigTimeoutTime_ALL" SG_ 1873 CVC_DebugDiag15 500;
BA_ "InvalidValue" SG_ 1873 CVC_DebugDiag15 "null";
BA_ "GenSigTimeoutTime_ALL" SG_ 1873 CVC_DebugDiag14 500;
BA_ "InvalidValue" SG_ 1873 CVC_DebugDiag14 "null";
BA_ "GenSigTimeoutTime_ALL" SG_ 1873 CVC_DebugDiag18 500;
BA_ "InvalidValue" SG_ 1873 CVC_DebugDiag18 "null";
BA_ "GenSigTimeoutTime_ALL" SG_ 1873 CVC_DebugDiag17 500;
BA_ "InvalidValue" SG_ 1873 CVC_DebugDiag17 "null";
BA_ "GenSigTimeoutTime_ALL" SG_ 1873 CVC_DebugDiag20 500;
BA_ "InvalidValue" SG_ 1873 CVC_DebugDiag20 "null";
BA_ "GenSigTimeoutTime_ALL" SG_ 1873 CVC_DebugDiag19 500;
BA_ "InvalidValue" SG_ 1873 CVC_DebugDiag19 "null";
BA_ "InvalidValue" SG_ 359 CVC_StsEpt_AliveCounter "Fh";
BA_ "GenSigStartValue" SG_ 368 FMCU_MaxSpeedAllow 34000;
BA_ "GenSigStartValue" SG_ 368 FMCU_InletTemp 50;
BA_ "InvalidValue" SG_ 368 FMCU_InletTemp "FFh";
BA_ "GenSigTimeoutTime_ALL" SG_ 372 CHSKM_BMS_CurMeas 100;
BA_ "InvalidValue" SG_ 372 ALV_BMS_CurMeas "Fh";
BA_ "GenSigTimeoutTime_ALL" SG_ 372 ALV_BMS_CurMeas 100;
BA_ "InvalidValue" SG_ 372 BMS_StartOfMeasument_STS "null";
BA_ "GenSigTimeoutTime_ALL" SG_ 372 BMS_StartOfMeasument_STS 100;
BA_ "InvalidValue" SG_ 372 BMS_PackCur_MEAS "FFFFh";
BA_ "GenSigTimeoutTime_ALL" SG_ 372 BMS_PackCur_MEAS 100;
BA_ "GenSigStartValue" SG_ 372 BMS_PackCur_MEAS 32768;
BA_ "GenSigTimeoutTime_ALL" SG_ 374 Checksum_0x176 200;
BA_ "InvalidValue" SG_ 374 Rolling_Counter_0x176 "Fh";
BA_ "GenSigTimeoutTime_ALL" SG_ 374 Rolling_Counter_0x176 200;
BA_ "InvalidValue" SG_ 374 BMS_HVPackVol_MEAS "FFFFh";
BA_ "GenSigTimeoutTime_ALL" SG_ 374 BMS_HVPackVol_MEAS 200;
BA_ "InvalidValue" SG_ 374 BMS_HVLinkVol_MEAS "FFFFh";
BA_ "GenSigTimeoutTime_ALL" SG_ 374 BMS_HVLinkVol_MEAS 200;
BA_ "InvalidValue" SG_ 375 Checksum_0x177 "null";
BA_ "GenSigTimeoutTime_ALL" SG_ 375 Checksum_0x177 200;
BA_ "InvalidValue" SG_ 375 Rolling_Counter_0x177 "Fh";
BA_ "GenSigTimeoutTime_ALL" SG_ 375 Rolling_Counter_0x177 200;
BA_ "InvalidValue" SG_ 375 BMS_HVBusVol_MEAS "FFFFh";
BA_ "GenSigTimeoutTime_ALL" SG_ 375 BMS_HVBusVol_MEAS 200;
BA_ "InvalidValue" SG_ 375 BMS_HVFuseVol_MEAS "FFFFh";
BA_ "GenSigTimeoutTime_ALL" SG_ 375 BMS_HVFuseVol_MEAS 200;
BA_ "InvalidValue" SG_ 482 PEPS_Message_Sts_AliveCounter "Fh";
BA_ "InvalidValue" SG_ 482 PEPS_CL30sRelaySts "3h";
BA_ "InvalidValue" SG_ 517 Checksum_0x205 "null";
BA_ "GenSigTimeoutTime_ALL" SG_ 517 Checksum_0x205 200;
BA_ "InvalidValue" SG_ 517 Rolling_Counter_0x205 "Fh";
BA_ "GenSigTimeoutTime_ALL" SG_ 517 Rolling_Counter_0x205 200;
BA_ "InvalidValue" SG_ 517 BMS_CellNumMinCellVol "null";
BA_ "GenSigTimeoutTime_ALL" SG_ 517 BMS_CellNumMinCellVol 200;
BA_ "InvalidValue" SG_ 517 BMS_CellNumMaxCellVol "null";
BA_ "GenSigTimeoutTime_ALL" SG_ 517 BMS_CellNumMaxCellVol 200;
BA_ "InvalidValue" SG_ 517 BMS_MinCellVol "1FFFh";
BA_ "GenSigTimeoutTime_ALL" SG_ 517 BMS_MinCellVol 200;
BA_ "InvalidValue" SG_ 517 BMS_MaxCellVol "1FFFh";
BA_ "GenSigTimeoutTime_ALL" SG_ 517 BMS_MaxCellVol 200;
BA_ "InvalidValue" SG_ 518 Checksum_0x206 "null";
BA_ "GenSigTimeoutTime_ALL" SG_ 518 Checksum_0x206 200;
BA_ "InvalidValue" SG_ 518 Rolling_Counter_0x206 "Fh";
BA_ "GenSigTimeoutTime_ALL" SG_ 518 Rolling_Counter_0x206 200;
BA_ "InvalidValue" SG_ 518 BMS_MaxMinDiffCellVol "1FFFh";
BA_ "GenSigTimeoutTime_ALL" SG_ 518 BMS_MaxMinDiffCellVol 200;
BA_ "InvalidValue" SG_ 521 Checksum_0x209 "null";
BA_ "GenSigTimeoutTime_ALL" SG_ 521 Checksum_0x209 200;
BA_ "InvalidValue" SG_ 521 Rolling_Counter_0x209 "Fh";
BA_ "GenSigTimeoutTime_ALL" SG_ 521 Rolling_Counter_0x209 200;
BA_ "InvalidValue" SG_ 521 BMS_MaxDischgPwr_ALW "FFFh";
BA_ "GenSigTimeoutTime_ALL" SG_ 521 BMS_MaxDischgPwr_ALW 200;
BA_ "InvalidValue" SG_ 521 BMS_MaxChgPwr_ALW "FFFh";
BA_ "GenSigTimeoutTime_ALL" SG_ 521 BMS_MaxChgPwr_ALW 200;
BA_ "InvalidValue" SG_ 521 BMS_MaxDischgPwr_Peak "FFFh";
BA_ "GenSigTimeoutTime_ALL" SG_ 521 BMS_MaxDischgPwr_Peak 200;
BA_ "InvalidValue" SG_ 521 BMS_MaxChgPwr_Peak "FFFh";
BA_ "GenSigTimeoutTime_ALL" SG_ 521 BMS_MaxChgPwr_Peak 200;
BA_ "GenSigTimeoutTime_ALL" SG_ 532 Checksum_0x214 500;
BA_ "InvalidValue" SG_ 532 Rolling_Counter_0x214 "Fh";
BA_ "GenSigTimeoutTime_ALL" SG_ 532 Rolling_Counter_0x214 500;
BA_ "InvalidValue" SG_ 532 BMS_Display_SOC "3FFh";
BA_ "GenSigTimeoutTime_ALL" SG_ 532 BMS_Display_SOC 500;
BA_ "GenSigTimeoutTime_ALL" SG_ 532 BMS_SOCE 500;
BA_ "InvalidValue" SG_ 532 BMS_SOCE "3FFFh";
BA_ "GenSigTimeoutTime_ALL" SG_ 533 Checksum_0x215 500;
BA_ "InvalidValue" SG_ 533 Rolling_Counter_0x215 "Fh";
BA_ "GenSigTimeoutTime_ALL" SG_ 533 Rolling_Counter_0x215 500;
BA_ "GenSigTimeoutTime_ALL" SG_ 533 BMS_BatBalance_ERR 500;
BA_ "GenSigTimeoutTime_ALL" SG_ 533 BMS_Balance_STS 500;
BA_ "GenSigTimeoutTime_ALL" SG_ 533 BMS_IGN_Sts 500;
BA_ "GenSigTimeoutTime_ALL" SG_ 533 BMS_HWCrash_Sts 500;
BA_ "InvalidValue" SG_ 533 BMS_HVIL_STS "3h";
BA_ "GenSigTimeoutTime_ALL" SG_ 533 BMS_HVIL_STS 500;
BA_ "GenSigTimeoutTime_ALL" SG_ 533 BMS_HVOnOff_STS 500;
BA_ "GenSigTimeoutTime_ALL" SG_ 533 BMS_ERR_LEV 500;
BA_ "InvalidValue" SG_ 533 BMS_SocActual_EST "3FFh";
BA_ "GenSigTimeoutTime_ALL" SG_ 533 BMS_SocActual_EST 500;
BA_ "InvalidValue" SG_ 533 BMS_Sys_STS "8h";
BA_ "GenSigTimeoutTime_ALL" SG_ 533 BMS_Sys_STS 500;
BA_ "GenSigTimeoutTime_ALL" SG_ 533 BMS_ISU_Status 500;
BA_ "InvalidValue" SG_ 533 BMS_SOH "FFh";
BA_ "GenSigTimeoutTime_ALL" SG_ 533 BMS_SOH 500;
BA_ "GenSigStartValue" SG_ 533 BMS_SOH 54;
BA_ "InvalidValue" SG_ 533 BMS_SOE "FFh";
BA_ "GenSigTimeoutTime_ALL" SG_ 533 BMS_SOE 500;
BA_ "GenSigStartValue" SG_ 533 BMS_SOE 54;
BA_ "GenSigTimeoutTime_ALL" SG_ 533 BMS_HV_Sts 500;
BA_ "InvalidValue" SG_ 534 Checksum_0x216 "null";
BA_ "GenSigTimeoutTime_ALL" SG_ 534 Checksum_0x216 500;
BA_ "InvalidValue" SG_ 534 Rolling_Counter_0x216 "Fh";
BA_ "GenSigTimeoutTime_ALL" SG_ 534 Rolling_Counter_0x216 500;
BA_ "InvalidValue" SG_ 534 BMS_RemainChargeTime "3FFFh";
BA_ "GenSigTimeoutTime_ALL" SG_ 534 BMS_RemainChargeTime 500;
BA_ "InvalidValue" SG_ 534 BMS_ChgVoltage_REQ "3FFFh";
BA_ "GenSigTimeoutTime_ALL" SG_ 534 BMS_ChgVoltage_REQ 500;
BA_ "InvalidValue" SG_ 534 BMS_ChgCurrent_REQ "FFFh";
BA_ "GenSigTimeoutTime_ALL" SG_ 534 BMS_ChgCurrent_REQ 500;
BA_ "GenSigTimeoutTime_ALL" SG_ 544 CHSKM_CVC_BMS_Thermal_FB 500;
BA_ "InvalidValue" SG_ 544 CHSKM_CVC_BMS_Thermal_FB "null";
BA_ "GenSigTimeoutTime_ALL" SG_ 544 ALIV_CVC_BMS_Thermal_FB 500;
BA_ "InvalidValue" SG_ 544 ALIV_CVC_BMS_Thermal_FB "Fh";
BA_ "GenSigTimeoutTime_ALL" SG_ 544 CVC_BMS_PTCOnOff_Sts 500;
BA_ "InvalidValue" SG_ 544 CVC_BMS_PTCOnOff_Sts "null";
BA_ "GenSigTimeoutTime_ALL" SG_ 544 CVC_BMS_PumpFB 500;
BA_ "InvalidValue" SG_ 544 CVC_BMS_PumpFB "null";
BA_ "InvalidValue" SG_ 549 Checksum_0x225 "null";
BA_ "GenSigTimeoutTime_ALL" SG_ 549 Checksum_0x225 200;
BA_ "InvalidValue" SG_ 549 Rolling_Counter_0x225 "Fh";
BA_ "GenSigTimeoutTime_ALL" SG_ 549 Rolling_Counter_0x225 200;
BA_ "InvalidValue" SG_ 549 CDM_bAcvCanComStblMon "null";
BA_ "GenSigTimeoutTime_ALL" SG_ 549 CDM_bAcvCanComStblMon 200;
BA_ "InvalidValue" SG_ 549 FRMo_bErrHvbatStReqExtMon "null";
BA_ "GenSigTimeoutTime_ALL" SG_ 549 FRMo_bErrHvbatStReqExtMon 200;
BA_ "InvalidValue" SG_ 549 FRMo_bErrChrgnAllwdExtMon "null";
BA_ "GenSigTimeoutTime_ALL" SG_ 549 FRMo_bErrChrgnAllwdExtMon 200;
BA_ "InvalidValue" SG_ 549 FRMo_bErrVehCrashStExtMon "null";
BA_ "GenSigTimeoutTime_ALL" SG_ 549 FRMo_bErrVehCrashStExtMon 200;
BA_ "InvalidValue" SG_ 549 CDM_bErrComctnLossCanMon "null";
BA_ "GenSigTimeoutTime_ALL" SG_ 549 CDM_bErrComctnLossCanMon 200;
BA_ "InvalidValue" SG_ 549 CTCMon_bErrCtctrSopcMon "null";
BA_ "GenSigTimeoutTime_ALL" SG_ 549 CTCMon_bErrCtctrSopcMon 200;
BA_ "InvalidValue" SG_ 549 CTCMon_bInvldCtctrHisdIFbMon "null";
BA_ "GenSigTimeoutTime_ALL" SG_ 549 CTCMon_bInvldCtctrHisdIFbMon 200;
BA_ "InvalidValue" SG_ 549 CTCMon_bInvldCtctrLosdUFbMon "null";
BA_ "GenSigTimeoutTime_ALL" SG_ 549 CTCMon_bInvldCtctrLosdUFbMon 200;
BA_ "InvalidValue" SG_ 549 CTM_bErrCellTDifMaxMon "null";
BA_ "GenSigTimeoutTime_ALL" SG_ 549 CTM_bErrCellTDifMaxMon 200;
BA_ "InvalidValue" SG_ 549 CTM_bErrCellTMaxMon "null";
BA_ "GenSigTimeoutTime_ALL" SG_ 549 CTM_bErrCellTMaxMon 200;
BA_ "InvalidValue" SG_ 549 CTM_bErrCellTMinMon "null";
BA_ "GenSigTimeoutTime_ALL" SG_ 549 CTM_bErrCellTMinMon 200;
BA_ "InvalidValue" SG_ 549 CTM_bErrThrwyPredMon "null";
BA_ "GenSigTimeoutTime_ALL" SG_ 549 CTM_bErrThrwyPredMon 200;
BA_ "InvalidValue" SG_ 549 CUM_bErrCellUDifMaxMon "null";
BA_ "GenSigTimeoutTime_ALL" SG_ 549 CUM_bErrCellUDifMaxMon 200;
BA_ "InvalidValue" SG_ 549 CUM_bErrCellUMaxMon "null";
BA_ "GenSigTimeoutTime_ALL" SG_ 549 CUM_bErrCellUMaxMon 200;
BA_ "InvalidValue" SG_ 549 CUM_bErrCellUMinMon "null";
BA_ "GenSigTimeoutTime_ALL" SG_ 549 CUM_bErrCellUMinMon 200;
BA_ "InvalidValue" SG_ 549 CUM_bErrCellUProtnMaxNvMon "null";
BA_ "GenSigTimeoutTime_ALL" SG_ 549 CUM_bErrCellUProtnMaxNvMon 200;
BA_ "InvalidValue" SG_ 549 CUM_bErrCellUProtnMinNvMon "null";
BA_ "GenSigTimeoutTime_ALL" SG_ 549 CUM_bErrCellUProtnMinNvMon 200;
BA_ "InvalidValue" SG_ 549 CUM_bErrPackUImplyMon "null";
BA_ "GenSigTimeoutTime_ALL" SG_ 549 CUM_bErrPackUImplyMon 200;
BA_ "InvalidValue" SG_ 549 EHPMon_bRdyHvilMon "null";
BA_ "GenSigTimeoutTime_ALL" SG_ 549 EHPMon_bRdyHvilMon 200;
BA_ "InvalidValue" SG_ 549 EHPMon_bErrWlddNegNvMon "null";
BA_ "GenSigTimeoutTime_ALL" SG_ 549 EHPMon_bErrWlddNegNvMon 200;
BA_ "InvalidValue" SG_ 549 EHPMon_bErrWlddPosNvMon "null";
BA_ "GenSigTimeoutTime_ALL" SG_ 549 EHPMon_bErrWlddPosNvMon 200;
BA_ "InvalidValue" SG_ 549 EHPMon_bErrWlddPrechNvMon "null";
BA_ "GenSigTimeoutTime_ALL" SG_ 549 EHPMon_bErrWlddPrechNvMon 200;
BA_ "InvalidValue" SG_ 549 EHPMon_bErrHvilMon "null";
BA_ "GenSigTimeoutTime_ALL" SG_ 549 EHPMon_bErrHvilMon 200;
BA_ "InvalidValue" SG_ 549 EHPMon_bErrHvilShoMon "null";
BA_ "GenSigTimeoutTime_ALL" SG_ 549 EHPMon_bErrHvilShoMon 200;
BA_ "InvalidValue" SG_ 549 EHPMon_bErrPackIslnRNvMon "null";
BA_ "GenSigTimeoutTime_ALL" SG_ 549 EHPMon_bErrPackIslnRNvMon 200;
BA_ "InvalidValue" SG_ 549 EHPMon_bErrVehCrashNvMon "null";
BA_ "GenSigTimeoutTime_ALL" SG_ 549 EHPMon_bErrVehCrashNvMon 200;
BA_ "InvalidValue" SG_ 549 EHPMon_bErrVehIslnRNvMon "null";
BA_ "GenSigTimeoutTime_ALL" SG_ 549 EHPMon_bErrVehIslnRNvMon 200;
BA_ "InvalidValue" SG_ 549 FRMo_bErrMemStorgNvMon "null";
BA_ "GenSigTimeoutTime_ALL" SG_ 549 FRMo_bErrMemStorgNvMon 200;
BA_ "InvalidValue" SG_ 549 L1IM_bErrClmp30MaxMonInp "null";
BA_ "GenSigTimeoutTime_ALL" SG_ 549 L1IM_bErrClmp30MaxMonInp 200;
BA_ "InvalidValue" SG_ 549 L1IM_bErrClmp30MinMonInp "null";
BA_ "GenSigTimeoutTime_ALL" SG_ 549 L1IM_bErrClmp30MinMonInp 200;
BA_ "InvalidValue" SG_ 549 L1IM_bErrCtctrDtrtMonInp "null";
BA_ "GenSigTimeoutTime_ALL" SG_ 549 L1IM_bErrCtctrDtrtMonInp 200;
BA_ "InvalidValue" SG_ 549 L1IM_bErrUActImplyMonInp "null";
BA_ "GenSigTimeoutTime_ALL" SG_ 549 L1IM_bErrUActImplyMonInp 200;
BA_ "InvalidValue" SG_ 549 MCCM_bAcvMdulCtlrStsMon "null";
BA_ "GenSigTimeoutTime_ALL" SG_ 549 MCCM_bAcvMdulCtlrStsMon 200;
BA_ "InvalidValue" SG_ 549 MCCM_bErrLntecSngFltMon "null";
BA_ "GenSigTimeoutTime_ALL" SG_ 549 MCCM_bErrLntecSngFltMon 200;
BA_ "InvalidValue" SG_ 549 MCCM_bErrLntecLtntFltMon "null";
BA_ "GenSigTimeoutTime_ALL" SG_ 549 MCCM_bErrLntecLtntFltMon 200;
BA_ "InvalidValue" SG_ 549 MCCM_bErrMdulCellSnsrCfgMon "null";
BA_ "GenSigTimeoutTime_ALL" SG_ 549 MCCM_bErrMdulCellSnsrCfgMon 200;
BA_ "InvalidValue" SG_ 549 MCCM_bErrMdulCtlrComMon "null";
BA_ "GenSigTimeoutTime_ALL" SG_ 549 MCCM_bErrMdulCtlrComMon 200;
BA_ "InvalidValue" SG_ 549 MCCM_bErrSnsrTEltlMon "null";
BA_ "GenSigTimeoutTime_ALL" SG_ 549 MCCM_bErrSnsrTEltlMon 200;
BA_ "InvalidValue" SG_ 549 MCCM_bWarnSnsrTEltlMon "null";
BA_ "GenSigTimeoutTime_ALL" SG_ 549 MCCM_bWarnSnsrTEltlMon 200;
BA_ "InvalidValue" SG_ 549 PCM_bRdySnsrIMon "null";
BA_ "GenSigTimeoutTime_ALL" SG_ 549 PCM_bRdySnsrIMon 200;
BA_ "InvalidValue" SG_ 549 PCM_bErrPackEFlowMaxLimMon "null";
BA_ "GenSigTimeoutTime_ALL" SG_ 549 PCM_bErrPackEFlowMaxLimMon 200;
BA_ "InvalidValue" SG_ 549 PCM_bErrPackIChDchaMaxLimMon "null";
BA_ "GenSigTimeoutTime_ALL" SG_ 549 PCM_bErrPackIChDchaMaxLimMon 200;
BA_ "InvalidValue" SG_ 549 PCM_bErrSnsrIImplyMon "null";
BA_ "GenSigTimeoutTime_ALL" SG_ 549 PCM_bErrSnsrIImplyMon 200;
BA_ "InvalidValue" SG_ 549 FRMo_bErrSnsrI1ExtMon "null";
BA_ "GenSigTimeoutTime_ALL" SG_ 549 FRMo_bErrSnsrI1ExtMon 200;
BA_ "InvalidValue" SG_ 549 PCM_bInvldSnsrI1Mon "null";
BA_ "GenSigTimeoutTime_ALL" SG_ 549 PCM_bInvldSnsrI1Mon 200;
BA_ "InvalidValue" SG_ 549 PCM_bInvldSnsrI2Mon "null";
BA_ "GenSigTimeoutTime_ALL" SG_ 549 PCM_bInvldSnsrI2Mon 200;
BA_ "InvalidValue" SG_ 549 FRMo_bErrSopcLvl3Mon "null";
BA_ "GenSigTimeoutTime_ALL" SG_ 549 FRMo_bErrSopcLvl3Mon 200;
BA_ "InvalidValue" SG_ 549 BMS_FRMo_Reserved_1 "null";
BA_ "GenSigTimeoutTime_ALL" SG_ 549 BMS_FRMo_Reserved_1 200;
BA_ "InvalidValue" SG_ 549 BMS_FRMo_Reserved_2 "null";
BA_ "GenSigTimeoutTime_ALL" SG_ 549 BMS_FRMo_Reserved_2 200;
BA_ "InvalidValue" SG_ 549 BMS_FRMo_Reserved_3 "null";
BA_ "GenSigTimeoutTime_ALL" SG_ 549 BMS_FRMo_Reserved_3 200;
BA_ "InvalidValue" SG_ 549 BMS_FRMo_Reserved_4 "null";
BA_ "GenSigTimeoutTime_ALL" SG_ 549 BMS_FRMo_Reserved_4 200;
BA_ "InvalidValue" SG_ 549 BMS_FRMo_Reserved_5 "null";
BA_ "GenSigTimeoutTime_ALL" SG_ 549 BMS_FRMo_Reserved_5 200;
BA_ "InvalidValue" SG_ 550 Checksum_0x226 "null";
BA_ "GenSigTimeoutTime_ALL" SG_ 550 Checksum_0x226 200;
BA_ "InvalidValue" SG_ 550 Rolling_Counter_0x226 "Fh";
BA_ "GenSigTimeoutTime_ALL" SG_ 550 Rolling_Counter_0x226 200;
BA_ "InvalidValue" SG_ 550 BMS_QMMo_Reserved_0 "null";
BA_ "GenSigTimeoutTime_ALL" SG_ 550 BMS_QMMo_Reserved_0 200;
BA_ "InvalidValue" SG_ 550 BMS_QMMo_Reserved_1 "null";
BA_ "GenSigTimeoutTime_ALL" SG_ 550 BMS_QMMo_Reserved_1 200;
BA_ "InvalidValue" SG_ 550 BMS_QMMo_Reserved_2 "null";
BA_ "GenSigTimeoutTime_ALL" SG_ 550 BMS_QMMo_Reserved_2 200;
BA_ "InvalidValue" SG_ 550 BMS_QMMo_Reserved_3 "null";
BA_ "GenSigTimeoutTime_ALL" SG_ 550 BMS_QMMo_Reserved_3 200;
BA_ "InvalidValue" SG_ 550 BMS_QMMo_Reserved_4 "null";
BA_ "GenSigTimeoutTime_ALL" SG_ 550 BMS_QMMo_Reserved_4 200;
BA_ "InvalidValue" SG_ 550 BMS_QMMo_Reserved_5 "null";
BA_ "GenSigTimeoutTime_ALL" SG_ 550 BMS_QMMo_Reserved_5 200;
BA_ "InvalidValue" SG_ 550 BMS_QMMo_Reserved_6 "null";
BA_ "GenSigTimeoutTime_ALL" SG_ 550 BMS_QMMo_Reserved_6 200;
BA_ "InvalidValue" SG_ 550 BMS_QMMo_Reserved_7 "null";
BA_ "GenSigTimeoutTime_ALL" SG_ 550 BMS_QMMo_Reserved_7 200;
BA_ "InvalidValue" SG_ 550 BMS_QMMo_Reserved_8 "null";
BA_ "GenSigTimeoutTime_ALL" SG_ 550 BMS_QMMo_Reserved_8 200;
BA_ "InvalidValue" SG_ 550 BMS_QMMo_Reserved_9 "null";
BA_ "GenSigTimeoutTime_ALL" SG_ 550 BMS_QMMo_Reserved_9 200;
BA_ "InvalidValue" SG_ 550 BMS_QMMo_Reserved_10 "null";
BA_ "GenSigTimeoutTime_ALL" SG_ 550 BMS_QMMo_Reserved_10 200;
BA_ "InvalidValue" SG_ 550 BMS_QMMo_Reserved_11 "null";
BA_ "GenSigTimeoutTime_ALL" SG_ 550 BMS_QMMo_Reserved_11 200;
BA_ "InvalidValue" SG_ 550 CDEM_ErrDisp_0 "null";
BA_ "GenSigTimeoutTime_ALL" SG_ 550 CDEM_ErrDisp_0 100;
BA_ "InvalidValue" SG_ 550 CDEM_ErrDisp_1 "null";
BA_ "GenSigTimeoutTime_ALL" SG_ 550 CDEM_ErrDisp_1 100;
BA_ "InvalidValue" SG_ 563 CVC_FMCU_Limit_AliveCounter "Fh";
BA_ "GenSigStartValue" SG_ 564 CVC_vDCDCRequest 224;
BA_ "GenSigTimeoutTime_ALL" SG_ 581 Checksum_0x245 200;
BA_ "InvalidValue" SG_ 581 Rolling_Counter_0x245 "Fh";
BA_ "GenSigTimeoutTime_ALL" SG_ 581 Rolling_Counter_0x245 200;
BA_ "GenSigTimeoutTime_ALL" SG_ 581 BMS_ProbeNumMaxCellTemp 200;
BA_ "GenSigStartValue" SG_ 581 BMS_ProbeNumMaxCellTemp 1;
BA_ "InvalidValue" SG_ 581 BMS_MinCellTemp "FFh";
BA_ "GenSigTimeoutTime_ALL" SG_ 581 BMS_MinCellTemp 200;
BA_ "GenSigStartValue" SG_ 581 BMS_MinCellTemp 80;
BA_ "GenSigTimeoutTime_ALL" SG_ 581 BMS_ProbeNumMinCellTemp 200;
BA_ "InvalidValue" SG_ 581 BMS_PackTemp "FFh";
BA_ "GenSigTimeoutTime_ALL" SG_ 581 BMS_PackTemp 200;
BA_ "GenSigStartValue" SG_ 581 BMS_PackTemp 80;
BA_ "InvalidValue" SG_ 581 BMS_MaxCellTemp "FFh";
BA_ "GenSigTimeoutTime_ALL" SG_ 581 BMS_MaxCellTemp 200;
BA_ "GenSigStartValue" SG_ 581 BMS_MaxCellTemp 80;
BA_ "InvalidValue" SG_ 581 BMS_MaxMinDiffCellTemp "FFh";
BA_ "GenSigTimeoutTime_ALL" SG_ 581 BMS_MaxMinDiffCellTemp 200;
BA_ "GenSigStartValue" SG_ 581 BMS_MaxMinDiffCellTemp 80;
BA_ "InvalidValue" SG_ 584 CHSKM_BMS_CVC_THMReq "null";
BA_ "GenSigTimeoutTime_ALL" SG_ 584 CHSKM_BMS_CVC_THMReq 500;
BA_ "InvalidValue" SG_ 584 ALV_BMS_CVC_THMReq "Fh";
BA_ "GenSigTimeoutTime_ALL" SG_ 584 ALV_BMS_CVC_THMReq 500;
BA_ "InvalidValue" SG_ 584 BMS_FlowRate_Req "FFh";
BA_ "GenSigTimeoutTime_ALL" SG_ 584 BMS_FlowRate_Req 500;
BA_ "InvalidValue" SG_ 584 BMS_CoolPwrDemand "FFFh";
BA_ "GenSigTimeoutTime_ALL" SG_ 584 BMS_CoolPwrDemand 500;
BA_ "InvalidValue" SG_ 584 BMS_HeatPwrDemand "FFFh";
BA_ "GenSigTimeoutTime_ALL" SG_ 584 BMS_HeatPwrDemand 500;
BA_ "InvalidValue" SG_ 584 BMS_CVC_PTCOnOff_Req "null";
BA_ "GenSigTimeoutTime_ALL" SG_ 584 BMS_CVC_PTCOnOff_Req 500;
BA_ "InvalidValue" SG_ 584 BMS_CVC_ValveOnOff_Req "null";
BA_ "GenSigTimeoutTime_ALL" SG_ 584 BMS_CVC_ValveOnOff_Req 500;
BA_ "InvalidValue" SG_ 584 BMS_PreHeatCoolReq "3h";
BA_ "GenSigTimeoutTime_ALL" SG_ 584 BMS_PreHeatCoolReq 500;
BA_ "GenSigTimeoutTime_ALL" SG_ 585 CHSKM_BMS_CoolntInletOutletTmp 500;
BA_ "InvalidValue" SG_ 585 ALV_BMS_CoolntInletOutletTmp "Fh";
BA_ "GenSigTimeoutTime_ALL" SG_ 585 ALV_BMS_CoolntInletOutletTmp 500;
BA_ "GenSigTimeoutTime_ALL" SG_ 585 BMS_CoolantInletTemp 500;
BA_ "GenSigStartValue" SG_ 585 BMS_CoolantInletTemp 80;
BA_ "GenSigTimeoutTime_ALL" SG_ 585 BMS_CoolantOutletTemp 500;
BA_ "GenSigStartValue" SG_ 585 BMS_CoolantOutletTemp 80;
BA_ "GenSigTimeoutTime_ALL" SG_ 585 BMS_BDUTemp1 500;
BA_ "GenSigStartValue" SG_ 585 BMS_BDUTemp1 80;
BA_ "GenSigTimeoutTime_ALL" SG_ 585 BMS_BDUTemp2 500;
BA_ "GenSigStartValue" SG_ 585 BMS_BDUTemp2 80;
BA_ "GenSigStartValue" SG_ 870 PDU_DCDC_Thermal_SecFetTemp 40;
BA_ "GenSigStartValue" SG_ 870 PDU_DCDC_Thermal_PriFetTemp2 40;
BA_ "GenSigStartValue" SG_ 870 PDU_DCDC_Thermal_PriFetTemp1 40;
BA_ "GenSigStartValue" SG_ 870 PDU_DCDC_Thermal_OutFetTemp 40;
BA_ "GenSigStartValue" SG_ 870 PDU_DCDC_Thermal_IntTemp 40;
BA_ "GenSigStartValue" SG_ 870 PDU_DCDC_Thermal_FlowRateReq 40;
BA_ "GenSigStartValue" SG_ 870 PDU_DCDC_Thermal_CoolPwrReq 40;
BA_ "GenSigStartValue" SG_ 870 PDU_DCDC_Thermal_CpltTemp 40;
BA_ "GenSigTimeoutTime_ALL" SG_ 526 BMS_faultnumber 5000;
BA_ "GenSigStartValue" SG_ 593 EVCC_DCChgPosTemp 40;
BA_ "GenSigStartValue" SG_ 593 EVCC_DCChgNegTemp 40;
BA_ "GenSigStartValue" SG_ 593 EVCC_ACChgL1TerminalTemp 40;
BA_ "GenSigStartValue" SG_ 593 EVCC_ACChgNTerminalTemp_Reserve 40;
BA_ "GenSigStartValue" SG_ 663 DCDC_CVC_Temp 40;
BA_ "GenSigStartValue" SG_ 670 Time_Day 1;
BA_ "GenSigStartValue" SG_ 670 Time_Month 1;
BA_ "InvalidValue" SG_ 694 OBC_Status_AliveCounter "Fh";
BA_ "GenSigStartValue" SG_ 746 CVC_DCChgPosTemp 40;
BA_ "GenSigStartValue" SG_ 746 CVC_DCChgNegTemp 40;
BA_ "GenSigStartValue" SG_ 746 CVC_ACChgLTerminalTemp 40;
BA_ "GenSigStartValue" SG_ 746 CVC_ACChgNTerminalTemp_Reserve 40;
BA_ "InvalidValue" SG_ 773 CHSKM_BMS_Insulation "null";
BA_ "GenSigTimeoutTime_ALL" SG_ 773 CHSKM_BMS_Insulation 500;
BA_ "InvalidValue" SG_ 773 ALV_BMS_Insulation "Fh";
BA_ "GenSigTimeoutTime_ALL" SG_ 773 ALV_BMS_Insulation 500;
BA_ "InvalidValue" SG_ 773 BMS_CVC_Insulation_Mon_Sts "null";
BA_ "GenSigTimeoutTime_ALL" SG_ 773 BMS_CVC_Insulation_Mon_Sts 500;
BA_ "InvalidValue" SG_ 773 BMS_PackInsuRes "null";
BA_ "GenSigTimeoutTime_ALL" SG_ 773 BMS_PackInsuRes 500;
BA_ "GenSigStartValue" SG_ 773 BMS_PackInsuRes 5535;
BA_ "GenSigTimeoutTime_ALL" SG_ 775 Checksum_0x307 1000;
BA_ "GenSigTimeoutTime_ALL" SG_ 775 Rolling_Counter_0x307 1000;
BA_ "InvalidValue" SG_ 775 Rolling_Counter_0x307 "Fh";
BA_ "GenSigTimeoutTime_ALL" SG_ 775 BMS_Start_Stop_DM13 1000;
BA_ "GenSigStartValue" SG_ 807 IVI_SetBlowMode 2;
BA_ "GenSigStartValue" SG_ 807 IVI_SetDriverTemp 30;
BA_ "InvalidValue" SG_ 807 IVI_SetDriverTemp "3Fh";
BA_ "GenSigStartValue" SG_ 811 CCU_BlowerRelaySts 1;
BA_ "GenSigStartValue" SG_ 811 CCU_RearBlowerRelaySts 1;
BA_ "InvalidValue" SG_ 811 CCU_CirculationmotorPos "7Fh";
BA_ "InvalidValue" SG_ 811 CCU_BlowerPWM "7Fh";
BA_ "GenSigStartValue" SG_ 811 CCU_ExternalTemperature 80;
BA_ "InvalidValue" SG_ 811 CCU_PTC_Relay_Status "3h";
BA_ "InvalidValue" SG_ 815 CVC_RearBlowerRelay_Req "3h";
BA_ "InvalidValue" SG_ 815 CVC_BlowerRelay_Req "3h";
BA_ "InvalidValue" SG_ 815 CVC_FrontBlower_PWM_Req "7Fh";
BA_ "InvalidValue" SG_ 815 CVC_RearBlower_PWM_Req "7Fh";
BA_ "InvalidValue" SG_ 815 CVC_PTC_Relay_Request "3h";
BA_ "InvalidValue" SG_ 815 CVC_BlowMode_Pos_Req "7Fh";
BA_ "InvalidValue" SG_ 815 CVC_Recirculation_Pos_Req "7Fh";
BA_ "InvalidValue" SG_ 815 CVC_TempFlap_Pos_Req "7Fh";
BA_ "InvalidValue" SG_ 822 CVC_FrontBlower_Level "Fh";
BA_ "InvalidValue" SG_ 822 CVC_RearBlower_Level "7h";
BA_ "InvalidValue" SG_ 822 CVC_BlowMode_Sts "7h";
BA_ "InvalidValue" SG_ 822 CVC_Recirculation_Status "3h";
BA_ "InvalidValue" SG_ 822 CVC_CabinThermalMode "7h";
BA_ "InvalidValue" SG_ 822 CVC_RearAC_Sts "3h";
BA_ "InvalidValue" SG_ 822 CVC_CoolPwrDemand "7Fh";
BA_ "InvalidValue" SG_ 822 CVC_RearCoolPwrDemand "7Fh";
BA_ "InvalidValue" SG_ 822 CVC_HeatPwrDemand "7Fh";
BA_ "InvalidValue" SG_ 822 CVC_HVAC_Managment "7h";
BA_ "InvalidValue" SG_ 812 CCU_Rear_Blower_Sts "Fh";
BA_ "InvalidValue" SG_ 812 CCU_Dr_Side_BlowerLevelSts "1Fh";
BA_ "GenSigStartValue" SG_ 812 CCU_Dr_Side_TempGearSts 30;
BA_ "GenSigStartValue" SG_ 812 CCU_VehicleInternalTemp 40;
BA_ "GenSigStartValue" SG_ 812 PTC_InletAirTemp 48;
BA_ "GenSigStartValue" SG_ 814 CCU_TempMotorPos 48;
BA_ "InvalidValue" SG_ 814 CCU_TempMotorPos "FFh";
BA_ "GenSigStartValue" SG_ 814 PTC_OutletAirTemp 48;
BA_ "GenSigStartValue" SG_ 814 CCU_EvapTemp 48;
BA_ "GenSigStartValue" SG_ 814 CCU_VentDuctAirTemp 48;
BA_ "GenSigStartValue" SG_ 814 CCU_FootDuctAirTemp 48;
BA_ "GenSigStartValue" SG_ 814 CCU_RearEvapTemp 48;
BA_ "InvalidValue" SG_ 814 CCU_RearBlowerPWM "7Fh";
BA_ "InvalidValue" SG_ 816 Checksum_0x330 "null";
BA_ "GenSigTimeoutTime_ALL" SG_ 816 Checksum_0x330 500;
BA_ "InvalidValue" SG_ 816 Rolling_Counter_0x330 "Fh";
BA_ "GenSigTimeoutTime_ALL" SG_ 816 Rolling_Counter_0x330 500;
BA_ "InvalidValue" SG_ 816 BMS_ContactorAging "FFh";
BA_ "GenSigTimeoutTime_ALL" SG_ 816 BMS_ContactorAging 500;
BA_ "GenSigStartValue" SG_ 817 CCH_Rear_Blower_Increase 1;
BA_ "GenSigStartValue" SG_ 817 CCH_Rear_Blower_Decrease 1;
BA_ "InvalidValue" SG_ 818 Checksum_0x332 "null";
BA_ "GenSigTimeoutTime_ALL" SG_ 818 Checksum_0x332 500;
BA_ "InvalidValue" SG_ 818 Rolling_Counter_0x332 "Fh";
BA_ "GenSigTimeoutTime_ALL" SG_ 818 Rolling_Counter_0x332 500;
BA_ "InvalidValue" SG_ 818 BMS_PackCNom "FFFFh";
BA_ "GenSigTimeoutTime_ALL" SG_ 818 BMS_PackCNom 500;
BA_ "InvalidValue" SG_ 818 BMS_PackTemp_0x332 "FFh";
BA_ "GenSigTimeoutTime_ALL" SG_ 818 BMS_PackTemp_0x332 500;
BA_ "GenSigStartValue" SG_ 818 BMS_PackTemp_0x332 80;
BA_ "GenSigTimeoutTime_ALL" SG_ 819 BMS_SwVers_Type 5000;
BA_ "GenSigTimeoutTime_ALL" SG_ 819 BMS_SwVersS_phase 5000;
BA_ "GenSigTimeoutTime_ALL" SG_ 819 BMS_swVers_version 5000;
VAL_ 128 ACU_In_Disposal_Mode 0 "ACM_In_Disposal_Mode" 1 "ACM_Normal_Operation" ;
VAL_ 128 ACU_Malfunction 0 "ACM_Failure" 1 "ACM_Normal_Operation" ;
VAL_ 128 ACU_DAirbagStatus 0 "not detonation" 1 "detonation" 3 "Invalid" ;
VAL_ 128 ACU_CoDAirbagStatus 0 "not detonation" 1 "detonation" 3 "Invalid" ;
VAL_ 128 ACU_LCABsts 0 "not detonation" 1 "detonation" 3 "Invalid" ;
VAL_ 128 ACU_RCABsts 0 "not detonation" 1 "detonation" 3 "Invalid" ;
VAL_ 128 ACU_LSABsts 0 "not detonation" 1 "detonation" 3 "Invalid" ;
VAL_ 128 ACU_RSABsts 0 "not detonation" 1 "detonation" 3 "Invalid" ;
VAL_ 128 ACU_CrashSts 0 "NO Crash" 1 "Crashed" 3 "Invalid" ;
VAL_ 128 ACU_Development_Calibration 0 "ACM_Dev_Calibrated" 1 "ACM_Normal_Operation" ;
VAL_ 128 ACU_AirbagWarningStatus 0 "OFF" 1 "ON" 2 "Flash_Reserved" 3 "Invalid" ;
VAL_ 128 ACU_pyro_fuse_Stat 0 "not detonation" 1 "detonation" 3 "Invalid" ;
VAL_ 128 ACU_Airbag_Disabled 0 "ACM_AirBag_Disabled" 1 "ACM_Normal_Operation" ;
VAL_ 128 ACU_In_Plant_Mode 0 "ACM_In_Plant_Mode" 1 "ACM_Normal_Operation" ;
VAL_ 128 ACU_PBA_InhibitSts 0 "OFF" 1 "ON" 3 "Invalid" ;
VAL_ 128 ACU_Pre_Drive_Check 0 "ACM_Pre_Drive_Check" 1 "ACM_Normal_Operation" ;
VAL_ 128 ACU_CrashRearOutputSts 0 "NO Crash" 1 "Crashed" 3 "Invalid" ;
VAL_ 128 ACU_CrashRightOutputSts 0 "NO Crash" 1 "Crashed" 3 "Invalid" ;
VAL_ 128 ACU_CrashLeftOutputSts 0 "NO Crash" 1 "Crashed" 3 "Invalid" ;
VAL_ 128 ACU_CrashFrontOutputSts 0 "NO Crash" 1 "Crashed" 3 "Invalid" ;
VAL_ 170 CVC_BMS_HVOnOff_REQ 0 "forbid" 1 "allow" ;
VAL_ 171 CVC_FMCU_StsModeReq 0 "Init" 1 "LvStandby（12V）" 5 "Standby" 6 "Torq" 7 "Speed" 9 "ActiveDischarge" 10 "Fault" 11 "PowerOff" 12 "AfterRun" ;
VAL_ 171 CVC_FMCU_Oil_Pump_Relay_Sts 0 "OFF" 1 "ON" ;
VAL_ 171 CVC_FMCU_TargetTqReqV 0 "Vaild" 1 "Invalid" ;
VAL_ 171 CVC_FMCU_TargetSpeedReqV 0 "Vaild" 1 "Invalid" ;
VAL_ 171 CVC_FMCU_VehicleDirect 0 "Forward" 1 "Backward" ;
VAL_ 171 CVC_MCU_AtvDischg_Req 0 "No request" 1 "Request" ;
VAL_ 171 CVC_MCU_CtrlModeReq 0 "Inactive" 1 "TqCtrl" 2 "Speed" 3 "Reserved" ;
VAL_ 201 FMCU_CVC_MCUFaultReq 0 "No Fault" 1 "Faultlevel 1(only report)" 2 "Faultlevel2(derating)" 3 "faultlevel3(shutdown)" 4 "faultlevel4(Reserve)" 5 "faultlevel5(Reserve)" ;
VAL_ 201 FMCU_StsMCUFault 0 "No Fault" 1 "Faultlevel 1(only report)" 2 "Faultlevel2(derating)" 3 "faultlevel3(shutdown)" 4 "faultlevel4(Reserve)" 5 "faultlevel5(Reserve)" ;
VAL_ 201 FMCU_MotorSpdInvalid 0 "Valid" 1 "Invalid" ;
VAL_ 201 FMCU_MotorTqInvalid 0 "Valid" 1 "Invalid" ;
VAL_ 201 FMCU_CVC_CtrlMode 0 "Inactive" 1 "Torque control mode" 2 "Speed Control mode" 3 "Limphome" 4 "crawling" ;
VAL_ 201 FMCU_CVC_StsMode 0 "Init" 1 "LvStandby(12V)" 5 "Standby" 6 "Torq" 7 "Speed" 9 "ActiveDischarge" 10 "Fault" 11 "PowerOff" 12 "AfterRun" ;
VAL_ 202 FMCU_ActInputVoltV 0 "Valid" 1 "Invalid" ;
VAL_ 202 FMCU_ActInputCurrentV 0 "Valid" 1 "Invalid" ;
VAL_ 266 LV_BatteryType 0 "Lead Acid Battery" 1 "Lithium Battery" 2 "Reversed" 3 "Invalid" ;
VAL_ 279 RemoteFunctionState 0 "Normal function" 1 "Remote function" 2 "Reserved" 3 "Signal Invalid" ;
VAL_ 279 STAT_BLS 0 "BLS not pressed" 1 "BLS pressed" 2 "Reserved" 3 "Signal invalid" ;
VAL_ 279 STAT_CL_50_L 0 "OFF" 1 "ON" 2 "Failure" 3 "Signal invalid" ;
VAL_ 279 Clamp50AdviceRemoteStart 0 "Engine Start announcement not active" 1 "Engine Start announcement active" 2 "Reserved" 3 "Invalid" ;
VAL_ 279 Clamp50AdviceESS 0 "Engine Start announcement not active" 1 "Engine Start announcement active" 2 "Reserved" 3 "Invalid" ;
VAL_ 279 STAT_CL_R_L 0 "OFF" 1 "ON" 2 "Failure" 3 "Signal invalid" ;
VAL_ 279 STAT_CL_15_1_L 0 "OFF" 1 "ON" 2 "Failure" 3 "Signal invalid" ;
VAL_ 279 STAT_CL_15_1_DME_L 0 "OFF" 1 "ON" 2 "Failure" 3 "Signal invalid" ;
VAL_ 279 FobId 0 "Key not available" 1 "FOB_1" 2 "FOB_2" 3 "Signal invalid" ;
VAL_ 279 STAT_Terminal 0 "OFF(Comfort Enable)" 1 "ACC (Park)" 2 "ON (Driver Present)" 3 "Engine start (eMotor running)" 4 "SW Update OTA" 5 "Reserved" 6 "Reserved" 7 "Signal Invalid" ;
VAL_ 279 STAT_CL30_C_BEV 0 "OFF" 1 "ON" 2 "Failure" 3 "Signal invalid" ;
VAL_ 279 BCM_Clamp_Transport 0 "Transport Disabled" 1 "Transport E-Motor Running" 2 "Transport Driver Present" 3 "Ttransport ACC" 4 "Transport OFF" 5 "Init" 6 "Reserved" 7 "Reserved" ;
VAL_ 280 CVC_VehicleSpeedValid 0 "Invalid" 1 "Vaild" ;
VAL_ 280 CVC_HV_State 0 "HIGH_VOLT_DOWN" 1 "HIGH_VOLT_UP" 2 "HIGH_VOLT_DOWNING" 3 "HIGH_VOLT_UPING" ;
VAL_ 293 ABSActive 0 "Inactive" 1 "Active" ;
VAL_ 293 ABS_EBDFailed 0 "EBD Normal" 1 "EBD Failed" ;
VAL_ 293 ABSFailed 0 "ABS Normal" 1 "ABS Failed" ;
VAL_ 293 ABS_LowBrakeFluid 0 "no failure" 1 "failure" ;
VAL_ 293 ABS_VehicleSpeedInvalid 0 "Valid" 1 "Invalid" ;
VAL_ 293 ABS_HAZActive 0 "Emergency brake light off" 1 "Emergency brake light on" ;
VAL_ 306 ESC_MasterCylinderPressureV 0 "Valid" 1 "Invalid" ;
VAL_ 306 ESC_HSA_Control_Status 0 "Inactive" 1 "Active" ;
VAL_ 306 ESC_HSA_Status_Fault 0 "HSA Normale" 1 "HSA Defective" ;
VAL_ 306 ESC_TcsDisableSts 0 "Enabled" 1 "Disabled" ;
VAL_ 306 ESC_EscCtrlActv 0 "Inactive" 1 "Active" ;
VAL_ 306 ESC_TcsCtrlActv 0 "Inactive" 1 "Active" ;
VAL_ 306 ESC_EscFlgFlt 0 "No failure" 1 "Failure" ;
VAL_ 306 ESC_TcsFlgFlt 0 "No failure" 1 "Failure" ;
VAL_ 306 ESC_EscDisableSts 0 "Enabled" 1 "Disabled" ;
VAL_ 306 ESC_HBAFlgFlt 0 "No failure" 1 "Failure" ;
VAL_ 306 ESC_HbaCtrlActv 0 "Inactive" 1 "Active" ;
VAL_ 306 BAS_FlgFlt 0 "No failure" 1 "Failure" ;
VAL_ 306 BAS_CtrlActv 0 "Inactive" 1 "Active" ;
VAL_ 306 IBS_ESCOFF_StsFB 0 "ESC enable" 1 "ESC forbid" ;
VAL_ 306 ESC_DTC_Active 0 "Inactive" 1 "Active" ;
VAL_ 306 ESC_VehicleStandstill 0 "Not Standstill" 1 "Standstill" 2 "Invalid" 3 "Reserved";
VAL_ 354 CVC_ModeGearSts 0 "Invalid" 1 "P" 2 "R" 3 "N" 4 "D" ;
VAL_ 354 CVC_P_Sts 0 "NO Action" 1 "Press" ;
VAL_ 354 CVC_IMMO_Sts 0 "Init" 1 "Pass" 2 "Fail" ;
VAL_ 354 CVC_Ready 0 "Not Ready" 1 "Ready" ;
VAL_ 354 CVC_RegencyLevInd 0 "OFF" 1 "LOW" 2 "MID" 3 "HIGH" ;
VAL_ 354 CVC_LimpHomeSts 0 "not in Limphome Mode" 1 "in Limphome Mode" ;
VAL_ 354 CVC_HVsystem_status 0 "Not ready" 1 "HV On" 2 "ReadyToDrive" 3 "Charging" 4 "Error" 5 "Reserved" 6 "Reserved" 7 "Reserved" ;
VAL_ 354 CVC_HV_DRVsystem_status 0 "Not available" 1 "Normal" 2 "Degration" 3 "Limphome" 4 "Error" 5 "Reserved" 6 "Reserved" 7 "Reserved" ;
VAL_ 358 CVC_DriveModeSts 0 "Invalid" 1 "Comfort Mode" 2 "Eco Mode" 3 "Sport Mode" ;
VAL_ 358 CVC_Fault 0 "No fault" 1 "FaultLeve 1" 2 "FaultLevel 2" 3 "Faultlevel3（Error）" ;
VAL_ 358 CVC_VecFltInd 0 "No fault" 1 "Fault" ;
VAL_ 358 CVC_Creep_Sts 0 "Invalid" 1 "Creep disable" 2 "Creep enable" 3 "Creep function fault" ;
VAL_ 358 CVC_CruiseCtrlSts 0 "Cruise OFF" 1 "Cruise ON" 2 "Cruise  activated" 3 "Cruise suspend" ;
VAL_ 358 CVC_StsBrakePedalSwitch 0 "Reserved" 1 "Not pressed" 2 "Pressed" 3 "Invalid" ;
VAL_ 358 CVC_CruiseFaultIndication 0 "No Fault" 1 "Pre-Condition not met" 2 "Function fault" ;
VAL_ 358 CVC_BEDrvInhibit 0 "No Request" 1 "Inhibit" 2 "Uninhibit" ;
VAL_ 1235 CVC_GearPOnlyAtStationaryAlert 0 "None" 1 "Alert" ;
VAL_ 1235 CVC_GearP_NotPossibleAlert 0 "None" 1 "Alert" ;
VAL_ 1235 CVC_PressBrakeToEngageGear 0 "None" 1 "Alert" ;
VAL_ 1235 CVC_CantChangeGear 0 "None" 1 "Alert" ;
VAL_ 1235 CVC_GearMalfunction 0 "None" 1 "Alert" ;
VAL_ 1235 CVC_RangeAlert 0 "None" 1 "Alert" ;
VAL_ 1235 CVC_HVSystemReduced 0 "None" 1 "Alert" ;
VAL_ 1235 CVC_FrontEDSReduced 0 "None" 1 "Alert" ;
VAL_ 1235 CVC_FrontEDS_Malfunc 0 "None" 1 "Alert" ;
VAL_ 1235 CVC_RearEDSReduced 0 "None" 1 "Alert" ;
VAL_ 1235 CVC_RearEDS_Malfunc 0 "None" 1 "Alert" ;
VAL_ 1235 CVC_CoolingSystem_Malfunc 0 "No fault" 1 "Level 1" 2 "Level 2" 3 "Level 3" 4 "Level 4" 5 "Reserved" 6 "Reserved" 7 "Invalid" ;
VAL_ 1235 CVC_NeutralRequest 0 "None" 1 "Alert" ;
VAL_ 1235 CVC_SoftShutdown 0 "None" 1 "Alert" ;
VAL_ 1235 CVC_EmergencyShutdown 0 "None" 1 "Alert" ;
VAL_ 1235 CVC_ChgPortDoorSys_Malfunc 0 "None" 1 "Alert" ;
VAL_ 1235 CVC_Gearchange_NotPossible 0 "None" 1 "Alert" ;
VAL_ 1235 CVC_12v_Warning 0 "None" 1 "Alert" ;
VAL_ 1235 CVC_WflagRes19 0 "None" 1 "Alert" ;
VAL_ 1235 CVC_WflagRes20 0 "None" 1 "Alert" ;
VAL_ 1235 CVC_WflagRes21 0 "None" 1 "Alert" ;
VAL_ 1235 CVC_WflagRes22 0 "None" 1 "Alert" ;
VAL_ 1235 CVC_WflagRes23 0 "None" 1 "Alert" ;
VAL_ 1235 CVC_WflagRes24 0 "None" 1 "Alert" ;
VAL_ 1235 CVC_WflagRes25 0 "None" 1 "Alert" ;
VAL_ 1235 CVC_WflagRes26 0 "None" 1 "Alert" ;
VAL_ 1235 CVC_WflagRes27 0 "None" 1 "Alert" ;
VAL_ 1235 CVC_SuperFastCharge_longer 0 "None" 1 "Alert" ;
VAL_ 1235 CVC_InvalidLimitSpeed 0 "None" 1 "Alert" ;
VAL_ 1235 CVC_InvalidCruiseSpeed 0 "None" 1 "Alert" ;
VAL_ 1873 CVC_DebugDiag2 0 "No Error" 1 "Error Level 1" 2 "Error Level 2" 3 "Error Level 3" 4 "Error Level 4" ;
VAL_ 1873 CVC_DebugDiag1 0 "No Error" 1 "Error Level 1" 2 "Error Level 2" 3 "Error Level 3" 4 "Error Level 4" ;
VAL_ 1873 CVC_DebugDiag5 0 "No Error" 1 "Error Level 1" 2 "Error Level 2" 3 "Error Level 3" 4 "Error Level 4" ;
VAL_ 1873 CVC_DebugDiag4 0 "No Error" 1 "Error Level 1" 2 "Error Level 2" 3 "Error Level 3" 4 "Error Level 4" ;
VAL_ 1873 CVC_DebugDiag3 0 "No Error" 1 "Error Level 1" 2 "Error Level 2" 3 "Error Level 3" 4 "Error Level 4" ;
VAL_ 1873 CVC_DebugDiag8 0 "No Error" 1 "Error Level 1" 2 "Error Level 2" 3 "Error Level 3" 4 "Error Level 4" ;
VAL_ 1873 CVC_DebugDiag7 0 "No Error" 1 "Error Level 1" 2 "Error Level 2" 3 "Error Level 3" 4 "Error Level 4" ;
VAL_ 1873 CVC_DebugDiag6 0 "No Error" 1 "Error Level 1" 2 "Error Level 2" 3 "Error Level 3" 4 "Error Level 4" ;
VAL_ 1873 CVC_DebugDiag10 0 "No Error" 1 "Error Level 1" 2 "Error Level 2" 3 "Error Level 3" 4 "Error Level 4" ;
VAL_ 1873 CVC_DebugDiag9 0 "No Error" 1 "Error Level 1" 2 "Error Level 2" 3 "Error Level 3" 4 "Error Level 4" ;
VAL_ 1873 CVC_DebugDiag13 0 "No Error" 1 "Error Level 1" 2 "Error Level 2" 3 "Error Level 3" 4 "Error Level 4" ;
VAL_ 1873 CVC_DebugDiag12 0 "No Error" 1 "Error Level 1" 2 "Error Level 2" 3 "Error Level 3" 4 "Error Level 4" ;
VAL_ 1873 CVC_DebugDiag11 0 "No Error" 1 "Error Level 1" 2 "Error Level 2" 3 "Error Level 3" 4 "Error Level 4" ;
VAL_ 1873 CVC_DebugDiag16 0 "No Error" 1 "Error Level 1" 2 "Error Level 2" 3 "Error Level 3" 4 "Error Level 4" ;
VAL_ 1873 CVC_DebugDiag15 0 "No Error" 1 "Error Level 1" 2 "Error Level 2" 3 "Error Level 3" 4 "Error Level 4" ;
VAL_ 1873 CVC_DebugDiag14 0 "No Error" 1 "Error Level 1" 2 "Error Level 2" 3 "Error Level 3" 4 "Error Level 4" ;
VAL_ 1873 CVC_DebugDiag18 0 "No Error" 1 "Error Level 1" 2 "Error Level 2" 3 "Error Level 3" 4 "Error Level 4" ;
VAL_ 1873 CVC_DebugDiag17 0 "No Error" 1 "Error Level 1" 2 "Error Level 2" 3 "Error Level 3" 4 "Error Level 4" ;
VAL_ 1873 CVC_DebugDiag20 0 "No Error" 1 "Error Level 1" 2 "Error Level 2" 3 "Error Level 3" 4 "Error Level 4" ;
VAL_ 1873 CVC_DebugDiag19 0 "No Error" 1 "Error Level 1" 2 "Error Level 2" 3 "Error Level 3" 4 "Error Level 4" ;
VAL_ 359 CVC_AccPedal_Valid 0 "Valid" 1 "Invalid" ;
VAL_ 359 CVC_StsAccPedalFault 0 "Valid" 1 "Invalid" ;
VAL_ 359 CVC_StsSysFault 0 "Init" 1 "Normal" 3 "Warning" 5 "Derating" 7 "Limphome" 9 "ZeroTorque" 11 "Powerdown" 13 "EmPowerdown" 14 "Invalid" ;
VAL_ 368 FMCU_MotorTempAlarm 0 "Not Alarm" 1 "Alarm" ;
VAL_ 368 FMCU_PowerReduceSts 0 "Not Reduced" 1 "Reduced" ;
VAL_ 368 FMCU_DragSts 0 "Normally drive" 1 "MCU fault and can be dragged" 2 "MCU fault and can not be dragged" ;
VAL_ 368 FMCU_HighVoltPowerOffReq 0 "No Request" 1 "Request" ;
VAL_ 372 BMS_StartOfMeasument_STS 0 "Not start" 1 "Started" ;
VAL_ 482 BCM_PowerState 0 "Normal OFF" 1 "Present_ON" 2 "No Present_ON" 3 "BOOT_ON" 4 "Reserve" 5 "Reserve" 6 "Reserve" 7 "Invaild" ;
VAL_ 482 PEPS_Learning_Status 0 "not learned" 1 "learned 1 key" 2 "learned 2 key" ;
VAL_ 482 PEPS_PowerModeValidity 0 "Not available" 1 "Invalid" 2 "Valid" ;
VAL_ 482 PEPS_PowerMode 0 "OFF" 1 "ACC" 2 "ON" 3 "OTA" 4 "START" ;
VAL_ 482 BCM_WPC_Off_Req 0 "No Request" 1 "Off" 2 "Reserve" ;
VAL_ 482 PEPS_CL15cRelayValidity 0 "Invalid" 1 "Valid" ;
VAL_ 482 PEPS_CL15cRelaySts 0 "Inactive" 1 "Active" ;
VAL_ 482 FL_PassiveEntryButton_Sts 0 "Not Pressed" 1 "Pressed" 2 "PE long press" 3"Fault (stuck)" ;
VAL_ 482 FR_PassiveEntryButton_Sts 0 "Not Pressed" 1 "Pressed" 2 "PE long press" 3"Fault (stuck)" ;
VAL_ 482 PEPS_CL30sRelaySts 0 "Inactive" 1 "Active" 2 "Reserved" 3"Invalid" ;
VAL_ 533 BMS_BatBalance_ERR 0 "Error" 1 "normal" ;
VAL_ 533 BMS_Balance_STS 0 "Inactive" 1 "active" ;
VAL_ 533 BMS_IGN_Sts 0 "OFF" 1 "ON" ;
VAL_ 533 BMS_HWCrash_Sts 0 "No Crash" 1 "Crash" ;
VAL_ 533 BMS_HVIL_STS 0 "Closed" 1 "Open & short to battery" 2 "short to ground" 3 "Signal invalid" ;
VAL_ 533 BMS_HVOnOff_STS 0 "HV Off" 1 "Precharge" 2 "HV On" 3 "Fail to HV on" ;
VAL_ 533 BMS_ERR_LEV 0 "No error" 1 "Warning" 2 "Limp Home" 3 "Power down without FTTI" 4 "Delay power down with FTTI" 5 "Emergency off condition" 6 "Fault, needs to shutdown and wakeup" 7 "Battery locked - reserved" ;
VAL_ 533 BMS_Sys_STS 0 "Initialization of power on, self-checking" 1 "Self-check passes, can be high-voltage" 2 "Successful High Voltage Power Up" 3 "Successful Power Down of HV" 4 "Power Down process" 5 "Successful Emergency Power Down" 6 "BCU Sleep mode" 7 "Failure, unable to operate" 8 "Invalid" ;
VAL_ 533 BMS_ISU_Status 0 "Normal (> 250 kOhms)" 1 "Level1 (<250 kOhms ~ >100 kOhms)" 3 "Level3 (<100 kOhms)" ;
VAL_ 533 BMS_HV_Sts 0 "HV Off" 1 "Pre Charge" 2 "HV On" 3 "Super_Fast_Charge" 4 "AC Charge" 5 "Undefined" 6 "Undefined" 7 "Undefined" 8 "Undefined" 9 "Undefined" ;
VAL_ 537 EVCC_OBC_StsModeReq 2 "Standby" 7 "DisCharge" 9 "Heating/Cooling" 10 "Charge allowed" 11 "ShutDown" ;
VAL_ 537 EVCC_S2_Sts 0 "CP open" 1 "S2 open" 2 "S2 Close" 7 "Invalid" ;
VAL_ 537 EVCC_StsChgCC 0 "CC open(CC open)" 1 "Half connection(S3 open)(Reserve)" 2 "1500Ω（DC Charge）" 3 "680Ω(16A）" 4 "220Ω(32A）" 5 "100Ω(63A）" 6 "Signal Fault" ;
VAL_ 544 CVC_BMS_PTCOnOff_Sts 0 "off" 1 "on" ;
VAL_ 544 CVC_BMS_PumpFB 0 "OFF" 1 "ON" 2 "Fault" 3 "Reserve" ;
VAL_ 549 CDM_bAcvCanComStblMon 0 "No error" 1 "Error" ;
VAL_ 549 FRMo_bErrHvbatStReqExtMon 0 "No error" 1 "Error" ;
VAL_ 549 FRMo_bErrChrgnAllwdExtMon 0 "No error" 1 "Error" ;
VAL_ 549 FRMo_bErrVehCrashStExtMon 0 "No error" 1 "Error" ;
VAL_ 549 CDM_bErrComctnLossCanMon 0 "No error" 1 "Error" ;
VAL_ 549 CTCMon_bErrCtctrSopcMon 0 "No error" 1 "Error" ;
VAL_ 549 CTCMon_bInvldCtctrHisdIFbMon 0 "No error" 1 "Error" ;
VAL_ 549 CTCMon_bInvldCtctrLosdUFbMon 0 "No error" 1 "Error" ;
VAL_ 549 CTM_bErrCellTDifMaxMon 0 "No error" 1 "Error" ;
VAL_ 549 CTM_bErrCellTMaxMon 0 "No error" 1 "Error" ;
VAL_ 549 CTM_bErrCellTMinMon 0 "No error" 1 "Error" ;
VAL_ 549 CTM_bErrThrwyPredMon 0 "No error" 1 "Error" ;
VAL_ 549 CUM_bErrCellUDifMaxMon 0 "No error" 1 "Error" ;
VAL_ 549 CUM_bErrCellUMaxMon 0 "No error" 1 "Error" ;
VAL_ 549 CUM_bErrCellUMinMon 0 "No error" 1 "Error" ;
VAL_ 549 CUM_bErrCellUProtnMaxNvMon 0 "No error" 1 "Error" ;
VAL_ 549 CUM_bErrCellUProtnMinNvMon 0 "No error" 1 "Error" ;
VAL_ 549 CUM_bErrPackUImplyMon 0 "No error" 1 "Error" ;
VAL_ 549 EHPMon_bRdyHvilMon 0 "No error" 1 "Error" ;
VAL_ 549 EHPMon_bErrWlddNegNvMon 0 "No error" 1 "Error" ;
VAL_ 549 EHPMon_bErrWlddPosNvMon 0 "No error" 1 "Error" ;
VAL_ 549 EHPMon_bErrWlddPrechNvMon 0 "No error" 1 "Error" ;
VAL_ 549 EHPMon_bErrHvilMon 0 "No error" 1 "Error" ;
VAL_ 549 EHPMon_bErrHvilShoMon 0 "No error" 1 "Error" ;
VAL_ 549 EHPMon_bErrPackIslnRNvMon 0 "No error" 1 "Error" ;
VAL_ 549 EHPMon_bErrVehCrashNvMon 0 "No error" 1 "Error" ;
VAL_ 549 EHPMon_bErrVehIslnRNvMon 0 "No error" 1 "Error" ;
VAL_ 549 FRMo_bErrMemStorgNvMon 0 "No error" 1 "Error" ;
VAL_ 549 L1IM_bErrClmp30MaxMonInp 0 "No error" 1 "Error" ;
VAL_ 549 L1IM_bErrClmp30MinMonInp 0 "No error" 1 "Error" ;
VAL_ 549 L1IM_bErrCtctrDtrtMonInp 0 "No error" 1 "Error" ;
VAL_ 549 L1IM_bErrUActImplyMonInp 0 "No error" 1 "Error" ;
VAL_ 549 MCCM_bAcvMdulCtlrStsMon 0 "No error" 1 "Error" ;
VAL_ 549 MCCM_bErrLntecSngFltMon 0 "No error" 1 "Error" ;
VAL_ 549 MCCM_bErrLntecLtntFltMon 0 "No error" 1 "Error" ;
VAL_ 549 MCCM_bErrMdulCellSnsrCfgMon 0 "No error" 1 "Error" ;
VAL_ 549 MCCM_bErrMdulCtlrComMon 0 "No error" 1 "Error" ;
VAL_ 549 MCCM_bErrSnsrTEltlMon 0 "No error" 1 "Error" ;
VAL_ 549 MCCM_bWarnSnsrTEltlMon 0 "No error" 1 "Error" ;
VAL_ 549 PCM_bRdySnsrIMon 0 "No error" 1 "Error" ;
VAL_ 549 PCM_bErrPackEFlowMaxLimMon 0 "No error" 1 "Error" ;
VAL_ 549 PCM_bErrPackIChDchaMaxLimMon 0 "No error" 1 "Error" ;
VAL_ 549 PCM_bErrSnsrIImplyMon 0 "No error" 1 "Error" ;
VAL_ 549 FRMo_bErrSnsrI1ExtMon 0 "No error" 1 "Error" ;
VAL_ 549 PCM_bInvldSnsrI1Mon 0 "No error" 1 "Error" ;
VAL_ 549 PCM_bInvldSnsrI2Mon 0 "No error" 1 "Error" ;
VAL_ 549 FRMo_bErrSopcLvl3Mon 0 "No error" 1 "Error" ;
VAL_ 549 BMS_FRMo_Reserved_1 0 "No error" 1 "Error" ;
VAL_ 549 BMS_FRMo_Reserved_2 0 "No error" 1 "Error" ;
VAL_ 549 BMS_FRMo_Reserved_3 0 "No error" 1 "Error" ;
VAL_ 549 BMS_FRMo_Reserved_4 0 "No error" 1 "Error" ;
VAL_ 549 BMS_FRMo_Reserved_5 0 "No error" 1 "Error" ;
VAL_ 550 BMS_QMMo_Reserved_0 0 "No error" 1 "Error" ;
VAL_ 550 BMS_QMMo_Reserved_1 0 "No error" 1 "Error" ;
VAL_ 550 BMS_QMMo_Reserved_2 0 "No error" 1 "Error" ;
VAL_ 550 BMS_QMMo_Reserved_3 0 "No error" 1 "Error" ;
VAL_ 550 BMS_QMMo_Reserved_4 0 "No error" 1 "Error" ;
VAL_ 550 BMS_QMMo_Reserved_5 0 "No error" 1 "Error" ;
VAL_ 550 BMS_QMMo_Reserved_6 0 "No error" 1 "Error" ;
VAL_ 550 BMS_QMMo_Reserved_7 0 "No error" 1 "Error" ;
VAL_ 550 BMS_QMMo_Reserved_8 0 "No error" 1 "Error" ;
VAL_ 550 BMS_QMMo_Reserved_9 0 "No error" 1 "Error" ;
VAL_ 550 BMS_QMMo_Reserved_10 0 "No error" 1 "Error" ;
VAL_ 550 BMS_QMMo_Reserved_11 0 "No error" 1 "Error" ;
VAL_ 564 CVC_DCDC_StsModeReq 0 "Inactive" 1 "Buck" 2 "Active Discharge(Reserve)" ;
VAL_ 564 CVC_enableDCDC 0 "Request OFF" 1 "Request ON" ;
VAL_ 568 FMCU_DampingState 0 "Damping disable" 1 "Damping active" ;
VAL_ 568 FMCU_IGBTState 0 "shutdown" 1 "Entering ASC from the upper bridge arm" 2 "Enter ASC from the lower bridge arm" 3 "normal work" ;
VAL_ 581 BMS_ProbeNumMaxCellTemp 0 "Invalid" 62 "Error" 63 "Invalid" ;
VAL_ 581 BMS_ProbeNumMinCellTemp 0 "Invalid" 62 "Error" 63 "Invalid" ;
VAL_ 584 BMS_CVC_PTCOnOff_Req 0 "OFF" 1 "ON" ;
VAL_ 584 BMS_CVC_ValveOnOff_Req 0 "close" 1 "open" ;
VAL_ 584 BMS_PreHeatCoolReq 0 "Precondition OFF" 1 "Precondition Heating ON" 2 "Precondition Cooling ON" 3 "Invalid value" ;
VAL_ 593 EVCC_ChargeMode 0 "init" 1 "DC Charging" 2 "Normal AC charge(PWM)" 3 "PLC AC charging" ;
VAL_ 593 EVCC_StsElock 0 "Unlock" 1 "Lock" 2 "Lock Fault" 3 "Invalid" ;
VAL_ 593 EVCC_PP_Sts 0 "No connection" 1 "Half connection" 2 "1500Ω (DC charge)" 3 "680Ω(Charge gun,16A)" 4 "220Ω(Charge gun,32A)" 5 "100Ω(Charge gun,63A)" 6 "GND" 7 "2000Ω(Discharge gun,16A)" 8 "2700Ω(Discharge gun,10A)" 9 "1000Ω(Discharge gun,32A)" 10 "470Ω(Discharge gun,63A)" ;
VAL_ 593 EVCC_S2_Sts 0 "CP open" 1 "S2 open" 2 "S2 Close" 7 "Invalid" ;
VAL_ 593 EVCC_CCS2_CPSts 0 "State A(+12V)" 1 "State B(+9V)" 2 "State C(+6V)" 3 "State D(+3V)" 4 "State E(+0V)" 5 "State F(-12V)" ;
VAL_ 662 DCDC_StsCtrl 0 "Inactive" 1 "Buck" 2 "Bost(Reserve)" 3 "Active Discharge(Reserve)" ;
VAL_ 662 DCDC_StsDCDCFault 0 "Normal" 1 "Derating" 2 "Shutdown" 3 "Invalid" ;
VAL_ 662 PDU_HVIL_Status 0 "Normal" 1 "Error" 2 "Reserved" 3 "Invalid" ;
VAL_ 662 PDU_DCNegRelay_Sts 0 "Init" 1 "Open" 2 "Closed" 3 "Adhesion" ;
VAL_ 662 PDU_DCPosRelay_Sts 0 "Init" 1 "Open" 2 "Closed" 3 "Adhesion" ;
VAL_ 663 DCDC_CVC_OverTemp 0 "Normal" 1 "OverTemp Level 1" 2 "OverTemp Level 2" 3 "Reserved" ;
VAL_ 663 DCDC_HWFault 0 "Normal" 1 "Error" ;
VAL_ 663 DCDC_OutPwrOver 0 "Normal" 1 "Error" ;
VAL_ 663 DCDC_OutCurOver 0 "Normal" 1 "Error" ;
VAL_ 663 DCDC_OutVoltOver 0 "Normal" 1 "Error" ;
VAL_ 663 DCDC_OutVoltUnder 0 "Normal" 1 "Error" ;
VAL_ 663 DCDC_InVoltOver 0 "Normal" 1 "Error" ;
VAL_ 663 DCDC_InVoltUnder 0 "Normal" 1 "Error" ;
VAL_ 663 DCDC_OutCircuitShort 0 "Normal" 1 "Error" ;
VAL_ 663 DCDC_OutHWOpen 0 "Normal" 1 "Error" ;
VAL_ 663 DCDC_InternalCommFault 0 "Normal" 1 "Error" ;
VAL_ 663 DCDC_CVCLostFault 0 "Normal" 1 "Error" ;
VAL_ 663 DCDC_CANBusoffFault 0 "Normal" 1 "Error" ;
VAL_ 663 DCDC_WakeupInMissing 0 "Normal" 1 "Error" ;
VAL_ 663 DCDC_12VFault 0 "Normal" 1 "Error" ;
VAL_ 664 OBC_InvertDCCurrlnOC 0 "Normal" 1 "Error" ;
VAL_ 664 OBC_InvertDCVoltlnUV 0 "Normal" 1 "Error" ;
VAL_ 664 OBC_InvertDCVoltlnOV 0 "Normal" 1 "Error" ;
VAL_ 664 OBC_InvertVoltPfcUV 0 "Normal" 1 "Error" ;
VAL_ 664 OBC_InvertVoltPfcOV 0 "Normal" 1 "Error" ;
VAL_ 664 OBC_InvertAcCurrOutOC 0 "Normal" 1 "Error" ;
VAL_ 664 OBC_InvertAcVoltOutOV 0 "Normal" 1 "Error" ;
VAL_ 664 OBC_InvertAcVoltOutUV 0 "Normal" 1 "Error" ;
VAL_ 664 OBC_InvertOTRedu 0 "Normal" 1 "Error" ;
VAL_ 664 OBC_InvertOTShut 0 "Normal" 1 "Error" ;
VAL_ 694 DCDC_Err_Lvl 0 "No Fault" 1 "Level1-slight fault" 2 "Level2-Minor fault" 3 "Level3-General fault" 4 "Level4-Serious fault" 5 "Level5-Fatal fault" ;
VAL_ 694 OBC_StsMode 0 "OBC_OFF" 1 "OBC_STANDBY" 2 "OBC_ON_NORMAL" 3 "OBC_ON_VOLTAGE" 4 "OBC_DEGRADED" 5 "OBC_FAULT_SHUTDOWN" 6 "OBC_EMERGENCY_SHUTDOWN" 7 "OBC_STS_SNA" ;
VAL_ 694 OBC_BMS_ChgFaultReq 0 "Normal" 2 "Derating" 3 "Recover Prohibit Charge" 6 "Powerdown" ;
VAL_ 694 OBC_Err_Lvl 0 "No Fault" 1 "Level1-slight fault" 2 "Level2-Minor fault" 3 "Level3-General fault" 4 "Level4-Serious fault" 5 "Level5-Fatal fault" ;
VAL_ 694 POD_phaseACInput 1 "AC 1 phase input" 3 "AC 3 phase input" ;
VAL_ 694 POD_statusDCDC 0 "DCDC_OFF" 1 "DCDC_STANDBY" 2 "DCDC_ON" 3 "DCDC_RESERVED" 4 "DCDC_DEGRADED" 5 "DCDC_FAULT_SHUTDOWN" 6 "DCDC_EMERGENCY_SHUTDOWN" 7 "DCDC_STS_SNA" ;
VAL_ 746 CVC_Fan_Sts 0 "Closed" 1 "Low Speed" 2 "High speed" ;
VAL_ 746 CVC_EdrivePump_Sts 0 "Not Work" 1 "Working" 2 "Fault" ;
VAL_ 746 CVC_BatPump_Sts 0 "Not Work" 1 "Working" 2 "Fault" ;
VAL_ 773 BMS_CVC_Insulation_Mon_Sts 0 "ON" 1 "OFF" ;
VAL_ 775 BMS_Start_Stop_DM13 0 "Stop" 1 "Start" 2 "Reserved" 3 "Don't care/take no action" ;
VAL_ 807 IVI_RearBlowerLevelSet 0 "OFF" 1 "level 1" 2 "level 2" 3 "level 3" 4 "level 4" 5 "level 5" 6 "level 6" 7 "Invalid" ;
VAL_ 807 IVI_BlowerLevelSet 0 "OFF" 1 "level 1" 2 "level 2" 3 "level 3" 4 "level 4" 5 "level 5" 6 "level 6" 7 "level 7" 8 "level 8" 9 "Invalid" ;
VAL_ 807 IVI_SetBlowMode 0 "Neutral" 1 "face" 2 "foot and face" 3 "Foot" 4 "Foot and window" 5 "Window" 6 "Reserve" 7 "Invalid" ;
VAL_ 807 IVI_FrontDefrostReq 0 "No Request" 1 "Request ON" 2 "Request OFF" 3 "Invalid" ;
VAL_ 807 IVI_Recirculation 0 "No Request" 1 "Inside" 2 "Outside" 3 "Invalid" ;
VAL_ 807 IVI_PM2_5_Req 0 "No Request" 1 "Request ON" 2 "Request OFF" 3 "Invalid" ;
VAL_ 807 IVI_MaxAC 0 "No Request" 1 "Request ON" 2 "Request OFF" 3 "Invalid" ;
VAL_ 807 IVI_MaxDefrost 0 "No Request" 1 "Request ON" 2 "Request OFF" 3 "Invalid" ;
VAL_ 807 IVI_AutoAC_OnOff 0 "No Request" 1 "Request ON" 2 "Request OFF" 3 "Invalid" ;
VAL_ 807 IVI_AC_OnOff_Req 0 "No Request" 1 "Request ON" 2 "Request OFF" 3 "Invalid" ;
VAL_ 807 IVI_RearAC_OnOff_Req 0 "No Request" 1 "Request ON" 2 "Request OFF" 3 "Invalid" ;
VAL_ 811 CCU_PTC_Req 0 "No requset" 1 "Requset" 3 "Invalid" ;
VAL_ 811 CCU_AC_Req 0 "No requset" 1 "Requset" 3 "Invalid" ;
VAL_ 811 CCU_BlowerRelaySts 0 "Invalid" 1 "OFF" 2 "ON" ;
VAL_ 811 CCU_RearBlowerRelaySts 0 "Invalid" 1 "OFF" 2 "ON" ;
VAL_ 811 CCU_AUTO_Status 0 "OFF" 1 "ON" ;
VAL_ 811 CCU_FrontDefrostSts 0 "OFF" 1 "ON" ;
VAL_ 811 CCU_AC_Sts 0 "OFF" 1 "ON" ;
VAL_ 811 CCU_Circulation_Sts 0 "Outer circulation" 1 "Internal circulation" ;
VAL_ 811 CCU_ExternalTemperatureFailSts 0 "valid" 1 "invalid" ;
VAL_ 811 CCU_RearAC_Sts 0 "OFF" 1 "ON" ;
VAL_ 811 CCU_MaxAC_Sts 0 "OFF" 1 "ON" ;
VAL_ 811 CCU_PTC_Relay_Status 0 "OFF" 1 "ON" 2 "Reserved" 3 "Invalid";
VAL_ 812 CCU_Rear_Blower_Sts 0 "OFF" 1 "level 1" 2 "level 2" 3 "level 3" 4 "level 4" 5 "level 5" 6 "level 6" 7 "Reserved" 15 "Invalid" ;
VAL_ 812 CCU_BlowMode_Sts 0 "OFF" 1 "Face" 2 "Foot and Face" 3 "Foot" 4 "Foot and window" 5 "Window" 6 "Reserve" 7 "Invalid" ;
VAL_ 812 CCU_Dr_Side_BlowerLevelSts 0 "OFF" 1 "level 1" 2 "level 2" 3 "level 3" 4 "level 4" 5 "level 5" 6 "level 6" 7 "level 7" 8 "level 8" 31 "Invalid" ;
VAL_ 816 BMS_ContactorAging 0 "Normal" 1 "Warning counter reach 90%" 2 "Fault counter reach 98%" ;
VAL_ 817 CCH_Rear_Blower_Increase 0 "Touch" 1 "Untouch" ;
VAL_ 817 CCH_Rear_Blower_Decrease 0 "Touch" 1 "Untouch" ;
VAL_ 817 CCH_RearAC_OnOff_Req 0 "Rear SOV OFF" 1 "Rear SOV ON" ;
VAL_ 815 CVC_RearBlowerRelay_Req 0 "No Action" 1 "OFF" 2 "ON" 3 "Invalid";
VAL_ 815 CVC_BlowerRelay_Req 0 "No Action" 1 "OFF" 2 "ON" 3 "Invalid" ;
VAL_ 815 CVC_PTC_Relay_Request 0 "OFF" 1 "ON" 2 "Reserved" 3 "Invalid" ;
VAL_ 822 CVC_FrontBlower_Level 0 "OFF" 1 "Level 1" 2 "Level 2" 3 "Level 3" 4 "Level 4" 5 "Level 5" 6 "Level 6" 7"Level 7" 8 "Level 8" ;
VAL_ 822 CVC_RearBlower_Level 0 "OFF" 1 "Level 1" 2 "Level 2" 3 "Level 3" 4 "Level 4" 5 "Level 5" 6 "Level 6" ;
VAL_ 822 CVC_BlowMode_Sts 0 "OFF" 1 "Face" 2 "Foot and Face" 3 "Foot" 4 "Foot and Window" 5 "Window" 6 "Reserved" ;
VAL_ 822 CVC_Recirculation_Status 0 "outer circulation" 1 "Internal circulation" ;
VAL_ 822 CVC_CabinThermalMode 0 "OFF" 1 "Manual mode (AC only)" 2 "Auto mode" 3 "MAX AC" 4 "Defrost" 5 "Reserved" 6 "Reserved" ;
VAL_ 822 CVC_RearAC_Sts 0 "OFF" 1 "ON" 2 "Reserved" 3 "Invalid" ;
VAL_ 822 CVC_HVAC_Managment 0 "OFF" 1 "COOLING" 2 "HEATING" 3 "REHEAT" ;
